VERSION "HNNBNNNYNNNNNNNNNNNNNNNNNNNNNNNNNNNNNNNNNN/4/%%%/4/'%**4NNN///"

NS_ :

BS_:

BU_: ADR_PAG_X2 BAP_Tester GW_App_PAG_PF GW_Routing_PAG_PF Klima_PAG_PF Klimakomp_Dash_PAG_PF Kombi_PAG_PF Miko_PAG_X2 OCU_PAG_PF RDK_High_PAG_PF

BO_ 192 ADR_01_PAG: 8 ADR_PAG_X2
 SG_ Adr_Clima_Mono : 0|1@1+ (1,0) [0|1] ""  Miko_PAG_X2
 SG_ Adr_T_LVT_O : 1|1@1+ (1,0) [0|1] "" Vector__XXX
 SG_ Adr_T_LVT_M : 2|1@1+ (1,0) [0|1] "" Vector__XXX
 SG_ Adr_T_LVT_U : 3|1@1+ (1,0) [0|1] "" Vector__XXX
 SG_ Adr_AC_Menue_LED_an : 4|1@1+ (1,0) [0|1] ""  Miko_PAG_X2
 SG_ Adr_Phone_LED_an : 5|1@1+ (1,0) [0|1] ""  Miko_PAG_X2
 SG_ Adr_Media_LED_an : 6|1@1+ (1,0) [0|1] ""  Miko_PAG_X2
 SG_ Adr_Tuner_LED_an : 7|1@1+ (1,0) [0|1] ""  Miko_PAG_X2
 SG_ Adr_Car_LED_an : 8|1@1+ (1,0) [0|1] ""  Miko_PAG_X2
 SG_ Adr_Info_LED_an : 9|1@1+ (1,0) [0|1] ""  Miko_PAG_X2
 SG_ Adr_Navi_LED_an : 10|1@1+ (1,0) [0|1] ""  Miko_PAG_X2
 SG_ Adr_Alive_Cnt : 11|4@1+ (1,0) [0|15] ""  Miko_PAG_X2
 SG_ Adr_Pos_En : 15|1@1+ (1,0) [0|1] ""  Miko_PAG_X2
 SG_ Adr_Display_Status : 16|1@1+ (1,0) [0|1] ""  Miko_PAG_X2
 SG_ Adr_Active_Character_Page : 17|4@1+ (1,0) [0|15] ""  Miko_PAG_X2
 SG_ Adr_Chr_Mode : 40|8@1+ (1,0) [0|255] ""  Miko_PAG_X2
 SG_ Adr_Gst_Mode : 48|16@1+ (1,0) [0|65535] ""  Miko_PAG_X2

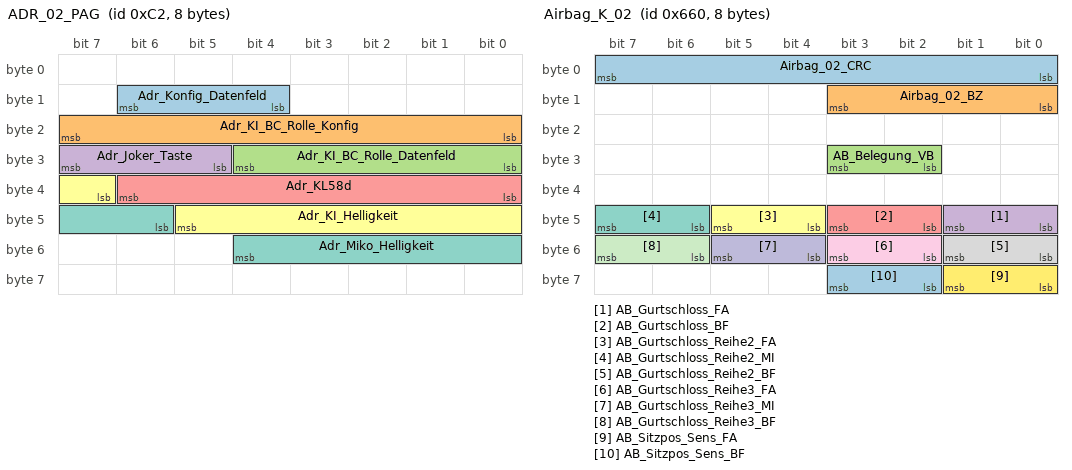
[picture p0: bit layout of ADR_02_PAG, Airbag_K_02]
BO_ 194 ADR_02_PAG: 8 ADR_PAG_X2
 SG_ Adr_Konfig_Datenfeld : 12|3@1+ (1,0) [0|7] ""  Kombi_PAG_PF
 SG_ Adr_KI_BC_Rolle_Konfig : 16|8@1+ (1,0) [0|255] ""  Kombi_PAG_PF
 SG_ Adr_KI_BC_Rolle_Datenfeld : 24|5@1+ (1,0) [0|31] ""  Kombi_PAG_PF
 SG_ Adr_Joker_Taste : 29|3@1+ (1,0) [0|7] ""  Kombi_PAG_PF
 SG_ Adr_KL58d : 32|7@1+ (1,0) [0|100] "Unit_PerCent"  Kombi_PAG_PF
 SG_ Adr_KI_Helligkeit : 39|7@1+ (1,0) [0|100] "Unit_PerCent"  Kombi_PAG_PF
 SG_ Adr_Miko_Helligkeit : 46|7@1+ (1,0) [0|100] "Unit_PerCent"  Miko_PAG_X2

BO_ 64 Airbag_01: 8 GW_Routing_PAG_PF
 SG_ Airbag_01_CHK : 0|8@1+ (1,0) [0|255] "" Vector__XXX
 SG_ Airbag_01_BZ : 8|4@1+ (1,0) [0|15] "" Vector__XXX
 SG_ AB_RGS_Anst : 12|4@1+ (1,0) [0|15] "" Vector__XXX
 SG_ AB_Front_Crash : 16|1@1+ (1,0) [0|1] "" Vector__XXX
 SG_ AB_Heck_Crash : 17|1@1+ (1,0) [0|1] "" Vector__XXX
 SG_ AB_SF_Crash : 18|1@1+ (1,0) [0|1] "" Vector__XXX
 SG_ AB_SB_Crash : 19|1@1+ (1,0) [0|1] "" Vector__XXX
 SG_ AB_Rollover_Crash : 20|1@1+ (1,0) [0|1] "" Vector__XXX
 SG_ AB_Crash_Int : 21|3@1+ (1,0) [0|7] "" Vector__XXX
 SG_ AB_Lampe : 24|1@1+ (1,0) [0|1] ""  Kombi_PAG_PF
 SG_ AB_Deaktiviert : 25|1@1+ (1,0) [0|1] "" Vector__XXX
 SG_ AB_VB_deaktiviert : 26|1@1+ (1,0) [0|1] ""  Kombi_PAG_PF
 SG_ AB_Systemfehler : 27|1@1+ (1,0) [0|1] ""  Kombi_PAG_PF
 SG_ AB_Diagnose : 28|1@1+ (1,0) [0|1] "" Vector__XXX
 SG_ AB_Stellgliedtest : 29|1@1+ (1,0) [0|1] "" Vector__XXX
 SG_ AB_Erh_Auf_VB : 30|2@1+ (1,0) [0|3] "" Vector__XXX
 SG_ AB_Gurtwarn_VF : 32|1@1+ (1,0) [0|1] ""  Kombi_PAG_PF
 SG_ AB_Gurtwarn_VB : 33|1@1+ (1,0) [0|1] ""  Kombi_PAG_PF
 SG_ AB_Anzeige_Fussg : 34|2@1+ (1,0) [0|3] ""  Kombi_PAG_PF
 SG_ AB_Texte_AKS : 36|2@1+ (1,0) [0|3] "" Vector__XXX
 SG_ AB_PAO_Leuchte_Anf : 38|1@1+ (1,0) [0|1] "" Vector__XXX
 SG_ AB_MKB_gueltig : 39|1@1+ (1,0) [0|1] "" Vector__XXX
 SG_ AB_Versorgungsspannung : 41|1@1+ (1,0) [0|1] "" Vector__XXX
 SG_ AB_Deaktivierung_HV : 42|3@1+ (1,0) [0|7] "" Vector__XXX
 SG_ AB_EDR_Trigger : 45|2@1+ (1,0) [0|3] "" Vector__XXX
 SG_ AB_KD_Fehler : 63|1@1+ (1,0) [0|1] "" Vector__XXX

BO_ 1632 Airbag_K_02: 8 GW_Routing_PAG_PF
 SG_ Airbag_02_CRC : 0|8@1+ (1,0) [0|255] "" Vector__XXX
 SG_ Airbag_02_BZ : 8|4@1+ (1,0) [0|15] "" Vector__XXX
 SG_ AB_Belegung_VB : 26|2@1+ (1,0) [0|3] "" Vector__XXX
 SG_ AB_Gurtschloss_FA : 40|2@1+ (1,0) [0|3] ""  Kombi_PAG_PF
 SG_ AB_Gurtschloss_BF : 42|2@1+ (1,0) [0|3] "" Vector__XXX
 SG_ AB_Gurtschloss_Reihe2_FA : 44|2@1+ (1,0) [0|3] "" Vector__XXX
 SG_ AB_Gurtschloss_Reihe2_MI : 46|2@1+ (1,0) [0|3] "" Vector__XXX
 SG_ AB_Gurtschloss_Reihe2_BF : 48|2@1+ (1,0) [0|3] "" Vector__XXX
 SG_ AB_Gurtschloss_Reihe3_FA : 50|2@1+ (1,0) [0|3] "" Vector__XXX
 SG_ AB_Gurtschloss_Reihe3_MI : 52|2@1+ (1,0) [0|3] "" Vector__XXX
 SG_ AB_Gurtschloss_Reihe3_BF : 54|2@1+ (1,0) [0|3] "" Vector__XXX
 SG_ AB_Sitzpos_Sens_FA : 56|2@1+ (1,0) [0|3] "" Vector__XXX
 SG_ AB_Sitzpos_Sens_BF : 58|2@1+ (1,0) [0|3] "" Vector__XXX

BO_ 1490 BAP_ASG_12: 8 OCU_PAG_PF
 SG_ BAP_D2_Header : 0|8@1+ (1,0) [0|255] ""  GW_Routing_PAG_PF

BO_ 1491 BAP_ASG_13: 8 Kombi_PAG_PF
 SG_ BAP_D3_Header : 0|8@1+ (1,0) [0|255] ""  GW_Routing_PAG_PF

BO_ 1492 BAP_ASG_14: 8 GW_Routing_PAG_PF
 SG_ BAP_D4_Header : 0|8@1+ (1,0) [0|255] ""  Kombi_PAG_PF

BO_ 1493 BAP_ASG_15: 8 OCU_PAG_PF
 SG_ BAP_D5_Header : 0|8@1+ (1,0) [0|255] ""  Kombi_PAG_PF

BO_ 1565 BAP_BatteryControl: 8 GW_Routing_PAG_PF
 SG_ BAP_1D_Header : 0|8@1+ (1,0) [0|255] ""  Kombi_PAG_PF,OCU_PAG_PF

BO_ 1599 BAP_Debug_Cmd: 8 BAP_Tester
 SG_ BAP_Debug_Cmd : 0|16@1+ (1,0) [0|65535] ""  Kombi_PAG_PF,OCU_PAG_PF

BO_ 1598 BAP_Debug_Data: 8 Kombi_PAG_PF
 SG_ BAP_Debug_Data : 0|64@1+ (1,0) [0|1.84467440737096E+019] ""  BAP_Tester

BO_ 1583 BAP_Uhrzeit: 8 Kombi_PAG_PF
 SG_ BAP_2F_Header : 0|8@1+ (1,0) [0|255] ""  GW_Routing_PAG_PF,OCU_PAG_PF

BO_ 1634 BCM1_02: 8 GW_Routing_PAG_PF
 SG_ BCM1_Bremsbelag_Warn : 0|1@1+ (1,0) [0|1] "" Vector__XXX
 SG_ BCM1_Bremsfluessigkeit_Warn : 1|1@1+ (1,0) [0|1] ""  Kombi_PAG_PF
 SG_ BCM1_Licht_Warn : 2|1@1+ (1,0) [0|1] ""  Kombi_PAG_PF
 SG_ BCM1_Waschwasser_Warn : 3|1@1+ (1,0) [0|1] ""  Kombi_PAG_PF
 SG_ BCM1_Kuehlmittel_Warn : 4|1@1+ (1,0) [0|1] "" Vector__XXX
 SG_ BCM1_Gleitende_Leuchtw_Anf : 5|1@1+ (1,0) [0|1] "" Vector__XXX
 SG_ LV_Aussenlicht_def : 6|1@1+ (1,0) [0|1] ""  Kombi_PAG_PF
 SG_ LV_AFL_defekt : 7|1@1+ (1,0) [0|1] ""  Kombi_PAG_PF
 SG_ BCM1_Handbremse_Schalter : 8|1@1+ (1,0) [0|1] "" Vector__XXX
 SG_ BCM1_MH_Schalter : 9|1@1+ (1,0) [0|1] ""  Kombi_PAG_PF,OCU_PAG_PF
 SG_ BCM1_MH_WIV_Schalter : 10|1@1+ (1,0) [0|1] "" Vector__XXX
 SG_ BCM1_Oeldruck_Schalter : 11|1@1+ (1,0) [0|1] "" Vector__XXX
 SG_ BCM1_Kl_15_HW_erkannt : 12|1@1+ (1,0) [0|1] "" Vector__XXX
 SG_ BCM1_Lenksaeule_aktiv : 13|1@1+ (1,0) [0|1] "" Vector__XXX
 SG_ BCM1_Oeldruck_Schalter_2 : 14|1@1+ (1,0) [0|1] "" Vector__XXX
 SG_ BCM1_SRA_aktiv : 15|1@1+ (1,0) [0|1] "" Vector__XXX
 SG_ LV_Standlicht_Anzeige : 16|1@1+ (1,0) [0|1] ""  ADR_PAG_X2,Kombi_PAG_PF
 SG_ LV_Abblendlicht_Anzeige : 17|1@1+ (1,0) [0|1] ""  Kombi_PAG_PF
 SG_ LV_Fernlicht_Anzeige : 18|1@1+ (1,0) [0|1] ""  Kombi_PAG_PF
 SG_ LV_Nebellicht_Anzeige : 19|1@1+ (1,0) [0|1] "" Vector__XXX
 SG_ LV_Nebelschlusslicht_Anzeige : 20|1@1+ (1,0) [0|1] ""  Kombi_PAG_PF
 SG_ LV_Tagfahrlicht_Anzeige : 21|1@1+ (1,0) [0|1] ""  Kombi_PAG_PF
 SG_ LV_AFL_aktiv_Anzeige : 22|1@1+ (1,0) [0|1] "" Vector__XXX
 SG_ BCM1_Licht_Dunkelheit_aktiv : 23|1@1+ (1,0) [0|1] "" Vector__XXX
 SG_ LV_Blinker_li_def : 24|1@1+ (1,0) [0|1] ""  Kombi_PAG_PF
 SG_ LV_Standlicht_li_def : 25|1@1+ (1,0) [0|1] ""  Kombi_PAG_PF
 SG_ LV_Abblendlicht_li_def : 26|1@1+ (1,0) [0|1] ""  Kombi_PAG_PF
 SG_ LV_Fernlicht_li_def : 27|1@1+ (1,0) [0|1] ""  Kombi_PAG_PF
 SG_ LV_Nebellicht_li_def : 28|1@1+ (1,0) [0|1] ""  Kombi_PAG_PF
 SG_ LV_Blk_li_Seite_def : 29|1@1+ (1,0) [0|1] ""  Kombi_PAG_PF
 SG_ LV_Tagfahrlicht_li_def : 30|1@1+ (1,0) [0|1] "" Vector__XXX
 SG_ BCM1_GLW_Fernlicht_Anf : 31|1@1+ (1,0) [0|1] "" Vector__XXX
 SG_ LV_Abblendlicht_TFL_li_def : 32|1@1+ (1,0) [0|1] "" Vector__XXX
 SG_ LV_Nebellicht_TFL_li_def : 33|1@1+ (1,0) [0|1] "" Vector__XXX
 SG_ LV_Standlicht_TFL_li_def : 34|1@1+ (1,0) [0|1] "" Vector__XXX
 SG_ LV_Abblend_Fernlicht_li_def : 35|1@1+ (1,0) [0|1] "" Vector__XXX
 SG_ LV_FLA_aktiv_Anzeige : 36|1@1+ (1,0) [0|1] ""  Kombi_PAG_PF
 SG_ LV_FLA_defekt : 37|1@1+ (1,0) [0|1] ""  Kombi_PAG_PF
 SG_ LV_FLA_Sensor_blockiert : 38|1@1+ (1,0) [0|1] ""  Kombi_PAG_PF
 SG_ BCM1_EasyEntry_Status : 39|1@1+ (1,0) [0|1] "" Vector__XXX
 SG_ LV_Blinker_re_def : 40|1@1+ (1,0) [0|1] ""  Kombi_PAG_PF
 SG_ LV_Standlicht_re_def : 41|1@1+ (1,0) [0|1] ""  Kombi_PAG_PF
 SG_ LV_Abblendlicht_re_def : 42|1@1+ (1,0) [0|1] ""  Kombi_PAG_PF
 SG_ LV_Fernlicht_re_def : 43|1@1+ (1,0) [0|1] ""  Kombi_PAG_PF
 SG_ LV_Nebellicht_re_def : 44|1@1+ (1,0) [0|1] ""  Kombi_PAG_PF
 SG_ LV_Blk_re_Seite_def : 45|1@1+ (1,0) [0|1] ""  Kombi_PAG_PF
 SG_ LV_Tagfahrlicht_re_def : 46|1@1+ (1,0) [0|1] "" Vector__XXX
 SG_ BCM1_Adaptive_Lichtvert_Anf : 47|1@1+ (1,0) [0|1] "" Vector__XXX
 SG_ LV_Abblendlicht_TFL_re_def : 48|1@1+ (1,0) [0|1] "" Vector__XXX
 SG_ LV_Nebellicht_TFL_re_def : 49|1@1+ (1,0) [0|1] "" Vector__XXX
 SG_ LV_Standlicht_TFL_re_def : 50|1@1+ (1,0) [0|1] "" Vector__XXX
 SG_ LV_Abblend_Fernlicht_re_def : 51|1@1+ (1,0) [0|1] "" Vector__XXX
 SG_ BCM1_EasyEntry_texte : 52|2@1+ (1,0) [0|3] "" Vector__XXX
 SG_ HYB_Anf_E_Mode : 54|1@1+ (1,0) [0|1] "" Vector__XXX
 SG_ UGDO_Function : 56|3@1+ (1,0) [0|7] "" Vector__XXX
 SG_ UGDO_LED_Code : 59|5@1+ (1,0) [0|31] "" Vector__XXX

BO_ 1697 BCM1_03_PAG: 8 GW_Routing_PAG_PF
 SG_ BCM1_W_ELV : 0|1@1+ (1,0) [0|1] ""  Kombi_PAG_PF
 SG_ BCM1_W_Blinker_HR_def : 1|1@1+ (1,0) [0|1] ""  Kombi_PAG_PF
 SG_ BCM1_W_Blinker_HL_def : 2|1@1+ (1,0) [0|1] ""  Kombi_PAG_PF
 SG_ BCM1_W_LWR_def : 3|1@1+ (1,0) [0|1] ""  Kombi_PAG_PF
 SG_ BCM1_W_Parklicht : 4|1@1+ (1,0) [0|1] ""  Kombi_PAG_PF
 SG_ BCM1_ZV_Horn : 5|2@1+ (1,0) [0|3] "" Vector__XXX
 SG_ BCM1_St_ZV : 8|3@1+ (1,0) [0|7] ""  Klima_PAG_PF,OCU_PAG_PF
 SG_ BCM1_FSH_aktiv : 11|1@1+ (1,0) [0|1] ""  Klima_PAG_PF
 SG_ BCM1_Kurvenlicht_li_Anf : 12|1@1+ (1,0) [0|1] "" Vector__XXX
 SG_ BCM1_Kurvenlicht_re_Anf : 13|1@1+ (1,0) [0|1] "" Vector__XXX
 SG_ BCM1_DWA_Anf : 14|2@1+ (1,0) [0|3] "" Vector__XXX
 SG_ LDS_TF_Licht : 16|1@1+ (1,0) [0|1] "" Vector__XXX
 SG_ LDS_AF_Licht : 17|1@1+ (1,0) [0|1] "" Vector__XXX
 SG_ LDS_STA_Licht : 18|1@1+ (1,0) [0|1] "" Vector__XXX
 SG_ LDS_Fahr_Licht : 19|1@1+ (1,0) [0|1] "" Vector__XXX
 SG_ LDS_Error : 20|1@1+ (1,0) [0|1] "" Vector__XXX
 SG_ LDS_N_Licht : 21|1@1+ (1,0) [0|1] "" Vector__XXX
 SG_ LDS_NS_Licht : 22|1@1+ (1,0) [0|1] "" Vector__XXX
 SG_ LDS_Nightvision : 23|1@1+ (1,0) [0|1] "" Vector__XXX
 SG_ BCM1_Geschw_PSM_erkannt : 24|1@1+ (1,0) [0|1] "" Vector__XXX
 SG_ BCM1_Heckklappe_entriegeln : 25|1@1+ (1,0) [0|1] "" Vector__XXX
 SG_ BCM1_CH_aktiv : 26|1@1+ (1,0) [0|1] "" Vector__XXX
 SG_ BCM1_LH_aktiv : 27|1@1+ (1,0) [0|1] "" Vector__XXX
 SG_ BCM1_Trunkentrapment_auf : 28|1@1+ (1,0) [0|1] "" Vector__XXX
 SG_ BCM1_Trunkentrapment_zu : 29|1@1+ (1,0) [0|1] "" Vector__XXX
 SG_ BCM1_St_Handschuhfach : 30|1@1+ (1,0) [0|1] "" Vector__XXX
 SG_ BCM1_St_Scheinwerferdiebstahl : 31|1@1+ (1,0) [0|1] "" Vector__XXX
 SG_ BCM1_Seitenmarker_li_def : 32|1@1+ (1,0) [0|1] ""  Kombi_PAG_PF
 SG_ BCM1_Seitenmarker_re_def : 33|1@1+ (1,0) [0|1] ""  Kombi_PAG_PF
 SG_ LS_Licht_ein : 34|1@1+ (1,0) [0|1] "" Vector__XXX
 SG_ LS_Licht_ein_invers : 35|1@1+ (1,0) [0|1] "" Vector__XXX
 SG_ LS_Dunkel : 36|1@1+ (1,0) [0|1] "" Vector__XXX
 SG_ BCM1_T_Verrieg_TAG : 37|3@1+ (1,0) [0|7] "" Vector__XXX
 SG_ LS_Error : 40|1@1+ (1,0) [0|1] "" Vector__XXX
 SG_ LS_Autobahnfahrlicht : 41|1@1+ (1,0) [0|1] "" Vector__XXX
 SG_ RS_Error : 42|1@1+ (1,0) [0|1] "" Vector__XXX
 SG_ RS_Regenfahrlicht : 43|1@1+ (1,0) [0|1] "" Vector__XXX
 SG_ BCM1_Tankklappe_entriegeln : 44|2@1+ (1,0) [0|3] "" Vector__XXX
 SG_ BCM1_Anf_AbschaltfreigabeKL15 : 46|1@1+ (1,0) [0|1] "" Vector__XXX
 SG_ BCM1_St_Timer_KL15_Abschalt : 47|1@1+ (1,0) [0|1] "" Vector__XXX

BO_ 1409 BCM2_02: 8 GW_Routing_PAG_PF
 SG_ BCM_FH_Freigabe : 0|1@1+ (1,0) [0|1] "" Vector__XXX
 SG_ BCM_Komfortfkt_Freigabe : 1|1@1+ (1,0) [0|1] "" Vector__XXX
 SG_ BCM_HSK_Freigabe : 2|1@1+ (1,0) [0|1] "" Vector__XXX
 SG_ BCM_Verdeck_Freigabe : 3|1@1+ (1,0) [0|1] "" Vector__XXX
 SG_ BCM2_Status_Timer_KL15_Abschalt : 4|1@1+ (1,0) [0|1] "" Vector__XXX
 SG_ BCM2_Anford_AbschaltfreigabeKL15 : 5|1@1+ (1,0) [0|1] "" Vector__XXX
 SG_ BCM2_Unterdr_Zuendungsmeldung : 6|1@1+ (1,0) [0|1] "" Vector__XXX
 SG_ BCM2_KL15_Absch_FT : 7|1@1+ (1,0) [0|1] "" Vector__XXX
 SG_ ZV_ist_Zustand_verfuegbar : 8|1@1+ (1,0) [0|1] "" Vector__XXX
 SG_ BCM2_P_verriegelt : 9|1@1+ (1,0) [0|1] "" Vector__XXX
 SG_ ZV_verriegelt_intern_ist : 10|1@1+ (1,0) [0|1] "" Vector__XXX
 SG_ ZV_verriegelt_extern_ist : 11|1@1+ (1,0) [0|1] "" Vector__XXX
 SG_ ZV_verriegelt_intern_soll : 12|1@1+ (1,0) [0|1] "" Vector__XXX
 SG_ ZV_verriegelt_extern_soll : 13|1@1+ (1,0) [0|1] "" Vector__XXX
 SG_ ZV_gesafet_extern_ist : 14|1@1+ (1,0) [0|1] "" Vector__XXX
 SG_ ZV_gesafet_extern_soll : 15|1@1+ (1,0) [0|1] "" Vector__XXX
 SG_ ZV_FT_offen : 16|1@1+ (1,0) [0|1] ""  OCU_PAG_PF
 SG_ ZV_BT_offen : 17|1@1+ (1,0) [0|1] ""  OCU_PAG_PF
 SG_ ZV_HL_offen : 18|1@1+ (1,0) [0|1] ""  OCU_PAG_PF
 SG_ ZV_HR_offen : 19|1@1+ (1,0) [0|1] ""  OCU_PAG_PF
 SG_ ZV_HD_offen : 20|1@1+ (1,0) [0|1] ""  OCU_PAG_PF
 SG_ ZV_Turen_HD_zu : 21|1@1+ (1,0) [0|1] ""  OCU_PAG_PF
 SG_ ZV_Einzeltuerentriegelung : 22|1@1+ (1,0) [0|1] "" Vector__XXX
 SG_ ZV_Heckeinzelentriegelung : 23|1@1+ (1,0) [0|1] "" Vector__XXX
 SG_ BCM_ValetTaster_Fkts_LED : 24|1@1+ (1,0) [0|1] "" Vector__XXX
 SG_ BCM_HHS_aktiv : 25|1@1+ (1,0) [0|1] "" Vector__XXX
 SG_ BCM_Spg_Hzg_Ein : 26|1@1+ (1,0) [0|1] "" Vector__XXX
 SG_ ZV_HS_offen : 27|1@1+ (1,0) [0|1] ""  OCU_PAG_PF
 SG_ ZZH_Endlage_oben : 28|1@1+ (1,0) [0|1] "" Vector__XXX
 SG_ ZZH_Endlage_unten : 29|1@1+ (1,0) [0|1] "" Vector__XXX
 SG_ ZZH_Endlage_unplausibel : 30|1@1+ (1,0) [0|1] "" Vector__XXX
 SG_ BCM2_KD_Fehler : 31|1@1+ (1,0) [0|1] "" Vector__XXX
 SG_ NGS_aktiv : 32|1@1+ (1,0) [0|1] "" Vector__XXX
 SG_ IRUE_aktiv : 33|1@1+ (1,0) [0|1] "" Vector__XXX
 SG_ DWA_aktiv : 34|1@1+ (1,0) [0|1] "" Vector__XXX
 SG_ Komp_Schutz_aktiv : 35|1@1+ (1,0) [0|1] "" Vector__XXX
 SG_ NGS_Taster_Fkts_LED : 36|1@1+ (1,0) [0|1] "" Vector__XXX
 SG_ IRUE_Taster_Fkts_LED : 37|1@1+ (1,0) [0|1] "" Vector__XXX
 SG_ HD_Drehfalle_S1 : 38|1@1+ (1,0) [0|1] "" Vector__XXX
 SG_ HD_Sperrklinke_S2 : 39|1@1+ (1,0) [0|1] "" Vector__XXX
 SG_ BCM_Verbau_Heckrollo : 40|1@1+ (1,0) [0|1] "" Vector__XXX
 SG_ BCM2_EZS_gedrueckt : 41|1@1+ (1,0) [0|1] "" Vector__XXX
 SG_ BCM2_SST_gedrueckt : 42|1@1+ (1,0) [0|1] "" Vector__XXX
 SG_ LIM_alt : 43|1@1+ (1,0) [0|1] "" Vector__XXX
 SG_ LIM_Innenbeleuchtung_V_aktiv : 44|1@1+ (1,0) [0|1] "" Vector__XXX
 SG_ LIM_Innenbeleuchtung_aktiv : 45|1@1+ (1,0) [0|1] "" Vector__XXX
 SG_ LIM_Taster_Rollolicht_hl : 46|1@1+ (1,0) [0|1] "" Vector__XXX
 SG_ LIM_Taster_Rollolicht_hr : 47|1@1+ (1,0) [0|1] "" Vector__XXX
 SG_ BCM_Sperrklinke_FT : 48|1@1+ (1,0) [0|1] "" Vector__XXX
 SG_ LIM_Taster_Rollolicht_V : 49|1@1+ (1,0) [0|1] "" Vector__XXX
 SG_ BCM_Tankwunsch : 50|2@1+ (1,0) [0|3] "" Vector__XXX
 SG_ ZV_Tankklappe_offen : 52|1@1+ (1,0) [0|1] "" Vector__XXX
 SG_ KST_Fahrer_Hinweise : 56|3@1+ (1,0) [0|7] "" Vector__XXX
 SG_ KST_Warn_P1_ZST_def : 59|1@1+ (1,0) [0|1] "" Vector__XXX
 SG_ KST_Warn_P2_ZST_def : 60|1@1+ (1,0) [0|1] "" Vector__XXX
 SG_ KST_Prio_Warn_03 : 61|1@1+ (1,0) [0|1] "" Vector__XXX
 SG_ KST_Prio_Warn_04 : 62|1@1+ (1,0) [0|1] "" Vector__XXX
 SG_ KST_Prio_Warn_05 : 63|1@1+ (1,0) [0|1] "" Vector__XXX

BO_ 900 BCM2_03_PAG: 8 GW_Routing_PAG_PF
 SG_ BCM2_S_RF_Licht : 0|1@1+ (1,0) [0|1] "" Vector__XXX
 SG_ BCM2_ZZH_Endlage_oben : 1|1@1+ (1,0) [0|1] "" Vector__XXX
 SG_ BCM2_ZZH_Endlage_unten : 2|1@1+ (1,0) [0|1] "" Vector__XXX
 SG_ BCM2_W_VTS_Meldung : 3|1@1+ (1,0) [0|1] "" Vector__XXX
 SG_ BCM2_W_TagfahrL_re_def : 4|1@1+ (1,0) [0|1] ""  Kombi_PAG_PF
 SG_ BCM2_W_TagfahrL_li_def : 5|1@1+ (1,0) [0|1] ""  Kombi_PAG_PF
 SG_ BCM2_W_KurvL_re_def : 6|1@1+ (1,0) [0|1] "" Vector__XXX
 SG_ BCM2_W_KurvL_li_def : 7|1@1+ (1,0) [0|1] "" Vector__XXX
 SG_ BCM2_W_Kuehlwasserstand : 8|1@1+ (1,0) [0|1] ""  Kombi_PAG_PF
 SG_ BCM2_W_HSpoiler_3 : 10|1@1+ (1,0) [0|1] "" Vector__XXX
 SG_ BCM2_W_HSpoiler_4 : 11|1@1+ (1,0) [0|1] "" Vector__XXX
 SG_ BCM2_W_HSpoiler_1 : 12|1@1+ (1,0) [0|1] ""  Kombi_PAG_PF
 SG_ BCM2_W_HSpoiler_2 : 13|1@1+ (1,0) [0|1] ""  Kombi_PAG_PF
 SG_ BCM2_W_Dach_n_geschl : 14|1@1+ (1,0) [0|1] ""  Klima_PAG_PF,Kombi_PAG_PF
 SG_ BCM2_Bremsbelag_Warn : 15|1@1+ (1,0) [0|1] ""  Kombi_PAG_PF
 SG_ BCM2_EBD_Warnblinken_Anf : 16|1@1+ (1,0) [0|1] "" Vector__XXX
 SG_ BCM2_PassiveArming_aktiv : 17|1@1+ (1,0) [0|1] "" Vector__XXX
 SG_ DK_St_PAO_Leuchte : 18|2@1+ (1,0) [0|3] "" Vector__XXX
 SG_ DK_PAO_Signalzaehler : 20|4@1+ (1,0) [0|15] "" Vector__XXX
 SG_ BCM2_Hauptraste_HK_aktiv : 24|1@1+ (1,0) [0|1] ""  Klima_PAG_PF
 SG_ BCM2_Vorraste_HK_aktiv : 25|1@1+ (1,0) [0|1] "" Vector__XXX
 SG_ BCM2_Softtouch_betaetigt : 26|1@1+ (1,0) [0|1] "" Vector__XXX
 SG_ BCM2_TrunkEntrapment_Anf : 27|1@1+ (1,0) [0|1] "" Vector__XXX
 SG_ BCM2_HsHzg_aktiv : 28|1@1+ (1,0) [0|1] ""  Klima_PAG_PF
 SG_ BCM2_St_LED_HSpoiler : 29|2@1+ (1,0) [0|3] ""  Klima_PAG_PF
 SG_ BCM2_DWA_aktiv : 31|1@1+ (1,0) [0|1] ""  ADR_PAG_X2
 SG_ BCM2_Alarmausgabe : 32|1@1+ (1,0) [0|1] "" Vector__XXX
 SG_ BCM2_Alarmblinken : 33|1@1+ (1,0) [0|1] "" Vector__XXX
 SG_ BCM2_Heckwaschen_Anf : 34|1@1+ (1,0) [0|1] "" Vector__XXX
 SG_ BCM2_Geschw_PSM_erkannt : 35|1@1+ (1,0) [0|1] "" Vector__XXX
 SG_ DK_T_Resrv : 36|1@1+ (1,0) [0|1] "" Vector__XXX
 SG_ DK_F_T_Resrv : 37|1@1+ (1,0) [0|1] "" Vector__XXX
 SG_ DK_T_PDC : 38|1@1+ (1,0) [0|1] "" Vector__XXX
 SG_ DK_F_T_PDC : 39|1@1+ (1,0) [0|1] "" Vector__XXX
 SG_ BCM2_W_SpoilerInfo : 40|3@1+ (1,0) [0|7] ""  Kombi_PAG_PF
 SG_ BCM2_Rollo_Bew : 43|1@1+ (1,0) [0|1] ""  Klima_PAG_PF
 SG_ BCM2_Rollo_Pos : 44|2@1+ (1,0) [0|3] "" Vector__XXX
 SG_ BCM_Handshake_STH : 46|1@1+ (1,0) [0|1] "" Vector__XXX
 SG_ BCM2_PAG_KD_Fehler : 47|1@1+ (1,0) [0|1] "" Vector__XXX
 SG_ BCM2_St_DCDCWandler : 48|4@1+ (1,0) [0|15] "" Vector__XXX
 SG_ BCM2_T_Deckel_Vorne : 52|1@1+ (1,0) [0|1] "" Vector__XXX
 SG_ BCM1_ELV_enable_soll_2 : 53|1@1+ (1,0) [0|1] "" Vector__XXX
 SG_ BCM1_ELV_enable_Fehler_2 : 54|1@1+ (1,0) [0|1] "" Vector__XXX
 SG_ BCM2_IL_Dimmung : 56|8@1+ (1,0) [0|100] "Unit_PerCent" Vector__XXX

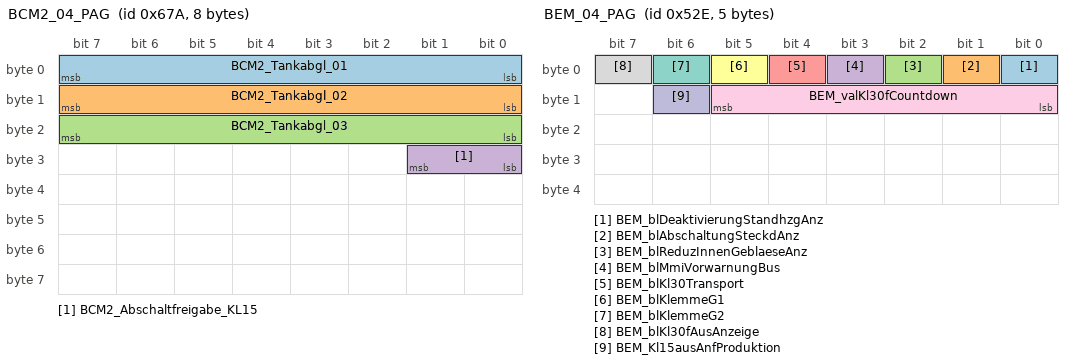
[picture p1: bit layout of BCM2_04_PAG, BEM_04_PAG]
BO_ 1658 BCM2_04_PAG: 8 GW_Routing_PAG_PF
 SG_ BCM2_Tankabgl_01 : 0|8@1+ (1,0) [0|255] ""  Kombi_PAG_PF
 SG_ BCM2_Tankabgl_02 : 8|8@1+ (1,0) [0|255] ""  Kombi_PAG_PF
 SG_ BCM2_Tankabgl_03 : 16|8@1+ (1,0) [0|255] ""  Kombi_PAG_PF
 SG_ BCM2_Abschaltfreigabe_KL15 : 24|2@1+ (1,0) [0|3] "" Vector__XXX

BO_ 1635 BEM_02: 8 GW_App_PAG_PF
 SG_ BEM_02_Abschaltstufen : 0|3@1+ (1,0) [0|7] ""  ADR_PAG_X2,Klima_PAG_PF
 SG_ BEM_STH_Zielzeit : 3|4@1+ (5,0) [0|60] "Unit_Minut" Vector__XXX
 SG_ BEM_MMI_Vorwarnung : 7|1@1+ (1,0) [0|1] "" Vector__XXX
 SG_ BEM_HL_Kontingentierung : 8|6@1+ (50,-1000) [-1000|1000] "Unit_Watt"  Klima_PAG_PF
 SG_ NVEM_Anf_SD_schalten : 15|1@1+ (1,0) [0|1] "" Vector__XXX
 SG_ BEM_Generatordiagnose : 16|2@1+ (1,0) [0|3] ""  Kombi_PAG_PF
 SG_ BEM_Red_Innengeblaese : 18|2@1+ (1,0) [0|3] ""  Klima_PAG_PF
 SG_ BEM_STH_Einschaltverbot : 20|1@1+ (1,0) [0|1] "" Vector__XXX
 SG_ BEM_HL_Regelung_Status : 21|3@1+ (1,0) [0|7] ""  Klima_PAG_PF
 SG_ BEM_Ladezustand : 24|4@1+ (10,0) [0|100] "Unit_PerCent"  Kombi_PAG_PF
 SG_ BEM_Batteriediagnose : 28|3@1+ (1,0) [0|7] ""  Kombi_PAG_PF
 SG_ MIB_Stromsparmodus : 31|1@1+ (1,0) [0|1] "" Vector__XXX
 SG_ BEM_DFM : 32|5@1+ (3.225,0.025) [0.025|100] "" Vector__XXX
 SG_ BEM_REK_aktiv : 37|1@1+ (1,0) [0|1] "" Vector__XXX
 SG_ BEM_EMLIN_ungueltig : 38|1@1+ (1,0) [0|1] "" Vector__XXX
 SG_ BEM_Batt_Ab : 39|1@1+ (1,0) [0|1] "" Vector__XXX
 SG_ BEM_UBDM : 40|8@1+ (0.05,5) [5.05|17.7] "Unit_Volt"  Kombi_PAG_PF
 SG_ BEM_UGenSoll : 48|6@1+ (0.1,10.6) [10.6|16] "Unit_Volt" Vector__XXX
 SG_ BEM_Anf_KL15_schalten : 54|2@1+ (1,0) [0|3] "" Vector__XXX

BO_ 1326 BEM_04_PAG: 5 GW_App_PAG_PF
 SG_ BEM_blDeaktivierungStandhzgAnz : 0|1@1+ (1,0) [0|1] "" Vector__XXX
 SG_ BEM_blAbschaltungSteckdAnz : 1|1@1+ (1,0) [0|1] ""  Kombi_PAG_PF
 SG_ BEM_blReduzInnenGeblaeseAnz : 2|1@1+ (1,0) [0|1] ""  Kombi_PAG_PF
 SG_ BEM_blMmiVorwarnungBus : 3|1@1+ (1,0) [0|1] "" Vector__XXX
 SG_ BEM_blKl30Transport : 4|1@1+ (1,0) [0|1] ""  Kombi_PAG_PF
 SG_ BEM_blKlemmeG1 : 5|1@1+ (1,0) [0|1] "" Vector__XXX
 SG_ BEM_blKlemmeG2 : 6|1@1+ (1,0) [0|1] "" Vector__XXX
 SG_ BEM_blKl30fAusAnzeige : 7|1@1+ (1,0) [0|1] ""  Kombi_PAG_PF
 SG_ BEM_valKl30fCountdown : 8|6@1+ (1,0) [0|63] "" Vector__XXX
 SG_ BEM_Kl15ausAnfProduktion : 14|1@1+ (1,0) [0|1] "" Vector__XXX

BO_ 867 Blinkmodi_01: 4 GW_Routing_PAG_PF
 SG_ BM_ZV_auf : 0|1@1+ (1,0) [0|1] "" Vector__XXX
 SG_ BM_ZV_zu : 1|1@1+ (1,0) [0|1] "" Vector__XXX
 SG_ BM_DWA_ein : 2|1@1+ (1,0) [0|1] "" Vector__XXX
 SG_ BM_DWA_Alarm : 3|1@1+ (1,0) [0|1] "" Vector__XXX
 SG_ BM_Crash : 4|1@1+ (1,0) [0|1] "" Vector__XXX
 SG_ BM_Panik : 5|1@1+ (1,0) [0|1] "" Vector__XXX
 SG_ BM_Not_Bremsung : 6|1@1+ (1,0) [0|1] "" Vector__XXX
 SG_ BM_GDO : 7|1@1+ (1,0) [0|1] "" Vector__XXX
 SG_ BM_links : 8|1@1+ (1,0) [0|1] "" Vector__XXX
 SG_ BM_rechts : 9|1@1+ (1,0) [0|1] "" Vector__XXX
 SG_ BM_Warnblinken : 10|1@1+ (1,0) [0|1] "" Vector__XXX
 SG_ BM_Autobahn : 11|1@1+ (1,0) [0|1] "" Vector__XXX
 SG_ BM_Taxi_Notalarm : 12|1@1+ (1,0) [0|1] "" Vector__XXX
 SG_ BM_Telematik : 13|1@1+ (1,0) [0|1] "" Vector__XXX
 SG_ BM_HD_Oeffnung_angelernt : 14|1@1+ (1,0) [0|1] "" Vector__XXX
 SG_ BM_WBT_Beleuchtung : 15|1@1+ (1,0) [0|1] "" Vector__XXX
 SG_ Blinken_li_Fzg_Takt : 16|1@1+ (1,0) [0|1] "" Vector__XXX
 SG_ Blinken_re_Fzg_Takt : 17|1@1+ (1,0) [0|1] "" Vector__XXX
 SG_ Blinken_li_Kombi_Takt : 18|1@1+ (1,0) [0|1] ""  Kombi_PAG_PF
 SG_ Blinken_re_Kombi_Takt : 19|1@1+ (1,0) [0|1] ""  Kombi_PAG_PF
 SG_ BM_NBA_n_codiert_n_aktiv : 20|1@1+ (1,0) [0|1] "" Vector__XXX
 SG_ BM_NBA_Status : 21|2@1+ (1,0) [0|3] "" Vector__XXX
 SG_ Blinken_FWB_aktiv : 23|1@1+ (1,0) [0|1] "" Vector__XXX

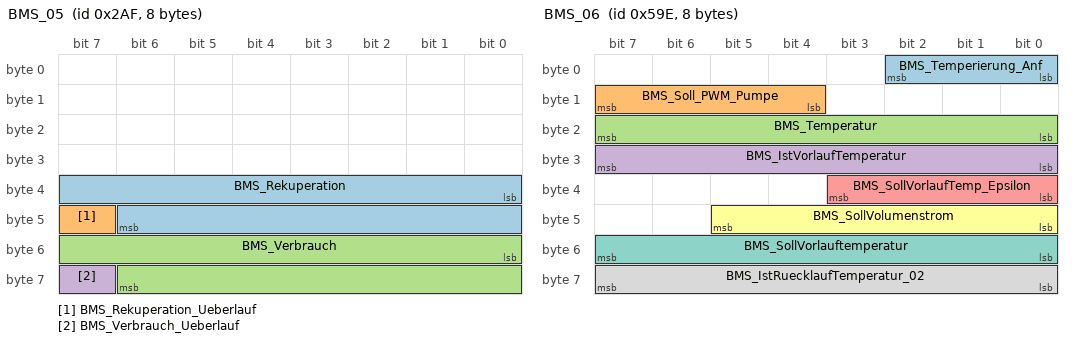
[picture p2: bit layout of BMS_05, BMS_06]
BO_ 687 BMS_05: 8 GW_Routing_PAG_PF
 SG_ BMS_Rekuperation : 32|15@1+ (10,0) [0|327670] "Unit_WattSecond"  Kombi_PAG_PF
 SG_ BMS_Rekuperation_Ueberlauf : 47|1@1+ (1,0) [0|1] ""  Kombi_PAG_PF
 SG_ BMS_Verbrauch : 48|15@1+ (10,0) [0|327670] "Unit_WattSecond"  Kombi_PAG_PF
 SG_ BMS_Verbrauch_Ueberlauf : 63|1@1+ (1,0) [0|1] ""  Kombi_PAG_PF

BO_ 1438 BMS_06: 8 GW_Routing_PAG_PF
 SG_ BMS_Temperierung_Anf : 0|3@1+ (1,0) [0|7] "" Vector__XXX
 SG_ BMS_Soll_PWM_Pumpe : 12|4@1+ (10,0) [0|100] "Unit_PerCent" Vector__XXX
 SG_ BMS_Temperatur : 16|8@1+ (0.5,-40) [-40|86.5] "Unit_DegreCelsi" Vector__XXX
 SG_ BMS_IstVorlaufTemperatur : 24|8@1+ (0.5,-40) [-40|86.5] "Unit_DegreCelsi"  Klima_PAG_PF
 SG_ BMS_SollVorlaufTemp_Epsilon : 32|4@1+ (2,0) [0|30] "Unit_DegreCelsi" Vector__XXX
 SG_ BMS_SollVolumenstrom : 40|6@1+ (1,0) [0|61] "" Vector__XXX
 SG_ BMS_SollVorlauftemperatur : 48|8@1+ (0.5,-40) [-40|86.5] "Unit_DegreCelsi"  Klima_PAG_PF
 SG_ BMS_IstRuecklaufTemperatur_02 : 56|8@1+ (0.5,-40) [-40|86.5] "Unit_DegreCelsi"  Klima_PAG_PF

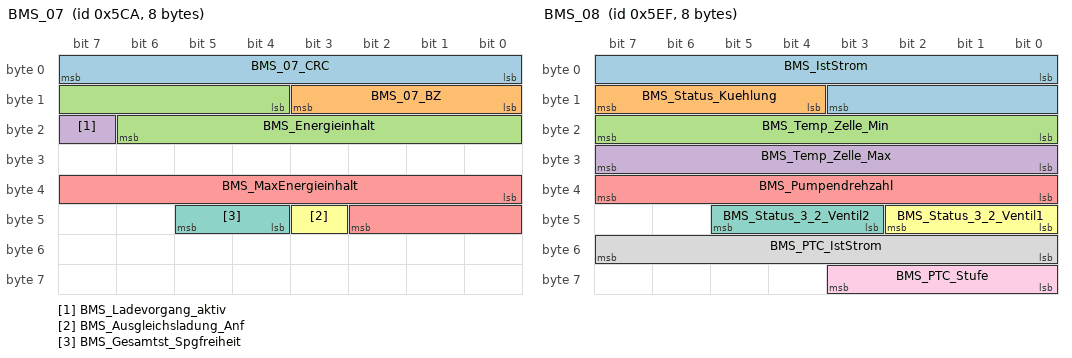
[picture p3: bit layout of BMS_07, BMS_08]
BO_ 1482 BMS_07: 8 GW_Routing_PAG_PF
 SG_ BMS_07_CRC : 0|8@1+ (1,0) [0|255] ""  Kombi_PAG_PF
 SG_ BMS_07_BZ : 8|4@1+ (1,0) [0|15] ""  Kombi_PAG_PF
 SG_ BMS_Energieinhalt : 12|11@1+ (50,0) [0|102250] "Unit_WattHour" Vector__XXX
 SG_ BMS_Ladevorgang_aktiv : 23|1@1+ (1,0) [0|1] "" Vector__XXX
 SG_ BMS_MaxEnergieinhalt : 32|11@1+ (50,0) [0|102250] "" Vector__XXX
 SG_ BMS_Ausgleichsladung_Anf : 43|1@1+ (1,0) [0|1] "" Vector__XXX
 SG_ BMS_Gesamtst_Spgfreiheit : 44|2@1+ (1,0) [0|3] ""  Kombi_PAG_PF

BO_ 1519 BMS_08: 8 GW_Routing_PAG_PF
 SG_ BMS_IstStrom : 0|12@1+ (0.25,-511) [-511|512.25] "Unit_Amper" Vector__XXX
 SG_ BMS_Status_Kuehlung : 12|4@1+ (1,0) [0|15] ""  Klima_PAG_PF,OCU_PAG_PF
 SG_ BMS_Temp_Zelle_Min : 16|8@1+ (0.5,-40) [-40|86.5] "Unit_DegreCelsi"  Klima_PAG_PF
 SG_ BMS_Temp_Zelle_Max : 24|8@1+ (0.5,-40) [-40|86.5] "Unit_DegreCelsi"  Klima_PAG_PF,Kombi_PAG_PF
 SG_ BMS_Pumpendrehzahl : 32|8@1+ (0.5,0) [0|100] "Unit_PerCent"  Klima_PAG_PF
 SG_ BMS_Status_3_2_Ventil1 : 40|3@1+ (1,0) [0|7] ""  Klima_PAG_PF
 SG_ BMS_Status_3_2_Ventil2 : 43|3@1+ (1,0) [0|7] ""  Klima_PAG_PF
 SG_ BMS_PTC_IstStrom : 48|8@1+ (0.1,0) [0|25.2] "Unit_Amper" Vector__XXX
 SG_ BMS_PTC_Stufe : 56|4@1+ (10,0) [0|100] "Unit_PerCent" Vector__XXX

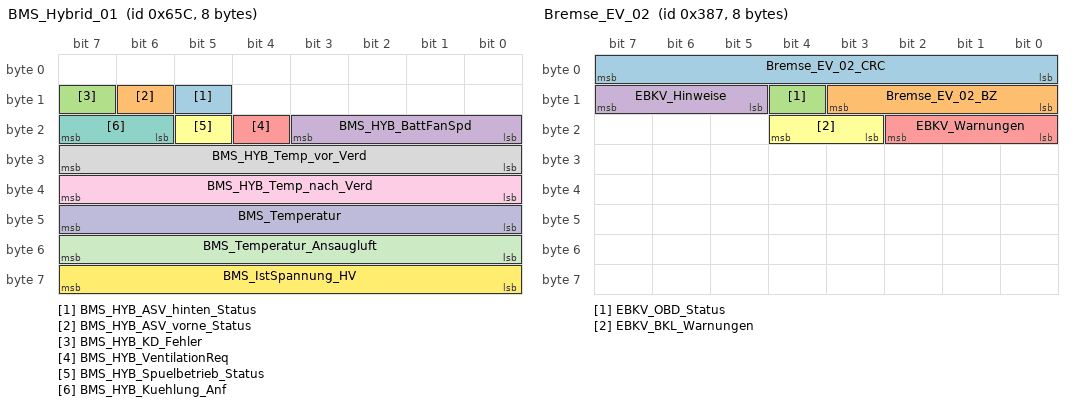
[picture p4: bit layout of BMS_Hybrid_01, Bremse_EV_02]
BO_ 1628 BMS_Hybrid_01: 8 GW_Routing_PAG_PF
 SG_ BMS_HYB_ASV_hinten_Status : 13|1@1+ (1,0) [0|1] "" Vector__XXX
 SG_ BMS_HYB_ASV_vorne_Status : 14|1@1+ (1,0) [0|1] "" Vector__XXX
 SG_ BMS_HYB_KD_Fehler : 15|1@1+ (1,0) [0|1] "" Vector__XXX
 SG_ BMS_HYB_BattFanSpd : 16|4@1+ (10,0) [0|100] "Unit_PerCent" Vector__XXX
 SG_ BMS_HYB_VentilationReq : 20|1@1+ (1,0) [0|1] "" Vector__XXX
 SG_ BMS_HYB_Spuelbetrieb_Status : 21|1@1+ (1,0) [0|1] "" Vector__XXX
 SG_ BMS_HYB_Kuehlung_Anf : 22|2@1+ (1,0) [0|3] ""  Klima_PAG_PF
 SG_ BMS_HYB_Temp_vor_Verd : 24|8@1+ (0.5,-40) [-40|86.5] "Unit_DegreCelsi" Vector__XXX
 SG_ BMS_HYB_Temp_nach_Verd : 32|8@1+ (0.5,-40) [-40|86.5] "Unit_DegreCelsi" Vector__XXX
 SG_ BMS_Temperatur : 40|8@1+ (0.5,-40) [-40|86.5] "Unit_DegreCelsi" Vector__XXX
 SG_ BMS_Temperatur_Ansaugluft : 48|8@1+ (0.5,-40) [-40|86.5] "Unit_DegreCelsi" Vector__XXX
 SG_ BMS_IstSpannung_HV : 56|8@1+ (1,100) [100|350] "Unit_Volt" Vector__XXX

BO_ 903 Bremse_EV_02: 8 GW_Routing_PAG_PF
 SG_ Bremse_EV_02_CRC : 0|8@1+ (1,0) [0|255] "" Vector__XXX
 SG_ Bremse_EV_02_BZ : 8|4@1+ (1,0) [0|15] "" Vector__XXX
 SG_ EBKV_OBD_Status : 12|1@1+ (1,0) [0|1] "" Vector__XXX
 SG_ EBKV_Hinweise : 13|3@1+ (1,0) [0|7] ""  Kombi_PAG_PF
 SG_ EBKV_Warnungen : 16|3@1+ (1,0) [0|7] ""  Kombi_PAG_PF
 SG_ EBKV_BKL_Warnungen : 19|2@1+ (1,0) [0|3] ""  Kombi_PAG_PF

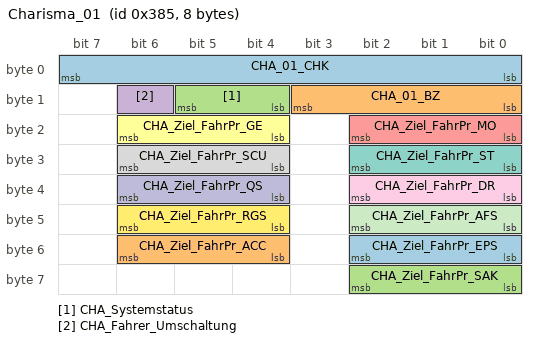
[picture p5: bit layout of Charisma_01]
BO_ 901 Charisma_01: 8 Klima_PAG_PF
 SG_ CHA_01_CHK : 0|8@1+ (1,0) [0|255] ""  GW_Routing_PAG_PF
 SG_ CHA_01_BZ : 8|4@1+ (1,0) [0|15] ""  GW_Routing_PAG_PF
 SG_ CHA_Systemstatus : 12|2@1+ (1,0) [0|3] ""  GW_Routing_PAG_PF
 SG_ CHA_Fahrer_Umschaltung : 14|1@1+ (1,0) [0|1] ""  GW_Routing_PAG_PF
 SG_ CHA_Ziel_FahrPr_MO : 16|3@1+ (1,0) [0|7] ""  GW_Routing_PAG_PF
 SG_ CHA_Ziel_FahrPr_GE : 20|3@1+ (1,0) [0|7] ""  GW_Routing_PAG_PF
 SG_ CHA_Ziel_FahrPr_ST : 24|3@1+ (1,0) [0|7] ""  GW_Routing_PAG_PF
 SG_ CHA_Ziel_FahrPr_SCU : 28|3@1+ (1,0) [0|7] ""  GW_Routing_PAG_PF
 SG_ CHA_Ziel_FahrPr_DR : 32|3@1+ (1,0) [0|7] ""  GW_Routing_PAG_PF
 SG_ CHA_Ziel_FahrPr_QS : 36|3@1+ (1,0) [0|7] ""  GW_Routing_PAG_PF
 SG_ CHA_Ziel_FahrPr_AFS : 40|3@1+ (1,0) [0|7] ""  GW_Routing_PAG_PF
 SG_ CHA_Ziel_FahrPr_RGS : 44|3@1+ (1,0) [0|7] ""  GW_Routing_PAG_PF
 SG_ CHA_Ziel_FahrPr_EPS : 48|3@1+ (1,0) [0|7] ""  GW_Routing_PAG_PF
 SG_ CHA_Ziel_FahrPr_ACC : 52|3@1+ (1,0) [0|7] ""  GW_Routing_PAG_PF
 SG_ CHA_Ziel_FahrPr_SAK : 56|3@1+ (1,0) [0|7] ""  GW_Routing_PAG_PF

BO_ 1336 Charisma_02: 8 GW_Routing_PAG_PF
 SG_ MO_Charisma_FahrPr : 0|3@1+ (1,0) [0|7] ""  Klima_PAG_PF
 SG_ MO_Charisma_Status : 3|2@1+ (1,0) [0|3] ""  Klima_PAG_PF
 SG_ MO_Charisma_Umschaltung : 5|2@1+ (1,0) [0|3] ""  Klima_PAG_PF
 SG_ Motor_05_alt : 7|1@1+ (1,0) [0|1] ""  Klima_PAG_PF
 SG_ GE_Charisma_FahrPr : 8|3@1+ (1,0) [0|7] ""  Klima_PAG_PF
 SG_ GE_Charisma_Status : 11|2@1+ (1,0) [0|3] ""  Klima_PAG_PF
 SG_ GE_Charisma_Umschaltung : 13|2@1+ (1,0) [0|3] ""  Klima_PAG_PF
 SG_ Getriebe_04_alt : 15|1@1+ (1,0) [0|1] ""  Klima_PAG_PF
 SG_ SCU_Charisma_FahrPr : 16|3@1+ (1,0) [0|7] "" Vector__XXX
 SG_ SCU_Charisma_Status : 19|2@1+ (1,0) [0|3] "" Vector__XXX
 SG_ SCU_Charisma_Umschaltung : 21|2@1+ (1,0) [0|3] "" Vector__XXX
 SG_ SCU_02_alt : 23|1@1+ (1,0) [0|1] "" Vector__XXX
 SG_ ST_Charisma_FahrPr : 24|3@1+ (1,0) [0|7] "" Vector__XXX
 SG_ ST_Charisma_Status : 27|2@1+ (1,0) [0|3] "" Vector__XXX
 SG_ ST_Charisma_Umschaltung : 29|2@1+ (1,0) [0|3] "" Vector__XXX
 SG_ BCM1_01_alt : 31|1@1+ (1,0) [0|1] "" Vector__XXX
 SG_ DR_Charisma_FahrPr : 32|3@1+ (1,0) [0|7] ""  Klima_PAG_PF
 SG_ DR_Charisma_Status : 35|2@1+ (1,0) [0|3] ""  Klima_PAG_PF
 SG_ DR_Charisma_Umschaltung : 37|2@1+ (1,0) [0|3] ""  Klima_PAG_PF
 SG_ Daempfer_01_alt : 39|1@1+ (1,0) [0|1] ""  Klima_PAG_PF
 SG_ QSP_Charisma_FahrPr : 40|3@1+ (1,0) [0|7] "" Vector__XXX
 SG_ QSP_Charisma_Status : 43|2@1+ (1,0) [0|3] "" Vector__XXX
 SG_ QSP_Charisma_Umschaltung : 45|2@1+ (1,0) [0|3] "" Vector__XXX
 SG_ QSP_01_alt : 47|1@1+ (1,0) [0|1] "" Vector__XXX
 SG_ RGS_VL_Charisma_FahrPr : 48|3@1+ (1,0) [0|7] "" Vector__XXX
 SG_ RGS_VL_Charisma_Status : 51|2@1+ (1,0) [0|3] "" Vector__XXX
 SG_ RGS_VL_Charisma_Umschaltung : 53|2@1+ (1,0) [0|3] "" Vector__XXX
 SG_ RGS_VL_01_alt : 55|1@1+ (1,0) [0|1] "" Vector__XXX
 SG_ AFS_Charisma_FahrPr : 56|3@1+ (1,0) [0|7] "" Vector__XXX
 SG_ AFS_Charisma_Status : 59|2@1+ (1,0) [0|3] "" Vector__XXX
 SG_ AFS_Charisma_Umschaltung : 61|2@1+ (1,0) [0|3] "" Vector__XXX
 SG_ AFS_01_alt : 63|1@1+ (1,0) [0|1] "" Vector__XXX

BO_ 1338 Charisma_04: 8 GW_Routing_PAG_PF
 SG_ EPS_Charisma_FahrPr : 0|3@1+ (1,0) [0|7] ""  Klima_PAG_PF
 SG_ EPS_Charisma_Status : 3|2@1+ (1,0) [0|3] ""  Klima_PAG_PF
 SG_ EPS_Charisma_Umschaltung : 5|2@1+ (1,0) [0|3] ""  Klima_PAG_PF
 SG_ EPS_FR_alt : 7|1@1+ (1,0) [0|1] ""  Klima_PAG_PF
 SG_ ACC_Charisma_FahrPr : 8|3@1+ (1,0) [0|7] "" Vector__XXX
 SG_ ACC_Charisma_Status : 11|2@1+ (1,0) [0|3] "" Vector__XXX
 SG_ ACC_Charisma_Umschaltung : 13|2@1+ (1,0) [0|3] "" Vector__XXX
 SG_ ACC_04_alt : 15|1@1+ (1,0) [0|1] "" Vector__XXX
 SG_ SAK_Charisma_FahrPr : 16|3@1+ (1,0) [0|7] "" Vector__XXX
 SG_ SAK_Charisma_Status : 19|2@1+ (1,0) [0|3] "" Vector__XXX
 SG_ SAK_Charisma_Umschaltung : 21|2@1+ (1,0) [0|3] "" Vector__XXX
 SG_ SAK_01_alt : 23|1@1+ (1,0) [0|1] "" Vector__XXX
 SG_ NR_Niveaufunktion_aktiv : 24|2@1+ (1,0) [0|3] "" Vector__XXX
 SG_ Daempfer_01_alt : 31|1@1+ (1,0) [0|1] "" Vector__XXX
 SG_ CHA_04_va_57 : 39|1@1+ (1,0) [0|1] "" Vector__XXX
 SG_ CHA_04_va_67 : 47|1@1+ (1,0) [0|1] "" Vector__XXX
 SG_ CHA_04_va_77 : 55|1@1+ (1,0) [0|1] "" Vector__XXX
 SG_ CHA_04_va_87 : 63|1@1+ (1,0) [0|1] "" Vector__XXX

BO_TX_BU_ 1598 : Kombi_PAG_PF,OCU_PAG_PF;

CM_ "PAG_Plattform_CAN_Dashboard_0.0.1 Generated by BUSNETNG 8.2.2";
CM_ BU_ Klimakomp_Dash_PAG_PF "Einsatz nur im Hybrid";
CM_ SG_ 192 Adr_Clima_Mono "Mono-Mode Klimaanlage";
CM_ SG_ 192 Adr_T_LVT_O "Taster Luftverteilung oben";
CM_ SG_ 192 Adr_T_LVT_M "Taster Luftverteilung Mannanströmer";
CM_ SG_ 192 Adr_T_LVT_U "Taster Luftverteilung Fußraum";
CM_ SG_ 192 Adr_AC_Menue_LED_an "Status AC-Menü";
CM_ SG_ 192 Adr_Phone_LED_an "Status Phone-Menü";
CM_ SG_ 192 Adr_Media_LED_an "Status Media-Menü";
CM_ SG_ 192 Adr_Tuner_LED_an "Status Tuner-Menü";
CM_ SG_ 192 Adr_Car_LED_an "Status Car-Menü";
CM_ SG_ 192 Adr_Info_LED_an "Status Info Menü";
CM_ SG_ 192 Adr_Navi_LED_an "Status Navi-Menü";
CM_ SG_ 192 Adr_Alive_Cnt "Ringcounter, wird mit jeder Nachricht um 1 inkrementiert";
CM_ SG_ 192 Adr_Pos_En "Aktiviert das Durchreichen der Daten vom Touch-Controller (Nachricht Miko_abs_coord1/ Miko_abs_coord2 aktiviert/deaktiviert).";
CM_ SG_ 192 Adr_Display_Status "Display in Miko an oder aus";
CM_ SG_ 192 Adr_Active_Character_Page "Zeichentabelle nach internationalem Standard";
CM_ SG_ 192 Adr_Chr_Mode "0000 0000 = CHARACTER_ANY
0000 0001 = CHARACTER_NUMBER
0000 0010 = CHARACTER_SPECIAL
0000 0100 = CHARACTER_UPPER_LETTER
0000 1000 = CHARACTER_LOWER_LETTER
0001 0000 = OPTION_1
0010 0000 = OPTION_2
0100 0000 = OPTION_3
1000 0000 = OPTION_4
1111 11";
CM_ SG_ 192 Adr_Gst_Mode "Any = 0000 0000 0000 0000 = All gestures allowed
Klick                 0000 0000 0000 0001  = GESTURE_TAP
Gedrückt halten       0000 0000 0000 0010  = GESTURE_LONGPRESS
Verschieben           0000 0000 0000 0100  = GESTURE_PAN
Schnelles Verschieben 000";
CM_ SG_ 194 Adr_Konfig_Datenfeld "Konfiguration Datenfeld Zeile 1..4 in Kombi";
CM_ SG_ 194 Adr_KI_BC_Rolle_Konfig "0000 0000 = Init
0000 0001 =  BC Seite Fahrzeug
0000 0010 = Trip
0000 0100 = GForce
0000 1000 = Schaltanzeige
0001 0000 = E-Power Assist
0010 0000 = RDK
0100 0000 = Chrono Lite";
CM_ SG_ 194 Adr_KI_BC_Rolle_Datenfeld "Konfiguration Datenfeld Zeile x in Kombi
(x siehe Signal Adr_Konfig_Datenfeld)";
CM_ SG_ 194 Adr_Joker_Taste "Jokertastenbelegung - Aufruf Funktion im Kombi";
CM_ SG_ 194 Adr_KL58d "ADR-Display-Dimmung
";
CM_ SG_ 194 Adr_KI_Helligkeit "TFT Helligkeit Kombi
";
CM_ SG_ 194 Adr_Miko_Helligkeit "TFT Helligkeit Miko
";
CM_ BO_ 64 "MLB mit CHK";
CM_ SG_ 64 Airbag_01_CHK "Berechnung siehe Lastenheft 'Kommunikationsabsicherung für FlexRay und CAN'
Endwerte siehe 'Kommunikationsabsicherung für FlexRay und CAN / Anhang C: Tabelle S-PDU Kennungen'";
CM_ SG_ 64 AB_RGS_Anst "PreCrash-Ansteuerung reversibler Gurtstraffer (Aktivierung und Kraftniveau)

10xx = deaktiviert";
CM_ SG_ 64 AB_Front_Crash "Bit wird bei Überschreitung der Gurtstraffer-, US- und RdW-Schwelle gesetzt";
CM_ SG_ 64 AB_Heck_Crash "Wird für alle neu anlaufenden Projekte umgesetzt: AB8.4, Audi8/VW8";
CM_ SG_ 64 AB_SF_Crash "Z.Zt. nur in Verbindung mit Crash-Intensität >= 100b (Kraftstoffpumpenabschaltung) verwendet.";
CM_ SG_ 64 AB_SB_Crash "Z.Zt. nur in Verbindung mit Crash-Intensität >= 100b (Kraftstoffpumpenabschaltung) verwendet.
";
CM_ SG_ 64 AB_Rollover_Crash "Wird im B6/B7 Cabrio und New Beetle Cabrio bedient. ";
CM_ SG_ 64 AB_Crash_Int "Crash_Intensität_1 = fahrzeugabhängige Reaktionen im Crash
Crash_Intensität_2 = fahrzeugabhängige Reaktionen im Crash
Crash_Intensität_3 = fahrzeugabhängige Reaktionen im Crash

Die jeweiligen fahrzeugabhängigen Reaktionen im Crash sind in einem separ";
CM_ SG_ 64 AB_Lampe "Sicherheitswarnlampe im Kombi wird vom Airbag-SG angesteuert; Zustand der Lampe wird auf dem CAN-Bus ausgegeben (auch Blinkinformation).";
CM_ SG_ 64 AB_Deaktiviert "Airbag oder Gurtstraffer wurden per Anpassung deaktiviert: Aktualisierung erst nach Selbsttest";
CM_ SG_ 64 AB_VB_deaktiviert "Als Option vorgehalten, Beifahrerairbag wurden per Schlüsselschalter oder Insassenerkennung deaktiviert";
CM_ SG_ 64 AB_Systemfehler "Systemfehler Ggf. wird Warnlampe dauernd eingeschaltet.";
CM_ SG_ 64 AB_Diagnose "Airbag in Diagnose";
CM_ SG_ 64 AB_Stellgliedtest "Information, ob Airbag im Stellgliedtest ist, um eine Notrufauflösung beim Stellgliedtest zu verhindern";
CM_ SG_ 64 AB_Erh_Auf_VB "Der Fahrer soll bei einem Statuswechsel des Beifahrerairbags (ausgelöst durch die Beifahrerinsassenerkennung oder den Schlüsselschloßschalter) aufmerksam gemacht werden durch eine Anzeige im Kombi. Nur Audi: gültig für: AB2 (4-Türer AU352), B7, C6, D3";
CM_ SG_ 64 AB_Gurtwarn_VF "Fahrer hat Gurt nicht gesteckt, Anzeige im Kombi";
CM_ SG_ 64 AB_Gurtwarn_VB "Beifahrer hat Gurt nicht gesteckt, Anzeige im Kombi";
CM_ SG_ 64 AB_Anzeige_Fussg "Anzeige für ausgelöste Fussgängerschutz-Aktuatorik";
CM_ SG_ 64 AB_Texte_AKS "Textanzeige für pyrotechnische Auslösung der aktiven Kopfstütze (AKS)";
CM_ SG_ 64 AB_PAO_Leuchte_Anf "Anforderung an die Passenger-Airbag-Off Leuchte in der Dachkonsole (ein / aus), Einsatz nur bei PAG";
CM_ SG_ 64 AB_MKB_gueltig "Multi-Kollisions-Bremsung im Airbag freigeschaltet";
CM_ SG_ 64 AB_Versorgungsspannung "Übertragung der Plausibilitätsinformation Kl.15-Last vs. Kl.15-CAN.
Bedienung im Fall Kl.15-Last 'EIN' und Kl.15-CAN 'AUS' mit Ausgabe Warnung/Akustik im Kombi.";
CM_ SG_ 64 AB_Deaktivierung_HV "Deaktivierung des HV-Systems und der HV-Teilnehmer im Crash (u.a. Hybrid- und Elektrofahrzeuge)";
CM_ SG_ 64 AB_EDR_Trigger "Triggerbedingung zur dezentralen Aufzeichnung unfallrelevanter Daten im Event Data Recorder";
CM_ SG_ 64 AB_KD_Fehler "Bei gesetztem Bit ist mindestens ein Kundendienstfehler eingetragen
";
CM_ BO_ 1632 "ab MQB mit Gurtschlosserkennung 'bei Änderung sofort'";
CM_ SG_ 1632 Airbag_02_CRC "Für MLB:
'Berechnung siehe Lastenheft 'Kommunikationsabsicherung für FlexRay und CAN''

Ab MQB und MLBevo:
'Berechnung siehe Lastenheft 'End-to-End Kommunikationsabsicherung''

Endwerte siehe Begleitdokument 'S-PDU Kennungsfolgen'";
CM_ SG_ 1632 AB_Belegung_VB "Belegungserkennung vorne Beifahrer. Wird in US-Steuergeräten über Bladder-Matte bedient, optional bei RdW, falls SBE_EuroNCAP entschieden wird.";
CM_ SG_ 1632 AB_Gurtschloss_FA "Gurtschlosstatatus Fahrerseite";
CM_ SG_ 1632 AB_Gurtschloss_BF "Gurtschlossstatus Beifahrerseite";
CM_ SG_ 1632 AB_Gurtschloss_Reihe2_FA "Gurtschlossstatus 2. Reihe Fahrerseite, Mehrausstattung";
CM_ SG_ 1632 AB_Gurtschloss_Reihe2_MI "Gurtschlossstatus 2. Reihe Mitte,  Mehrausstattung";
CM_ SG_ 1632 AB_Gurtschloss_Reihe2_BF "Gurtschlossstatus 2. Reihe Beifahrerseite,  Mehrausstattung";
CM_ SG_ 1632 AB_Gurtschloss_Reihe3_FA "Gurtschlossstatus 3. Reihe Fahrerseite,  Mehrausstattung";
CM_ SG_ 1632 AB_Gurtschloss_Reihe3_MI "Gurtschlossstatus 3. Reihe Mitte,  Mehrausstattung";
CM_ SG_ 1632 AB_Gurtschloss_Reihe3_BF "Gurtschlossstatus 3. Reihe Beifahrerseite,  Mehrausstattung";
CM_ SG_ 1632 AB_Sitzpos_Sens_FA "Ausgabe Sitzposition Fahrer";
CM_ SG_ 1632 AB_Sitzpos_Sens_BF "Ausgabe Sitzposition Beifahrer";
CM_ BO_ 1490 "BAP-Msg vom Anzeigesteuergerät";
CM_ BO_ 1491 "BAP-Msg vom Anzeigesteuergerät";
CM_ BO_ 1492 "BAP-Msg vom Anzeigesteuergerät";
CM_ BO_ 1493 "BAP-Msg vom Anzeigesteuergerät";
CM_ BO_ 1565 "BAP-Msg vom Funktionssteuergerät";
CM_ BO_ 1583 "BAP-Msg vom Funktionssteuergerät";
CM_ SG_ 1634 BCM1_Bremsbelag_Warn "Bremsbelagwarnung";
CM_ SG_ 1634 BCM1_Bremsfluessigkeit_Warn "Bremsfluessigkeit Warnung";
CM_ SG_ 1634 BCM1_Licht_Warn "Lichtwarnung";
CM_ SG_ 1634 BCM1_Waschwasser_Warn "Waschwasserwarnung";
CM_ SG_ 1634 BCM1_Kuehlmittel_Warn "Kuehlmittel Warnung
";
CM_ SG_ 1634 BCM1_Gleitende_Leuchtw_Anf "Funktion 'Gleitende Leuchtweite' im AFS-SG  freischalten";
CM_ SG_ 1634 LV_Aussenlicht_def "Aussenlicht kann nicht mehr korrekt angesteuert werden (EEPROM Codierung kann nicht mehr ausgelesen werden)
";
CM_ SG_ 1634 LV_AFL_defekt "Fehlerstatus AFL
";
CM_ SG_ 1634 BCM1_Handbremse_Schalter "Handbremsschalter


";
CM_ SG_ 1634 BCM1_MH_Schalter "Motorhaubenkontakt";
CM_ SG_ 1634 BCM1_MH_WIV_Schalter "Bewerteter Motorhaubenkontakt fuer WIV";
CM_ SG_ 1634 BCM1_Oeldruck_Schalter "Schalter Oeldruck vorhanden --> nur im B8, nicht im D4 verwendet


";
CM_ SG_ 1634 BCM1_Kl_15_HW_erkannt "Erkennung Klemme 15 (Hardware) vom BCM1
";
CM_ SG_ 1634 BCM1_Lenksaeule_aktiv "Lenksaeulenverstellung aktiv";
CM_ SG_ 1634 BCM1_Oeldruck_Schalter_2 "Vorhalt Schalter Oeldruck 

nicht im B8 und D4 verwendet

";
CM_ SG_ 1634 BCM1_SRA_aktiv "Status Scheinwerferreinigungsanlage";
CM_ SG_ 1634 LV_Standlicht_Anzeige "Anzeige Standlicht
";
CM_ SG_ 1634 LV_Abblendlicht_Anzeige "Abblendlicht aktiv";
CM_ SG_ 1634 LV_Fernlicht_Anzeige "Fernlicht_aktiv";
CM_ SG_ 1634 LV_Nebellicht_Anzeige "Nebellicht_aktiv
";
CM_ SG_ 1634 LV_Nebelschlusslicht_Anzeige "Nebelschlusslicht_aktiv
";
CM_ SG_ 1634 LV_Tagfahrlicht_Anzeige "Anzeige Tagfahrlicht
";
CM_ SG_ 1634 LV_AFL_aktiv_Anzeige "Anzeige AFL-Funktion";
CM_ SG_ 1634 BCM1_Licht_Dunkelheit_aktiv "Licht aktiv aufgrund von Dunkelheit (nicht bei Autobahn-, Tagfahr- oder Regenlicht)
";
CM_ SG_ 1634 LV_Blinker_li_def "Fehlerstatus Blinker vorne links
";
CM_ SG_ 1634 LV_Standlicht_li_def "Fehlerstatus Standlicht vorne links
";
CM_ SG_ 1634 LV_Abblendlicht_li_def "Fehlerstatus Abblendlicht vorne links 
";
CM_ SG_ 1634 LV_Fernlicht_li_def "Fehlerstatus Fernlicht vorne links
";
CM_ SG_ 1634 LV_Nebellicht_li_def "Fehlerstatus Nebelscheinwerfer vorne links
";
CM_ SG_ 1634 LV_Blk_li_Seite_def "Fehlerstatus Seitenblinker links
";
CM_ SG_ 1634 LV_Tagfahrlicht_li_def "Fehlerstatus Tagfahrlicht links
";
CM_ SG_ 1634 BCM1_GLW_Fernlicht_Anf "Harte Fernlichtanforderung von BCM1 an die Funktion 'gleitende Leuchtweite' im AFS-SG";
CM_ SG_ 1634 LV_Abblendlicht_TFL_li_def "Fehlerstatus Abblendlicht und Tagfahrlicht links
";
CM_ SG_ 1634 LV_Nebellicht_TFL_li_def "Fehlerstatus Nebellicht und Tagfahrlicht links ";
CM_ SG_ 1634 LV_Standlicht_TFL_li_def "Fehlerstatus Standlicht und Tagfahrlicht links ";
CM_ SG_ 1634 LV_Abblend_Fernlicht_li_def "Fehlerstatus Abblendlicht und Fernlicht links ";
CM_ SG_ 1634 LV_FLA_aktiv_Anzeige "Ansteuerung FLA-Lampe im Kombi (BCM1 Bedienmaster)";
CM_ SG_ 1634 LV_FLA_defekt "Fehlerstatus FLA (Anzeige des entsprechenden Fehlertext im Kombi)";
CM_ SG_ 1634 LV_FLA_Sensor_blockiert "Status FLA-Sensor (Anzeige des entsprechenden Fehlertext im Kombi)";
CM_ SG_ 1634 BCM1_EasyEntry_Status "Status EasyEntry für Lenksäule (wird auch von IVB verwendet)";
CM_ SG_ 1634 LV_Blinker_re_def "Fehlerstatus Blinker vorne rechts
";
CM_ SG_ 1634 LV_Standlicht_re_def "Fehlerstatus Standlicht vorne rechts
";
CM_ SG_ 1634 LV_Abblendlicht_re_def "Fehlerstatus Abblendlicht vorne rechts
";
CM_ SG_ 1634 LV_Fernlicht_re_def "Fehlerstatus Fernlicht vorne rechts
";
CM_ SG_ 1634 LV_Nebellicht_re_def "Fehlerstatus Nebelscheinwerfer vorne rechts
";
CM_ SG_ 1634 LV_Blk_re_Seite_def "Fehlerstatus Blinker Seite rechts
";
CM_ SG_ 1634 LV_Tagfahrlicht_re_def "Fehlerstatus Tagfahrlicht rechts";
CM_ SG_ 1634 BCM1_Adaptive_Lichtvert_Anf "Funktion 'Adaptive Lichtverteilung' im AFS-SG  Ein- und Ausschalten";
CM_ SG_ 1634 LV_Abblendlicht_TFL_re_def "Fehlerstatus Abblendlicht und Tagfahrlicht rechts ";
CM_ SG_ 1634 LV_Nebellicht_TFL_re_def "Fehlerstatus Nebellicht und Tagfahrlicht rechts";
CM_ SG_ 1634 LV_Standlicht_TFL_re_def "Fehlerstatus Standlicht und Tagfahrlicht rechts ";
CM_ SG_ 1634 LV_Abblend_Fernlicht_re_def "Fehlerstatus Abblendlicht und Fernlicht rechts";
CM_ SG_ 1634 BCM1_EasyEntry_texte "Meldungstext im Kombi über EasyEntry Zustand";
CM_ SG_ 1634 HYB_Anf_E_Mode "Zustand des E-Mode Tasters bei Hybrid-Fhz. Es wird der entprellte Betätigungszustand übertragen (betätigt/ nicht betätigt). Die Umwandlung des Tastersignals in ein statisches Schaltersignal erfolgt im MSG.";
CM_ SG_ 1634 UGDO_Function "UGDO_Sender = LIN-Slave BCM1
bei Kl.15 AUS wird für 4s noch der letzte Wert gesendet, danach wird der Wert 7 (= Fehler gesendet)
";
CM_ SG_ 1634 UGDO_LED_Code "UGDO_Sender = LIN-Slave BCM1
Signal wird bei Kl.15 AUS mit dem letzten empfangenen Wert gesendet

(Achtung: Signal besteht aus 32 logischen Werten. Nicht alle sind im Excel-Ausdruck sichtbar).";
CM_ SG_ 1697 BCM1_W_ELV "Kombiwarnung:
'Lenkungsverriegelung prüfen, Werkstatt aufsuchen' 
";
CM_ SG_ 1697 BCM1_W_Blinker_HR_def "Kombi Warnmeldung Blinker hinten rechts defekt 
1 = Blinker hinten rechts defekt";
CM_ SG_ 1697 BCM1_W_Blinker_HL_def "Kombi Warnmeldung Blinker hinten links defekt 
1 = Blinker hinten links defekt";
CM_ SG_ 1697 BCM1_W_LWR_def "LWR defekt (Vorhalt!)";
CM_ SG_ 1697 BCM1_W_Parklicht "Lichtwarnung 'Parklicht Ein' im Kombiinstrument";
CM_ SG_ 1697 BCM1_ZV_Horn "Horn zur akustischen Rückmeldung Zentralverriegelung";
CM_ SG_ 1697 BCM1_St_ZV "Status Zentralverriegelung";
CM_ SG_ 1697 BCM1_FSH_aktiv "Frontscheibenheizung aktiv";
CM_ SG_ 1697 BCM1_Kurvenlicht_li_Anf "Anforderung Kurvenlicht links";
CM_ SG_ 1697 BCM1_Kurvenlicht_re_Anf "Anforderung Kurvenlicht rechts";
CM_ SG_ 1697 BCM1_DWA_Anf "DWA Anforderung";
CM_ SG_ 1697 LDS_TF_Licht "Stellung Lichtdrehschalter auf 'Tagfahrlicht' 
(Signal 1:1 von LIN über BCM geroutet)";
CM_ SG_ 1697 LDS_AF_Licht "Stellung Lichtdrehschalter auf 'Automatikfahrlicht' ";
CM_ SG_ 1697 LDS_STA_Licht "Stellung Lichtdrehschalter auf 'Standlicht' 
(Signal 1:1 von LIN über BCM geroutet)";
CM_ SG_ 1697 LDS_Fahr_Licht "Stellung Lichtdrehschalter auf 'Fahrlicht' 
(Signal 1:1 von LIN über BCM geroutet)";
CM_ SG_ 1697 LDS_Error "Lichtdrehschalter Fehler";
CM_ SG_ 1697 LDS_N_Licht "Stellung Lichtdrehschalter auf 'Nebellicht' 
(Signal 1:1 von LIN über BCM geroutet)";
CM_ SG_ 1697 LDS_NS_Licht "Stellung Lichtdrehschalter auf 'Nebelschlusslicht' 
(Signal 1:1 von LIN über BCM geroutet)";
CM_ SG_ 1697 BCM1_Geschw_PSM_erkannt "Geschwindigkeit vom PSM erkannt";
CM_ SG_ 1697 BCM1_Heckklappe_entriegeln "Heckklappe entriegeln";
CM_ SG_ 1697 BCM1_CH_aktiv "Coming Home (zusätzlich zum Signal 'BCM1_CH_LH_aktiv' in der Botschaft BCM1_01)";
CM_ SG_ 1697 BCM1_LH_aktiv "Leaving Home (zusätzlich zum Signal 'BCM1_CH_LH_aktiv' in der Botschaft BCM1_01)";
CM_ SG_ 1697 BCM1_Trunkentrapment_auf "Trunkentrapment auf";
CM_ SG_ 1697 BCM1_Trunkentrapment_zu "Trunkentrapment zu";
CM_ SG_ 1697 BCM1_St_Handschuhfach "Status Handschuhfach";
CM_ SG_ 1697 BCM1_St_Scheinwerferdiebstahl "Status Scheinwerferdiebstahl";
CM_ SG_ 1697 BCM1_Seitenmarker_li_def "Seitenmarker links defekt 
Defektmeldung analog zu anderen Ausfallerkennungen";
CM_ SG_ 1697 BCM1_Seitenmarker_re_def "Seitenmarker rechts defekt 
Defektmeldung analog zu anderen Ausfallerkennungen";
CM_ SG_ 1697 LS_Dunkel "Regen- / Lichtsensor 
LS Dunkel";
CM_ SG_ 1697 BCM1_T_Verrieg_TAG "Information fuer die doppelte Betaetigung der Verriegelungstaster in den Tueraussengriffen";
CM_ SG_ 1697 LS_Autobahnfahrlicht "Autobahnfahrlicht Anforderung";
CM_ SG_ 1697 RS_Regenfahrlicht "Regenlicht Anforderung";
CM_ SG_ 1697 BCM1_Tankklappe_entriegeln "Anforderung Tankklappe entriegeln/verriegeln
";
CM_ SG_ 1409 BCM_FH_Freigabe "Funktionsfreigabe Fensterheber";
CM_ SG_ 1409 BCM_Komfortfkt_Freigabe "globale Freigabe der Komfortfunktion";
CM_ SG_ 1409 BCM_HSK_Freigabe "Handschuhkastenfreigabe";
CM_ SG_ 1409 BCM_Verdeck_Freigabe "Freigabe Verdeckbetrieb
";
CM_ SG_ 1409 BCM2_Status_Timer_KL15_Abschalt "Anforderung an BCM1, den Deaktivierungstimer für Klemme 15 bei erfüllten Abschaltbedingungen herunterzuzählen";
CM_ SG_ 1409 BCM2_Unterdr_Zuendungsmeldung "Bei aktivem Signal soll die Zündungsmeldung durch das Kombi unterdrückt werden.";
CM_ SG_ 1409 BCM2_KL15_Absch_FT "Signalisierung, dass die KL15 über das Verlassen des Fahrzeuges deaktiviert wurde (über Fahrertürtrigger).";
CM_ SG_ 1409 ZV_ist_Zustand_verfuegbar "Verfügbarkeit IST-Zustand ZV

";
CM_ SG_ 1409 BCM2_P_verriegelt "Nicht plausibilisiertes Rohsignal des P-Verriegeltschalters vom Wählhebel zur exklusiven Nutzung für Getriebesteuergeräte:
";
CM_ SG_ 1409 ZV_verriegelt_intern_ist "Istzustand: Verriegelung Fahrzeug innen
";
CM_ SG_ 1409 ZV_verriegelt_extern_ist "Istzustand: Verriegelung Fahrzeug aussen
";
CM_ SG_ 1409 ZV_verriegelt_intern_soll "Sollzustand: Verriegelung Fahrzeug innen
";
CM_ SG_ 1409 ZV_verriegelt_extern_soll "Sollzustand: Verriegelung Fahrzeug aussen
";
CM_ SG_ 1409 ZV_gesafet_extern_ist "Istzustand: Fahrzeug aussen gesafet
";
CM_ SG_ 1409 ZV_gesafet_extern_soll "Sollzustand: Fahrzeug gesafet extern
";
CM_ SG_ 1409 ZV_FT_offen "gespiegeltes Bit FT_Tuer_geoeffnet TSG_FT_1 Botschaft";
CM_ SG_ 1409 ZV_BT_offen "gespiegeltes Bit BT_Tuer_geoeffnet TSG_BT_1 Botschaft";
CM_ SG_ 1409 ZV_HL_offen "gespiegeltes Bit HL_Tuer_geoeffnet TSG_HL_1 Botschaft";
CM_ SG_ 1409 ZV_HR_offen "gespiegeltes Bit HR_Tuer_geoeffnet TSG_HR_1 Botschaft";
CM_ SG_ 1409 ZV_HD_offen "Status Heckdeckel
";
CM_ SG_ 1409 ZV_Turen_HD_zu "ZV: Tueren und HD geschlossen
";
CM_ SG_ 1409 ZV_Einzeltuerentriegelung "Einzeltürentriegelung ZV
";
CM_ SG_ 1409 ZV_Heckeinzelentriegelung "Heckdeckeleinzelentriegelung";
CM_ SG_ 1409 BCM_ValetTaster_Fkts_LED "Status Funktions-LED Valet Taster ('Valet Parking')
 

";
CM_ SG_ 1409 BCM_HHS_aktiv "Heizbare Heckscheibe aktiv";
CM_ SG_ 1409 BCM_Spg_Hzg_Ein "Anforderung Spiegelheizung
";
CM_ SG_ 1409 ZV_HS_offen "Status Heckscheibe
";
CM_ SG_ 1409 ZZH_Endlage_oben "obere Endlagenerkennung ZZH
";
CM_ SG_ 1409 ZZH_Endlage_unten "untere Endlagenerkennung ZZH
";
CM_ SG_ 1409 ZZH_Endlage_unplausibel "Erkennungung unplausible Endlage ZZH
";
CM_ SG_ 1409 BCM2_KD_Fehler "Status Kundendienstfehlerspeichereinträge
";
CM_ SG_ 1409 NGS_aktiv "Status Neigungssensor
";
CM_ SG_ 1409 IRUE_aktiv "Status Innenraumüberwachung
";
CM_ SG_ 1409 DWA_aktiv "Status DWA
";
CM_ SG_ 1409 Komp_Schutz_aktiv "Status Komponentenschutz (für 'passiven' KS im HDSG)


";
CM_ SG_ 1409 NGS_Taster_Fkts_LED "Anforderung Funktions-LED Neigungs-Taster
";
CM_ SG_ 1409 IRUE_Taster_Fkts_LED "Anforderung Funktions-LED IRUE-Taster (LED wird vom TSG angesteuert)
MQB: Bei Verbau eines einzelnen Taster zur Deaktivierung von IRUE und NGS wird dieses Signal zur Ansteuerung der Funktions-LED gesendet.";
CM_ SG_ 1409 HD_Drehfalle_S1 "S1 = Hauptraste
";
CM_ SG_ 1409 HD_Sperrklinke_S2 "Sperrklinke Heckdeckel (S2 = Vorraste), wird vom BCM2 eingelesen
 
";
CM_ SG_ 1409 BCM_Verbau_Heckrollo "Verbauinfo Heckrollo";
CM_ SG_ 1409 BCM2_EZS_gedrueckt "Betätigung EZS";
CM_ SG_ 1409 BCM2_SST_gedrueckt "Betätigung Start-Stop-Taster (Kessy-Fahrzeug)";
CM_ SG_ 1409 LIM_alt "Veraltet Bit fuer saemtliche Signale des LIN Innenlichtmoduls (LIM).

BCM2_02:
LIM_Innenbeleuchtung_V_aktiv
LIM_Taster_Rollolicht_hl
LIM_Taster_Rollolicht_hr
LIM_Taster_Notdienst
LIM_Taster_Rollolicht_V
";
CM_ SG_ 1409 LIM_Innenbeleuchtung_aktiv "Signal ist nur gülitig bei KL15 EIN, da kein aktiver Wakeup bei Statusänderung.
Das signal wird ev. für Rekuperation oder start/stop verwendet.";
CM_ SG_ 1409 BCM_Sperrklinke_FT "Entprelltes Signal der HW-Leitung des Sperrklinkenschalters, welche vom BCM2 eingelesen wird.
0: Schalter geschlossen --> Tuer offen 
1: Schalter offen --> Tuer geschlossen

Gefilterter und plausibilisierter Status der HW-Leitung vom Fahrertür-Sperrkl";
CM_ SG_ 1409 BCM_Tankwunsch "Tankwunsch (Fahrer betätigt Tankdeckeltaster)";
CM_ SG_ 1409 ZV_Tankklappe_offen "Öffnungsstatus der Tankklappe";
CM_ SG_ 1409 KST_Fahrer_Hinweise "Kombi Fahrerhinweise Klemmensteuerung
Audi/VW

0x01 P einlegen
0x02 Bremse betätigen
0x03 P oder N einlegen
0x04 Kupplung betätigen
0x05 Zündung eingeschaltet
0x06 Schlüssel im Zündschloß";
CM_ SG_ 1409 KST_Warn_P1_ZST_def "Kombi Prio Warnung Klemmensteuerung 
Zündschloß defekt, Service aufsuchen!";
CM_ SG_ 1409 KST_Warn_P2_ZST_def "Kombi Prio Warnung Klemmensteuerung
Zündschloß defekt!
";
CM_ SG_ 1409 KST_Prio_Warn_03 "Kombi Prio Warnung";
CM_ SG_ 1409 KST_Prio_Warn_04 "Kombi Prio Warnung ";
CM_ SG_ 1409 KST_Prio_Warn_05 "Kombi Prio Warnung Klemmensteuerung 5";
CM_ SG_ 900 BCM2_S_RF_Licht "Internet BCM Hut-zu-Hut Kommunikation, damit das BCM1 das Signal 'BCM1_Rueckfahrlicht_Schalter' verteilen kann. 
Schalter Rueckfahrlicht (Signal wird nur bei Schaltgetriebe unterstuetzt!) ";
CM_ SG_ 900 BCM2_ZZH_Endlage_oben "obere Endlagenerkennung ZZH
";
CM_ SG_ 900 BCM2_ZZH_Endlage_unten "untere Endlagenerkennung ZZH
";
CM_ SG_ 900 BCM2_W_VTS_Meldung "Warnung VTS Meldung";
CM_ SG_ 900 BCM2_W_TagfahrL_re_def "Warnung Tagfahrlicht rechts defekt";
CM_ SG_ 900 BCM2_W_TagfahrL_li_def "Warnung Tagfahrlicht links defekt";
CM_ SG_ 900 BCM2_W_KurvL_re_def "Warnung Kurvenlicht rechts defekt";
CM_ SG_ 900 BCM2_W_KurvL_li_def "Warnung Kurvenlicht links defekt";
CM_ SG_ 900 BCM2_W_Kuehlwasserstand "Warnung Kühlwasserstand";
CM_ SG_ 900 BCM2_W_HSpoiler_3 "Warnung: Motorraum-Servicedeckel kann nicht geöffnet werden, Spoiler ist ausgefahren";
CM_ SG_ 900 BCM2_W_HSpoiler_4 "Warnung: Spoiler kann nicht ausgefahren werden, Motorraum-Servicedeckel ist offen";
CM_ SG_ 900 BCM2_W_HSpoiler_1 "Warnung / 'Spoiler defekt' - Meldung im Kombi PRIO 1";
CM_ SG_ 900 BCM2_W_HSpoiler_2 "Warnung / 'Spoiler defekt' - Meldung im Kombi PRIO 2";
CM_ SG_ 900 BCM2_W_Dach_n_geschl "Warnmeldung ans Kombiinstrument 'Dach nicht vollständig geschlossen'";
CM_ SG_ 900 BCM2_Bremsbelag_Warn "Bremsbelagwarnung, 0x0 = iO; 0x1 = Bremsbelag unter min";
CM_ SG_ 900 BCM2_EBD_Warnblinken_Anf "Anforderung Warnblinken (ergänzend zur Funktion 'Emergency Brake Display')";
CM_ SG_ 900 BCM2_PassiveArming_aktiv "Status über Passive Arming";
CM_ SG_ 900 DK_St_PAO_Leuchte "PassengerAirbagOff (PAO) - Leuchte aus/ein/defekt/ungültig";
CM_ SG_ 900 DK_PAO_Signalzaehler "Passenger Airbag Off Leuchte - Signalzähler";
CM_ SG_ 900 BCM2_Hauptraste_HK_aktiv "Hauptraste aktiv";
CM_ SG_ 900 BCM2_Vorraste_HK_aktiv "Vorraste aktiv";
CM_ SG_ 900 BCM2_Softtouch_betaetigt "Betätigung Softtouch (=Aussentaster Heckklappe)
";
CM_ SG_ 900 BCM2_TrunkEntrapment_Anf "Anforderung Trunk Entrapment";
CM_ SG_ 900 BCM2_HsHzg_aktiv "Heizbare Heckscheibe aktiv";
CM_ SG_ 900 BCM2_St_LED_HSpoiler "Status des Heckspoilers zur Ansteuerung der Funktions-LED in der BKE";
CM_ SG_ 900 BCM2_DWA_aktiv "1 = DWA scharf; 0 = unscharf";
CM_ SG_ 900 BCM2_Alarmausgabe "Alarmausgabe";
CM_ SG_ 900 BCM2_Alarmblinken "Alarmblinken";
CM_ SG_ 900 BCM2_Heckwaschen_Anf "Anforderung Heckwaschen";
CM_ SG_ 900 BCM2_Geschw_PSM_erkannt "Geschwindigkeit vom PSM erkannt";
CM_ SG_ 900 DK_T_Resrv "Reservetaster Dachkonsole";
CM_ SG_ 900 DK_F_T_Resrv "Fehlerbit Reservetaster DK";
CM_ SG_ 900 DK_T_PDC "Betätigung Taster PDC in Dachkonsole 
Defaultmäßig ist die Tonwarnung eingeschaltet und die Checkbox 'Topview' gesetzt. Wird der Taster betätigt, wird die Tonwarnung und die Topview-Anzeige abgeschaltet.";
CM_ SG_ 900 DK_F_T_PDC "Fehlerbit PDC Taster";
CM_ SG_ 900 BCM2_W_SpoilerInfo "Verfahrinfo Spoilersystem zur Anzeige im Kombi ";
CM_ SG_ 900 BCM2_Rollo_Bew "Rolloverstellung aktiv";
CM_ SG_ 900 BCM2_Rollo_Pos "Rolloposition";
CM_ SG_ 900 BCM_Handshake_STH "Es gilt: Signalspec MO_Handshake v1.0

Handshake zwischen MSG und STH. Wenn das MSG die EKP aufgrund einer STH-Anforderung ansteuert und kein Fehlereintrag bzgl. EKP/KPE/NDR vorliegt, wird das Bit gesetzt.";
CM_ SG_ 900 BCM2_PAG_KD_Fehler "Status Kundendienstfehlerspeichereinträge
";
CM_ SG_ 900 BCM2_St_DCDCWandler "Status der DC/DC Wandler für Start/Stopp-Funktion
Werte siehe Wertetabelle, wobei dort jeder Wert auch in Kombination vorkommen kann (z.B. Wert=3, d.h. DCDC1 Übertemperatur UND DCDC1 defekt).";
CM_ SG_ 900 BCM2_T_Deckel_Vorne "Taster Deckel vorne betätigt";
CM_ SG_ 900 BCM1_ELV_enable_soll_2 "Freigabe ELV-Verriegelung
PAG: Kopie von BCM1_ELV_enable_soll für inter-BCM-Kommunikation
";
CM_ SG_ 900 BCM1_ELV_enable_Fehler_2 "Fehler bei ELV-Verriegelungsfreigabe
PAG: Kopie von BCM1_ELV_enable_Fehler für inter-BCM-Kommunikation
";
CM_ SG_ 900 BCM2_IL_Dimmung "bei Änderung im 30 ms Raster";
CM_ SG_ 1658 BCM2_Tankabgl_01 "Tankabg
leichswert BCM2 (Geber 1)";
CM_ SG_ 1658 BCM2_Tankabgl_02 "Tankabgleichswert BCM2 (Geber 2)
";
CM_ SG_ 1658 BCM2_Tankabgl_03 "Tankabgleichswert BCM2 (Geber 3)
";
CM_ BO_ 1635 "DLC=8 ab D4 gültig";
CM_ SG_ 1635 BEM_02_Abschaltstufen "Abschaltstufen des Ruhestrommanagements (Initialisierungswert aus EEprom)

Stufe 0 (keine Einschraenkungen)
Stufe 1 (Abschaltung Hochstromverbraucher)
Stufe 2 (Infotainmentabschaltung)
Stufe 3 (Wake-Up-Sperre)

Für den Transport- und Ruhestrommessm";
CM_ SG_ 1635 BEM_STH_Zielzeit "Maximal mögliche Zeit für den Standheizungsbetrieb, um die Startfähigkeit nicht zu gefährden";
CM_ SG_ 1635 BEM_MMI_Vorwarnung "Anzeige Vorwarnung MMI-Abschaltung (Initialisierungswert aus EEprom)
";
CM_ SG_ 1635 BEM_HL_Kontingentierung "Leistungskontingente für Heizsysteme";
CM_ SG_ 1635 NVEM_Anf_SD_schalten "Anforderung Nachlauf für den Steckdosenbetrieb
Initialisierungswert aus EEprom";
CM_ SG_ 1635 BEM_Generatordiagnose "Ansteuerung Generatorwarnleuchte im Kombi
";
CM_ SG_ 1635 BEM_Red_Innengeblaese "Reduzierung Innengebläse
";
CM_ SG_ 1635 BEM_STH_Einschaltverbot "Einschränkung Standheizung/-lüftung durch BEM: Setzt der BEM das Bit, dann darf die Standheizung nicht mehr einschalten
(Die Standheizung muss aber nicht abschalten, sondern darf weiterbrennen)
(Initialisierungswert aus EEprom)
";
CM_ SG_ 1635 BEM_HL_Regelung_Status "Status Regelung Heizleistung
";
CM_ SG_ 1635 BEM_Ladezustand "Ladezustand der Niedervoltbatterie
";
CM_ SG_ 1635 BEM_Batteriediagnose "Anzeige von Textwarnungen
";
CM_ SG_ 1635 MIB_Stromsparmodus "Signal beschreibt die Aktivierung für den Stromsparmodus beim MIB.
Bei AUS (= 0) gibt es keine weitere Anforderung an die MIB-Komponenten.
Bei EIN (= 1) werden alle MIB Komponenten in einen Stromsparmodus versetzt.";
CM_ SG_ 1635 BEM_DFM "Generatorauslastungsgrad, vom Generator über LIN an das Gateway gesandt. Das Motorsteuergerät regelt auf dieses Signal die PTC, das Energiemanagement im BSG/BCM kalkuliert die Bordnetzauslastung";
CM_ SG_ 1635 BEM_REK_aktiv "Rekuperationsfreigabe vom Energiemanagement
0x0 = keine Rekuperationsfreigabe
0x1 = Rekuperationsfreigabe";
CM_ SG_ 1635 BEM_EMLIN_ungueltig "Energie-Lin - Signale sind ungültig vom Slave Batteriedatenmodul oder Generator
0 = Signale gültig
1 = Signale ungültig";
CM_ SG_ 1635 BEM_Batt_Ab "Batterieverbindungskontrolle:
0x0: Batterie am Bordnetz
0x1: Batterie ab erkannt";
CM_ SG_ 1635 BEM_UBDM "Batteriespannung, gemessen vom Batteriedatenmodul";
CM_ SG_ 1635 BEM_UGenSoll "Sollspannungsvorgabe an den Generator, beinhaltet temperaturoptimierte Batterieladung und Rekuperation";
CM_ SG_ 1635 BEM_Anf_KL15_schalten "Abschaltempfehlung bzw. Verhinderung der automatischen Abschaltung Kl15 durch das BCM";
CM_ SG_ 1326 BEM_blDeaktivierungStandhzgAnz "Anzeige Kombi, dass die Standheizung deaktiviert war

";
CM_ SG_ 1326 BEM_blAbschaltungSteckdAnz "Anzeige Kombi, dass die Steckdosen angeschaltet werden
";
CM_ SG_ 1326 BEM_blReduzInnenGeblaeseAnz "Anzeige im Kombi/PCM, dass die Leistung des Innengebläses reduziert wird
";
CM_ SG_ 1326 BEM_blMmiVorwarnungBus "Signalisierung der MMI-Vorwarnung auf die Busse
";
CM_ SG_ 1326 BEM_blKl30Transport "Zusaetzliche Steuergeräte auf Kl. 30f (Transportmodus)
";
CM_ SG_ 1326 BEM_blKlemmeG1 "Klemme 'Komfortbeleuchtung Innenraum'
";
CM_ SG_ 1326 BEM_blKlemmeG2 "Klemme 'Sicherheitsbeleuchtung Innenraum'
";
CM_ SG_ 1326 BEM_blKl30fAusAnzeige "Fahrerinformation nach Wiedereinschaltung der Klemme 309";
CM_ SG_ 1326 BEM_valKl30fCountdown "Countdown zur Abschaltung der Klemme 30f
";
CM_ SG_ 1326 BEM_Kl15ausAnfProduktion "Anforderung die Klemme 15 auszuschalten (Ansteuerung der Klemme 30f und der Sd Relais in der HSB)";
CM_ BO_ 867 "Nur die Kombination des statischen und toggelnden Signals ergibt den Blinktakt für die Hell & Dunkelphase";
CM_ SG_ 867 BM_ZV_auf "Blinken bei ZV auf

";
CM_ SG_ 867 BM_ZV_zu "Blinken bei ZV zu

";
CM_ SG_ 867 BM_DWA_ein "Status Quittierungsblinken DWA";
CM_ SG_ 867 BM_DWA_Alarm "Status DWA-Alarmblinken
";
CM_ SG_ 867 BM_Crash "Status Crashblinken
";
CM_ SG_ 867 BM_Panik "Panikblinken
";
CM_ SG_ 867 BM_Not_Bremsung "Notbremsblinken

";
CM_ SG_ 867 BM_GDO "Blinken bei UGDO anlernen

";
CM_ SG_ 867 BM_links "Richtungsblinken links

";
CM_ SG_ 867 BM_rechts "Richtungsblinken rechts

";
CM_ SG_ 867 BM_Warnblinken "Warnblinken

";
CM_ SG_ 867 BM_Autobahn "Status Autobahnblinken
";
CM_ SG_ 867 BM_Taxi_Notalarm "Blinken bei Taxi-Not-Alarm

";
CM_ SG_ 867 BM_Telematik "Telematikblinken
";
CM_ SG_ 867 BM_HD_Oeffnung_angelernt "Das HDSG fordert über das CAN Signal HDSG_01.HD_Rueckmeld_prog eine Blinkerquittierung beim BCM2 an.
Wenn die Geschwindigkeit kleiner einer vorgegebenen Schwelle (default 2km/h) ist wird das Signal BM_HD_Öffnung_angelernt versendet und die Blinkerquittie";
CM_ SG_ 867 BM_WBT_Beleuchtung "Aktivierung Warnblinktasterfunktionsbeleuchtung
";
CM_ SG_ 867 Blinken_li_Fzg_Takt "Fzg-Takt Blinker links

";
CM_ SG_ 867 Blinken_re_Fzg_Takt "Fzg-Takt Blinker rechts

";
CM_ SG_ 867 Blinken_li_Kombi_Takt "Kombi-Takt Blinker links

";
CM_ SG_ 867 Blinken_re_Kombi_Takt "Kombi-Takt Blinker rechts

";
CM_ SG_ 867 BM_NBA_n_codiert_n_aktiv "Notbremsanzeige nicht codiert/nicht aktiv (Fehler)";
CM_ SG_ 867 BM_NBA_Status "Notbremsanzeige Status nicht aktiv / BRL Dunkelphase / BRL Hellphase";
CM_ SG_ 867 Blinken_FWB_aktiv "Status freilaufendes Warnblinken
";
CM_ SG_ 687 BMS_Rekuperation "Zähler: Anzeigesignal: Energiezufuhr in die HV-Batterie (Reku). Darf nicht durch Laden der Batterie bedatet werden";
CM_ SG_ 687 BMS_Rekuperation_Ueberlauf "Rekuperationleistungssignal BMS_Rekuperation mindest 1x übergelaufen";
CM_ SG_ 687 BMS_Verbrauch "Zähler: Energieentnahme aus der HV-Batterie";
CM_ SG_ 687 BMS_Verbrauch_Ueberlauf "Verbrauchssignal mindest 1x übergelaufen";
CM_ SG_ 1438 BMS_Temperierung_Anf "Temperierungsbedarf der HV-Batterie";
CM_ SG_ 1438 BMS_Temperatur "battery temperature / Momentanwert: Temperatur der Traktionsbatterie";
CM_ SG_ 1438 BMS_IstVorlaufTemperatur "Aktuelle Vorlauftemperatur der Batterie";
CM_ SG_ 1438 BMS_SollVorlaufTemp_Epsilon "¿Dieses Signal beschreibt die zulässige Abweichung oberhalb und unterhalb von der Sollvorlauftemperatur in Kelvin, die von der HV-Batterie akzeptiert wird. Bei einer SollVorlaufTemperatur von 30°C und einem Wert von SollVorlaufTemperaturEpsilon von 5K wer";
CM_ SG_ 1438 BMS_SollVolumenstrom "Soll Volumenstrom für Kühlkreislauf Batterie";
CM_ SG_ 1438 BMS_SollVorlauftemperatur "Soll_Vorlauftemperatur_Kühlmedium in °C";
CM_ SG_ 1438 BMS_IstRuecklaufTemperatur_02 "Aktuelle Ruecklauftemperatur der Batterie";
CM_ SG_ 1482 BMS_07_CRC "Für MLB:
'Berechnung siehe Lastenheft 'Kommunikationsabsicherung für FlexRay und CAN''

Ab MQB und MLBevo:
'Berechnung siehe Lastenheft 'End-to-End Kommunikationsabsicherung''

Endwerte siehe Begleitdokument 'S-PDU Kennungsfolgen'";
CM_ SG_ 1482 BMS_Energieinhalt "aktuell nutzbarer Energieinhalt der HV-Batterie
(bezogen auf ein definiertes mittleres Belastungsprofil)";
CM_ SG_ 1482 BMS_Ladevorgang_aktiv "Signalisiert aktiven Ladevorgang, Ladegerät und DC/DC aktiv.
Signal bleibt nach Kl.15 ein aktiv, bis ESP_Stillstandsflag gelöscht.

Abhängigkeit zu BMS_Energieinhalt";
CM_ SG_ 1482 BMS_MaxEnergieinhalt "maximaler nutzbarer Energieinhalt der HV-Batterie (bezogen auf Last KBI_RWDS_Lastprofil bei SOC=100%)
Abhängig von KBI_RWDS_Lastprofil";
CM_ SG_ 1482 BMS_Ausgleichsladung_Anf "BMS wünscht eine Ausgleichsladung
Flag derzeit ungenutzt, da BalancingModus im Detail noch nicht geklärt.";
CM_ SG_ 1482 BMS_Gesamtst_Spgfreiheit "0 = Funktion nicht aktiviert
1 = HV-System spannungsfrei (U_Zwkr von BMS, LE und Ladegerät < 20V, DCLadestecker nicht gesteckt und Service Disconnect entriegelt)
2 = HV-System nicht spannungsfrei (U_Zwkr von BMS, LE und Ladegerät >= 20V, Ladestecker ges";
CM_ SG_ 1519 BMS_IstStrom "actual current of the battery / Momentanwert: Batteriestrom
Stromrichtung: ein Ladestrom wird mit positiven, ein Entladestrom mit negativen Werten angegeben";
CM_ SG_ 1519 BMS_Status_Kuehlung "Rueckmeldung BMS Kuehlstufe";
CM_ SG_ 1519 BMS_Temp_Zelle_Min "Minimale Temperatur einer Zelle in der HVB";
CM_ SG_ 1519 BMS_Temp_Zelle_Max "Maximale Temperatur einer Zelle in der HVB";
CM_ SG_ 1519 BMS_Pumpendrehzahl "Rueckmeldung der CWA50 ueber aktuelle Pumpendrehzahl in % im Kuehlkreislauf HV-Batterie";
CM_ SG_ 1519 BMS_Status_3_2_Ventil1 "Status 3/2 Wegeventil Kuehlkreislauf HV-Batterie";
CM_ SG_ 1519 BMS_Status_3_2_Ventil2 "Status 3/2 Wegeventil Kuehlkreislauf HV-Batterie";
CM_ SG_ 1519 BMS_PTC_IstStrom "Ist Strom des PTC Zuheizers für den Batteriekühlkreislauf";
CM_ SG_ 1519 BMS_PTC_Stufe "aktulle Stufe des PTC Zuheizers für den Batteriekühlkreislauf";
CM_ SG_ 1628 BMS_HYB_ASV_hinten_Status "Status Absperrventil des Kältemittelkreislaufs zur Batteriekühlung";
CM_ SG_ 1628 BMS_HYB_ASV_vorne_Status "Status Absperrventil des Kältemittelkreislaufs zur Innenraumklimatisierung";
CM_ SG_ 1628 BMS_HYB_KD_Fehler "Bei gesetztem Bit ist mindestens ein Kundendienstfehler eingetragen";
CM_ SG_ 1628 BMS_HYB_BattFanSpd "Relativwert der Batterielüfter-Ansteuerung bezogen auf Maximalwert";
CM_ SG_ 1628 BMS_HYB_VentilationReq "BMS fordert bei Climatronic die Öffnung der Umluftklappe an";
CM_ SG_ 1628 BMS_HYB_Spuelbetrieb_Status "Status Betriebsart der Batterielüftung (Umluft-/Spülbetrieb)";
CM_ SG_ 1628 BMS_HYB_Kuehlung_Anf "Anforderung für aktive Batteriekühlung in vier Stufen:
Stufe 0: keine Kühlanforderung
Stufe 1: 10 °C Verdampfertemperatur Klima
Stufe 2: 3 °C Verdampfertemperatur Klima
Stufe 3: maximale Kühlleistung Klima";
CM_ SG_ 1628 BMS_HYB_Temp_vor_Verd "Lufttemperatur im Klimagerät BMS vor Verdampfer";
CM_ SG_ 1628 BMS_HYB_Temp_nach_Verd "Lufttemperatur im Klimagerät BMS nach Verdampfer";
CM_ SG_ 1628 BMS_Temperatur "battery temperature / Momentanwert: Temperatur der Traktionsbatterie";
CM_ SG_ 1628 BMS_Temperatur_Ansaugluft "Temperature of inlet air / Momentanwert: Ansauglufttemperatur der Batteriekühlung";
CM_ SG_ 1628 BMS_IstSpannung_HV "HV Spannungswert";
CM_ BO_ 903 "Schnittstelle EBKV - Kombi";
CM_ SG_ 903 Bremse_EV_02_CRC "Für MLB:
'Berechnung siehe Lastenheft 'Kommunikationsabsicherung für FlexRay und CAN''

Ab MQB und MLBevo:
'Berechnung siehe Lastenheft 'End-to-End Kommunikationsabsicherung''

Endwerte siehe Begleitdokument 'S-PDU Kennungsfolgen'";
CM_ SG_ 903 EBKV_OBD_Status "Ansteuerung der MIL-Lampe über den MIL-Master (Motorsteuergerät)";
CM_ SG_ 903 EBKV_Hinweise "Ansteuerung der Textanzeige";
CM_ SG_ 903 EBKV_Warnungen "Ansteuerung Kombi zur Fahrerwarnung";
CM_ SG_ 903 EBKV_BKL_Warnungen "Ansteuerung der BKL-Lampe";
CM_ BO_ 901 "Die Botschaft wird bei aktiver Funktion (Betaetigung Charisma-Schalter) sowie bei Kl.15 EIN 5mal gesendet (kein Abmelden)";
CM_ SG_ 901 CHA_01_CHK "Berechnung siehe Lastenheft 'Kommunikationsabsicherung für FlexRay und CAN'
Endwerte siehe 'Kommunikationsabsicherung für FlexRay und CAN / Anhang C: Tabelle S-PDU Kennungen'";
CM_ SG_ 901 CHA_01_BZ "Botschaftszaehler, wird aktuell noch nicht vom BCM1 bedient
(Vorhalt, falls Botschaft zyklisch wird)
";
CM_ SG_ 901 CHA_Systemstatus "Systemstatus Charisma Koordinator
";
CM_ SG_ 901 CHA_Fahrer_Umschaltung "Die manuelle Umschaltung durch den Fahrer soll signalisiert werden, um zu automatischen Umschaltungen (z.B. Retries) differenzieren zu können.";
CM_ SG_ 901 CHA_Ziel_FahrPr_MO "Anforderung Ziel-Fahrprogramm Motor";
CM_ SG_ 901 CHA_Ziel_FahrPr_GE "Anforderung Ziel-Fahrprogramm Getriebe";
CM_ SG_ 901 CHA_Ziel_FahrPr_ST "Anforderung Ziel-Fahrprogramm";
CM_ SG_ 901 CHA_Ziel_FahrPr_SCU "Anforderung Ziel-Fahrprogramm SCU";
CM_ SG_ 901 CHA_Ziel_FahrPr_DR "Anforderung Ziel-Fahrprogramm Dämpfer";
CM_ SG_ 901 CHA_Ziel_FahrPr_QS "Anforderung Ziel-Fahrprogramm Quattro Sport";
CM_ SG_ 901 CHA_Ziel_FahrPr_AFS "Anforderung Ziel-Fahrprogramm AFS";
CM_ SG_ 901 CHA_Ziel_FahrPr_RGS "Anforderung Ziel-Fahrprogramm Reversibler Gurtstraffer";
CM_ SG_ 901 CHA_Ziel_FahrPr_EPS "Anforderung Ziel-Fahrprogramm Elekronische Lenkung";
CM_ SG_ 901 CHA_Ziel_FahrPr_ACC "MLB
Anforderung Ziel-Fahrprogramm ACC";
CM_ SG_ 901 CHA_Ziel_FahrPr_SAK "Anforderung Ziel-Fahrprogramm-Soundaktuator

für D4";
CM_ SG_ 1336 MO_Charisma_FahrPr "Aktuelles Fahrprogramm des Charisma-Teilnehmers

Achtung neue Modusnamen (wie im MMI):

0x1 = Komfort = Comfort
0x2 = Dynamik = Auto
0x3 = Sport = Dynamic";
CM_ SG_ 1336 MO_Charisma_Status "Charisma Systemstatus des Charisma-Teilnehmers

Wert 0x3 ist nur für Fahrzeuge ab MQB relevant";
CM_ SG_ 1336 MO_Charisma_Umschaltung "Erkennung  Umschaltaufforderung des Charisma-Teilnehmers";
CM_ SG_ 1336 Motor_05_alt "Veraltet-Bit für die Signale:

Botschaft Gateway_01:
MO_Anf_KL75
MO_Verbot_EKP
MO_Anf_Pruefimpuls
MO_Klima_Eingr
MO_Aussp_Anlass
MO_Freig_Anlass

Botschaft Gateway_03:
MO_EKlKomLeiRed

Botschaft Gateway_05:
MO_Handshake_STH
MO_Freig_Reku
";
CM_ SG_ 1336 GE_Charisma_FahrPr "Aktuelles Fahrprogramm des Charisma-Teilnehmers

Achtung neue Modusnamen (wie im MMI):

0x1 = Komfort = Comfort
0x2 = Dynamik = Auto
0x3 = Sport = Dynamic";
CM_ SG_ 1336 GE_Charisma_Status "Charisma Systemstatus des Charisma-Teilnehmers

Wert 0x3 ist nur für Fahrzeuge ab MQB relevant";
CM_ SG_ 1336 GE_Charisma_Umschaltung "Erkennung  Umschaltaufforderung des Charisma-Teilnehmers";
CM_ SG_ 1336 Getriebe_04_alt "Veraltet-Bit für die Signale:

Botschaft Charisma_02:
GE_Charisma_FahrPr
GE_Charisma_Status
GE_Charisma_Umschaltung";
CM_ SG_ 1336 SCU_Charisma_FahrPr "Aktuelles Fahrprogramm des Charismateilnehmers SCU

Achtung neue Modusnamen (wie im MMI):

0x1 = Komfort = Comfort
0x2 = Dynamik = Auto
0x3 = Sport = Dynamic";
CM_ SG_ 1336 SCU_Charisma_Status "Systemstatus des Charismateilnehmers SCU

Wert 0x3 ist nur für Fahrzeuge ab MQB relevant
";
CM_ SG_ 1336 SCU_Charisma_Umschaltung "Erkennung Umschaltaufforderung des Charismateilnehmers SCU";
CM_ SG_ 1336 SCU_02_alt "Veraltet-Bit für die Signale:

Botschaft Charisma_02:
SCU_Charisma_FahrPr
SCU_Charisma_Status
SCU_Charisma_Umschaltung
";
CM_ SG_ 1336 ST_Charisma_FahrPr "Aktuelles Fahrprogramm des Charisma-Teilnehmers

Achtung neue Modusnamen (wie im MMI):

0x1 = Komfort = Comfort
0x2 = Dynamik = Auto
0x3 = Sport = Dynamic";
CM_ SG_ 1336 ST_Charisma_Status "Charisma Systemstatus des Charisma-Teilnehmers

Wert 0x3 ist nur für Fahrzeuge ab MQB relevant";
CM_ SG_ 1336 ST_Charisma_Umschaltung "Erkennung Umschaltaufforderung des Charisma-Teilnehmers";
CM_ SG_ 1336 BCM1_01_alt "Veraltet Bit für die Signale:

Botschaft Gateway_04:
BCM1_Charisma_Text_1
BCM1_Charisma_Text_2

Botschaft Gateway_05:
BCM1_Rueckfahrlicht_Schalter
BCM1_Vorwaertsgang_eingelegt
BCM1_RFahrlicht_Fzg_Anf
BCM1_Schalter_StartStopp

Botschaft Gateway";
CM_ SG_ 1336 DR_Charisma_FahrPr "Aktuelles Fahrprogramm des Charisma-Teilnehmers

Achtung neue Modusnamen (wie im MMI):

0x1 = Komfort = Comfort
0x2 = Dynamik = Auto
0x3 = Sport = Dynamic";
CM_ SG_ 1336 DR_Charisma_Status "Charisma Systemstatus des Charisma-Teilnehmers

Wert 0x3 ist nur für Fahrzeuge ab MQB relevant";
CM_ SG_ 1336 DR_Charisma_Umschaltung "Erkennung  Umschaltaufforderung des Charisma-Teilnehmers";
CM_ SG_ 1336 Daempfer_01_alt "Veraltet-Bit für die Signale:

Botschaft Charisma_02:
DR_Charisma_FahrPr
DR_Charisma_Status
DR_Charisma_Umschaltung

Botschaft Charisma_04:
NR_Niveaufunktion_aktiv
";
CM_ SG_ 1336 QSP_Charisma_FahrPr "Aktuelles Fahrprogramm des Charisma-Teilnehmers

Achtung neue Modusnamen (wie im MMI):

0x1 = Komfort = Comfort
0x2 = Dynamik = Auto
0x3 = Sport = Dynamic";
CM_ SG_ 1336 QSP_Charisma_Status "Charisma Systemstatus des Charisma-Teilnehmers

Wert 0x3 ist nur für Fahrzeuge ab MQB relevant";
CM_ SG_ 1336 QSP_Charisma_Umschaltung "Erkennung  Umschaltaufforderung des Charisma-Teilnehmers";
CM_ SG_ 1336 QSP_01_alt "Veraltet-Bit für die Signale:

Botschaft Charisma_02:
QS_Charisma_FahrPr
QS_Charisma_Status
QS_Charisma_Umschaltung

Botschaft Gateway_05:
QSP_StartStopp_Info

Botschaft Gateway_13:
QSP_Warnlampe";
CM_ SG_ 1336 RGS_VL_Charisma_FahrPr "Aktuelles Fahrprogramm des Charisma-Teilnehmers

Achtung neue Modusnamen (wie im MMI):

0x1 = Komfort = Comfort
0x2 = Dynamik = Auto
0x3 = Sport = Dynamic";
CM_ SG_ 1336 RGS_VL_Charisma_Status "Charisma Systemstatus des Charisma-Teilnehmers

Wert 0x3 ist nur für Fahrzeuge ab MQB relevant";
CM_ SG_ 1336 RGS_VL_Charisma_Umschaltung "Erkennung  Umschaltaufforderung des Charisma-Teilnehmers";
CM_ SG_ 1336 RGS_VL_01_alt "Veraltet-Bit für die Signale:

Botschaft Charisma_02:
RGS_L_Charisma_FahrPr
RGS_L_Charisma_Status
RGS_L_Charisma_Umschaltung";
CM_ SG_ 1336 AFS_Charisma_FahrPr "Aktuelles Fahrprogramm des Charisma-Teilnehmers

Achtung neue Modusnamen (wie im MMI):

0x1 = Komfort = Comfort
0x2 = Dynamik = Auto
0x3 = Sport = Dynamic";
CM_ SG_ 1336 AFS_Charisma_Status "Charisma Systemstatus des Charisma-Teilnehmers

Wert 0x3 ist nur für Fahrzeuge ab MQB relevant";
CM_ SG_ 1336 AFS_Charisma_Umschaltung "Erkennung  Umschaltaufforderung des Charisma-Teilnehmers";
CM_ SG_ 1336 AFS_01_alt "Veraltet-Bit für die Signale:

Botschaft Charisma_02:
AFS_Charisma_FahrPr
AFS_Charisma_Status
AFS_Charisma_Umschaltung";
CM_ BO_ 1338 "D4";
CM_ SG_ 1338 EPS_Charisma_FahrPr "Rückmeldung des aktuellen Charisma-Status der EPS";
CM_ SG_ 1338 EPS_Charisma_Status "Rückmeldung an den Charisma-Master

Wert 0x3 ist nur für Fahrzeuge ab MQB relevant";
CM_ SG_ 1338 EPS_Charisma_Umschaltung "Rückmeldung an den Charisma-Master";
CM_ SG_ 1338 EPS_FR_alt "Veraltet-Bit für die Signale:

Botschaft Charisma_04:
EPS_Charisma_FahrPr
EPS_Charisma_Status
EPS_Charisma_Umschaltung

 ";
CM_ SG_ 1338 ACC_Charisma_FahrPr "MLB, Rückmeldung des aktuellen Charisma-Status des ACC";
CM_ SG_ 1338 ACC_Charisma_Status "Rückmeldung an den Charisma-Master

Wert 0x3 ist nur für Fahrzeuge ab MQB relevant";
CM_ SG_ 1338 ACC_Charisma_Umschaltung "Rückmeldung an den Charisma-Master";
CM_ SG_ 1338 ACC_04_alt "Veraltet-Bit für die Signale:

Botschaft Charisma_04:
ACC_Charisma_FahrPr
ACC_Charisma_Status
ACC_Charisma_Umschaltung";
CM_ SG_ 1338 SAK_Charisma_FahrPr "Rückmeldung des aktuellen Charisma-Status des Soundaktors";
CM_ SG_ 1338 SAK_Charisma_Status "Rückmeldung an den Charisma-Master

Wert 0x3 ist nur für Fahrzeuge ab MQB relevant";
CM_ SG_ 1338 SAK_Charisma_Umschaltung "Erkennung  Umschaltaufforderung des Charisma-Teilnehmers";
CM_ SG_ 1338 SAK_01_alt "Veraltet-Bit für die Signale:

Botschaft Charisma_04:
SAK_Charisma_FahrPr
SAK_Charisma_Status
SAK_Charisma_Umschaltung";
CM_ SG_ 1338 NR_Niveaufunktion_aktiv "AU57x:
Signal meldet DriveSelect, wann die lift-Funktion aktiv ist damit das Fahrprogramm auf allroad gewechselt werden kann.

MLBevo:
Das Signal wird benötigt um eine gezielte Sonderreaktion bei Verlassen des Liftmodus einzuleiten.";
CM_ SG_ 1338 Daempfer_01_alt "Veraltet-Bit für die Signale:

Botschaft Charisma_02:
DR_Charisma_FahrPr
DR_Charisma_Status
DR_Charisma_Umschaltung

Botschaft Charisma_04:
NR_Niveaufunktion_aktiv
";
CM_ SG_ 1338 CHA_04_va_57 "
Platzhalter für veraltet Bit in Gatewaybotschaften

GWxx_va_yz

xx: Index der Gatewaybotschaft
y: Byteposition des veraltet Bits
z: Bitposition des veraltet Bits";
CM_ SG_ 1338 CHA_04_va_67 "
Platzhalter für veraltet Bit in Gatewaybotschaften

GWxx_va_yz

xx: Index der Gatewaybotschaft
y: Byteposition des veraltet Bits
z: Bitposition des veraltet Bits";
CM_ SG_ 1338 CHA_04_va_77 "
Platzhalter für veraltet Bit in Gatewaybotschaften

GWxx_va_yz

xx: Index der Gatewaybotschaft
y: Byteposition des veraltet Bits
z: Bitposition des veraltet Bits";
CM_ SG_ 1338 CHA_04_va_87 "
Platzhalter für veraltet Bit in Gatewaybotschaften

GWxx_va_yz

xx: Index der Gatewaybotschaft
y: Byteposition des veraltet Bits
z: Bitposition des veraltet Bits";
BA_DEF_  "GenNWMApBusSleep" STRING ;
BA_DEF_  "GenNWMApCanNormal" STRING ;
BA_DEF_  "GenNWMApCanOff" STRING ;
BA_DEF_  "GenNWMApCanOn" STRING ;
BA_DEF_  "GenNWMApCanSleep" STRING ;
BA_DEF_  "GenNWMApCanWakeUp" STRING ;
BA_DEF_  "GenNWMGotoMode_Awake" STRING ;
BA_DEF_  "GenNWMGotoMode_BusSleep" STRING ;
BA_DEF_  "GenNWMSleepTime" INT 0 1000000;
BA_DEF_  "GenNWMTalkNM" STRING ;
BA_DEF_  "Manufacturer" STRING ;
BA_DEF_  "NmhBaseAddress" HEX 0 536870911;
BA_DEF_  "NmhMessageCount" INT 0 256;
BA_DEF_  "NmType" STRING ;
BA_DEF_  "VAGTP20_SetupMessageCount" INT 0 255;
BA_DEF_  "VAGTP20_SetupStartAddress" HEX 0 2047;
BA_DEF_  "VersionDay" INT 1 31;
BA_DEF_  "VersionMonth" INT 1 12;
BA_DEF_  "VersionWeek" INT 1 52;
BA_DEF_  "VersionYear" INT 0 99;
BA_DEF_  "VersionNumber" INT 0 65535;
BA_DEF_  "Baudrate" INT 0 1000000;
BA_DEF_  "SamplePointMin" INT 1 100;
BA_DEF_  "SamplePointMax" INT 1 100;
BA_DEF_  "SyncJumpWidthMin" INT 1 4;
BA_DEF_  "SyncJumpWidthMax" INT 1 4;
BA_DEF_  "NmhTimeoutTimer" INT 0 65535;
BA_DEF_  "NmhWaitBusSleepTimer" INT 0 65535;
BA_DEF_  "NmhPrepareBusSleepTimer" INT 0 65535;
BA_DEF_  "NmhLongTimer" INT 0 65535;
BA_DEF_  "NmhNStart" INT 0 255;
BA_DEF_ BU_  "GenNodAutoGenDsp" ENUM  "No","Yes";
BA_DEF_ BU_  "GenNodAutoGenSnd" ENUM  "No","Yes";
BA_DEF_ BU_  "GenNodSleepTime" INT 0 1000000;
BA_DEF_ BU_  "ILUsed" ENUM  "No","Yes";
BA_DEF_ BU_  "ECUVariantDefault" ENUM  "No","Yes";
BA_DEF_ BU_  "NodeLayerModules" STRING ;
BA_DEF_ BU_  "NmhNode" ENUM  "No","Yes";
BA_DEF_ BU_  "NmNode" ENUM  "No","Yes";
BA_DEF_ BO_  "DiagRequest" ENUM  "No","Yes";
BA_DEF_ BO_  "DiagResponse" ENUM  "No","Yes";
BA_DEF_ BO_  "DiagState" ENUM  "No","Yes";
BA_DEF_ BO_  "GenMsgChkConstant" HEX 0 4095;
BA_DEF_ BO_  "GenMsgCycleTime" INT 0 65535;
BA_DEF_ BO_  "GenMsgCycleTimeFast" INT 0 65535;
BA_DEF_ BO_  "GenMsgDelayTime" INT 0 100000;
BA_DEF_ BO_  "GenMsgILSupport" ENUM  "No","Yes";
BA_DEF_ BO_  "GenMsgNrOfRepetition" INT 0 100;
BA_DEF_ BO_  "GenMsgPDUConstants" STRING ;
BA_DEF_ BO_  "GenMsgSendType" ENUM  "Cyclic","not_used","not_used","not_used","not_used","not_used","not_used","IfActive","NoMsgSendType";
BA_DEF_ BO_  "GenMsgStartDelayTime" INT 0 100000;
BA_DEF_ BO_  "NmMessage" ENUM  "No","Yes";
BA_DEF_ BO_  "NmhMessage" ENUM  "No","Yes";
BA_DEF_ BO_  "MsgType" ENUM  "Application","NM ","NMH","TP2.0","ISO-TP ","BAP","EID";
BA_DEF_ BO_  "VAGTP20_API" HEX 0 255;
BA_DEF_ BO_  "VAGTP20_DynConnection" ENUM  "No","Yes";
BA_DEF_ BO_  "VAGTP20_DynSetup" ENUM  "No","Yes";
BA_DEF_ BO_  "VAGTP20_StatConnection" ENUM  "No","Yes";
BA_DEF_ SG_  "GenSigActiveRepetitions" INT -2147483648 2147483647;
BA_DEF_ SG_  "GenSigInactiveValue" INT -2147483648 2147483647;
BA_DEF_ SG_  "GenSigSendType" ENUM  "Cyclic","OnWrite","OnWriteWithRepetition","OnChange","OnChangeWithRepetition","IfActive","IfActiveWithRepetition","NoSigSendType","OnChangeAndIfActive","OnChangeAndIfActiveWithRepetition";
BA_DEF_ SG_  "GenSigStartValue" INT -2147483648 2147483647;
BA_DEF_ SG_  "NWM-WakeupAllowed" ENUM  "No","Yes";
BA_DEF_ SG_  "GenSigFuncType" ENUM  "NoFunction","MsgCounter","CRC-8","XOR","XOR-2","DatedBit","SW-Kl15","CHK","Constant","Protocol","CRC-8-SAE_J1850";
BA_DEF_ SG_  "GenSigSwitchedByIgnition" ENUM  "No","Yes";
BA_DEF_ SG_  "Fehlerwert" HEX 0 2147483647;
BA_DEF_ SG_  "GenSigMissingSourceValue" HEX 0 2147483647;
BA_DEF_REL_ BU_SG_REL_  "GenSigTimeoutTime" INT 0 65535;
BA_DEF_DEF_  "GenNWMApBusSleep" "";
BA_DEF_DEF_  "GenNWMApCanNormal" "";
BA_DEF_DEF_  "GenNWMApCanOff" "";
BA_DEF_DEF_  "GenNWMApCanOn" "";
BA_DEF_DEF_  "GenNWMApCanSleep" "";
BA_DEF_DEF_  "GenNWMApCanWakeUp" "";
BA_DEF_DEF_  "GenNWMGotoMode_Awake" "";
BA_DEF_DEF_  "GenNWMGotoMode_BusSleep" "";
BA_DEF_DEF_  "GenNWMSleepTime" 0;
BA_DEF_DEF_  "GenNWMTalkNM" "";
BA_DEF_DEF_  "Manufacturer" "";
BA_DEF_DEF_  "NmhBaseAddress" 0;
BA_DEF_DEF_  "NmhMessageCount" 1;
BA_DEF_DEF_  "NmType" "None";
BA_DEF_DEF_  "VAGTP20_SetupMessageCount" 0;
BA_DEF_DEF_  "VAGTP20_SetupStartAddress" 0;
BA_DEF_DEF_  "VersionDay" 3;
BA_DEF_DEF_  "VersionMonth" 11;
BA_DEF_DEF_  "VersionWeek" 44;
BA_DEF_DEF_  "VersionYear" 11;
BA_DEF_DEF_  "VersionNumber" 0;
BA_DEF_DEF_  "Baudrate" 0;
BA_DEF_DEF_  "SamplePointMin" 1;
BA_DEF_DEF_  "SamplePointMax" 1;
BA_DEF_DEF_  "SyncJumpWidthMin" 1;
BA_DEF_DEF_  "SyncJumpWidthMax" 1;
BA_DEF_DEF_  "NmhTimeoutTimer" 0;
BA_DEF_DEF_  "NmhWaitBusSleepTimer" 0;
BA_DEF_DEF_  "NmhPrepareBusSleepTimer" 0;
BA_DEF_DEF_  "NmhLongTimer" 0;
BA_DEF_DEF_  "NmhNStart" 0;
BA_DEF_DEF_  "GenNodAutoGenDsp" "Yes";
BA_DEF_DEF_  "GenNodAutoGenSnd" "Yes";
BA_DEF_DEF_  "GenNodSleepTime" 0;
BA_DEF_DEF_  "ILUsed" "Yes";
BA_DEF_DEF_  "ECUVariantDefault" "Yes";
BA_DEF_DEF_  "NodeLayerModules" "";
BA_DEF_DEF_  "NmhNode" "Yes";
BA_DEF_DEF_  "NmNode" "No";
BA_DEF_DEF_REL_ "GenSigTimeoutTime" 0;
BA_DEF_DEF_  "DiagRequest" "No";
BA_DEF_DEF_  "DiagResponse" "No";
BA_DEF_DEF_  "DiagState" "No";
BA_DEF_DEF_  "GenMsgChkConstant" 0;
BA_DEF_DEF_  "GenMsgCycleTime" 0;
BA_DEF_DEF_  "GenMsgCycleTimeFast" 0;
BA_DEF_DEF_  "GenMsgDelayTime" 0;
BA_DEF_DEF_  "GenMsgILSupport" "No";
BA_DEF_DEF_  "GenMsgNrOfRepetition" 0;
BA_DEF_DEF_  "GenMsgPDUConstants" "";
BA_DEF_DEF_  "GenMsgSendType" "NoMsgSendType";
BA_DEF_DEF_  "GenMsgStartDelayTime" 0;
BA_DEF_DEF_  "NmMessage" "No";
BA_DEF_DEF_  "NmhMessage" "No";
BA_DEF_DEF_  "MsgType" "Application";
BA_DEF_DEF_  "VAGTP20_API" 0;
BA_DEF_DEF_  "VAGTP20_DynConnection" "No";
BA_DEF_DEF_  "VAGTP20_DynSetup" "No";
BA_DEF_DEF_  "VAGTP20_StatConnection" "No";
BA_DEF_DEF_  "GenSigActiveRepetitions" 0;
BA_DEF_DEF_  "GenSigInactiveValue" 0;
BA_DEF_DEF_  "GenSigSendType" "NoSigSendType";
BA_DEF_DEF_  "GenSigStartValue" 0;
BA_DEF_DEF_  "NWM-WakeupAllowed" "No";
BA_DEF_DEF_  "GenSigFuncType" "NoFunction";
BA_DEF_DEF_  "GenSigSwitchedByIgnition" "Yes";
BA_DEF_DEF_  "Fehlerwert" 0;
BA_DEF_DEF_  "GenSigMissingSourceValue" 0;
BA_ "NmhNStart" 5;
BA_ "NmhLongTimer" 200;
BA_ "NmhPrepareBusSleepTimer" 500;
BA_ "NmhWaitBusSleepTimer" 750;
BA_ "NmhTimeoutTimer" 1000;
BA_ "SyncJumpWidthMax" 4;
BA_ "SyncJumpWidthMin" 2;
BA_ "SamplePointMax" 84;
BA_ "SamplePointMin" 80;
BA_ "Baudrate" 500000;
BA_ "VersionNumber" 1100;
BA_ "VersionDay" 4;
BA_ "VAGTP20_SetupStartAddress" 512;
BA_ "VAGTP20_SetupMessageCount" 128;
BA_ "NmType" "NM-High";
BA_ "NmhMessageCount" 64;
BA_ "NmhBaseAddress" 1728;
BA_ "Manufacturer" "PAG";
BA_ "GenNWMTalkNM" "Nmh_ReqNetOn()";
BA_ "GenNWMSleepTime" 4000;
BA_ "GenNWMGotoMode_BusSleep" "Nmh_ReqNetOff()";
BA_ "GenNWMGotoMode_Awake" "Nmh_ReqNetOn()";
BA_ "GenNWMApCanOn" "NMIndnetOn()";
BA_ "GenNWMApCanOff" "NMIndnetOff()";
BA_ "GenNWMApBusSleep" "NMIndNetSDN()";
BA_ "NodeLayerModules" BU_ ADR_PAG_X2 "NMHigh.DLL";
BA_ "GenNodSleepTime" BU_ ADR_PAG_X2 4000;
BA_ "NmhNode" BU_ BAP_Tester 0;
BA_ "GenNodSleepTime" BU_ BAP_Tester 4000;
BA_ "NodeLayerModules" BU_ GW_App_PAG_PF "NMHigh.DLL";
BA_ "GenNodSleepTime" BU_ GW_App_PAG_PF 4000;
BA_ "NmhNode" BU_ GW_Routing_PAG_PF 0;
BA_ "GenNodSleepTime" BU_ GW_Routing_PAG_PF 4000;
BA_ "NodeLayerModules" BU_ Klima_PAG_PF "NMHigh.DLL";
BA_ "GenNodSleepTime" BU_ Klima_PAG_PF 4000;
BA_ "NmhNode" BU_ Klimakomp_Dash_PAG_PF 0;
BA_ "GenNodSleepTime" BU_ Klimakomp_Dash_PAG_PF 4000;
BA_ "NodeLayerModules" BU_ Kombi_PAG_PF "NMHigh.DLL";
BA_ "GenNodSleepTime" BU_ Kombi_PAG_PF 4000;
BA_ "NodeLayerModules" BU_ Miko_PAG_X2 "NMHigh.DLL";
BA_ "GenNodSleepTime" BU_ Miko_PAG_X2 4000;
BA_ "NodeLayerModules" BU_ OCU_PAG_PF "NMHigh.DLL";
BA_ "GenNodSleepTime" BU_ OCU_PAG_PF 4000;
BA_ "NodeLayerModules" BU_ RDK_High_PAG_PF "NMHigh.DLL";
BA_ "GenNodSleepTime" BU_ RDK_High_PAG_PF 4000;
BA_ "GenMsgSendType" BO_ 192 0;
BA_ "GenMsgNrOfRepetition" BO_ 192 5;
BA_ "GenMsgILSupport" BO_ 192 1;
BA_ "GenMsgDelayTime" BO_ 192 50;
BA_ "GenMsgCycleTimeFast" BO_ 192 100;
BA_ "GenMsgCycleTime" BO_ 192 500;
BA_ "GenMsgSendType" BO_ 194 0;
BA_ "GenMsgNrOfRepetition" BO_ 194 5;
BA_ "GenMsgILSupport" BO_ 194 1;
BA_ "GenMsgDelayTime" BO_ 194 10;
BA_ "GenMsgCycleTimeFast" BO_ 194 50;
BA_ "GenMsgCycleTime" BO_ 194 100;
BA_ "GenMsgSendType" BO_ 64 0;
BA_ "GenMsgILSupport" BO_ 64 1;
BA_ "GenMsgDelayTime" BO_ 64 10;
BA_ "GenMsgCycleTime" BO_ 64 50;
BA_ "GenMsgChkConstant" BO_ 64 64;
BA_ "GenMsgSendType" BO_ 1632 0;
BA_ "GenMsgPDUConstants" BO_ 1632 "0x44,0x44,0x44,0x44,0x44,0x44,0x44,0x44,0x44,0x44,0x44,0x44,0x44,0x44,0x44,0x44";
BA_ "GenMsgILSupport" BO_ 1632 1;
BA_ "GenMsgCycleTime" BO_ 1632 1000;
BA_ "GenMsgChkConstant" BO_ 1632 68;
BA_ "GenMsgSendType" BO_ 1634 0;
BA_ "GenMsgILSupport" BO_ 1634 1;
BA_ "GenMsgDelayTime" BO_ 1634 50;
BA_ "GenMsgCycleTime" BO_ 1634 1000;
BA_ "GenMsgSendType" BO_ 1697 0;
BA_ "GenMsgILSupport" BO_ 1697 1;
BA_ "GenMsgDelayTime" BO_ 1697 50;
BA_ "GenMsgCycleTime" BO_ 1697 500;
BA_ "GenMsgSendType" BO_ 1409 0;
BA_ "GenMsgILSupport" BO_ 1409 1;
BA_ "GenMsgDelayTime" BO_ 1409 50;
BA_ "GenMsgCycleTime" BO_ 1409 200;
BA_ "GenMsgSendType" BO_ 900 0;
BA_ "GenMsgILSupport" BO_ 900 1;
BA_ "GenMsgDelayTime" BO_ 900 30;
BA_ "GenMsgCycleTimeFast" BO_ 900 50;
BA_ "GenMsgCycleTime" BO_ 900 100;
BA_ "GenMsgSendType" BO_ 1658 0;
BA_ "GenMsgILSupport" BO_ 1658 1;
BA_ "GenMsgCycleTime" BO_ 1658 500;
BA_ "GenMsgSendType" BO_ 1635 0;
BA_ "GenMsgILSupport" BO_ 1635 1;
BA_ "GenMsgCycleTime" BO_ 1635 100;
BA_ "GenMsgSendType" BO_ 1326 0;
BA_ "GenMsgILSupport" BO_ 1326 1;
BA_ "GenMsgCycleTime" BO_ 1326 250;
BA_ "GenMsgSendType" BO_ 867 7;
BA_ "GenMsgNrOfRepetition" BO_ 867 5;
BA_ "GenMsgILSupport" BO_ 867 1;
BA_ "GenMsgDelayTime" BO_ 867 5;
BA_ "GenMsgCycleTimeFast" BO_ 867 50;
BA_ "GenMsgSendType" BO_ 687 0;
BA_ "GenMsgILSupport" BO_ 687 1;
BA_ "GenMsgCycleTime" BO_ 687 50;
BA_ "GenMsgSendType" BO_ 1438 0;
BA_ "GenMsgILSupport" BO_ 1438 1;
BA_ "GenMsgCycleTime" BO_ 1438 500;
BA_ "GenMsgSendType" BO_ 1482 0;
BA_ "GenMsgPDUConstants" BO_ 1482 "0x43,0x43,0x43,0x43,0x43,0x43,0x43,0x43,0x43,0x43,0x43,0x43,0x43,0x43,0x43,0x43";
BA_ "GenMsgILSupport" BO_ 1482 1;
BA_ "GenMsgDelayTime" BO_ 1482 50;
BA_ "GenMsgCycleTime" BO_ 1482 500;
BA_ "GenMsgChkConstant" BO_ 1482 67;
BA_ "GenMsgSendType" BO_ 1519 0;
BA_ "GenMsgILSupport" BO_ 1519 1;
BA_ "GenMsgCycleTime" BO_ 1519 500;
BA_ "GenMsgSendType" BO_ 1628 0;
BA_ "GenMsgILSupport" BO_ 1628 1;
BA_ "GenMsgCycleTime" BO_ 1628 500;
BA_ "GenMsgSendType" BO_ 903 0;
BA_ "GenMsgPDUConstants" BO_ 903 "0xde,0xde,0xde,0xde,0xde,0xde,0xde,0xde,0xde,0xde,0xde,0xde,0xde,0xde,0xde,0xde";
BA_ "GenMsgILSupport" BO_ 903 1;
BA_ "GenMsgCycleTime" BO_ 903 100;
BA_ "GenMsgNrOfRepetition" BO_ 901 5;
BA_ "GenMsgILSupport" BO_ 901 1;
BA_ "GenMsgDelayTime" BO_ 901 10;
BA_ "GenMsgCycleTimeFast" BO_ 901 100;
BA_ "GenMsgChkConstant" BO_ 901 134;
BA_ "GenMsgSendType" BO_ 1336 0;
BA_ "GenMsgILSupport" BO_ 1336 1;
BA_ "GenMsgCycleTime" BO_ 1336 200;
BA_ "GenMsgSendType" BO_ 1338 0;
BA_ "GenMsgILSupport" BO_ 1338 1;
BA_ "GenMsgCycleTime" BO_ 1338 200;
BA_ "GenSigSwitchedByIgnition" SG_ 192 Adr_Clima_Mono 0;
BA_ "GenSigSendType" SG_ 192 Adr_Clima_Mono 4;
BA_ "GenSigSwitchedByIgnition" SG_ 192 Adr_T_LVT_O 0;
BA_ "NWM-WakeupAllowed" SG_ 192 Adr_T_LVT_O 1;
BA_ "GenSigSendType" SG_ 192 Adr_T_LVT_O 4;
BA_ "GenSigSwitchedByIgnition" SG_ 192 Adr_T_LVT_M 0;
BA_ "NWM-WakeupAllowed" SG_ 192 Adr_T_LVT_M 1;
BA_ "GenSigSendType" SG_ 192 Adr_T_LVT_M 4;
BA_ "GenSigSwitchedByIgnition" SG_ 192 Adr_T_LVT_U 0;
BA_ "NWM-WakeupAllowed" SG_ 192 Adr_T_LVT_U 1;
BA_ "GenSigSendType" SG_ 192 Adr_T_LVT_U 4;
BA_ "GenSigSwitchedByIgnition" SG_ 192 Adr_AC_Menue_LED_an 0;
BA_ "NWM-WakeupAllowed" SG_ 192 Adr_AC_Menue_LED_an 1;
BA_ "GenSigSendType" SG_ 192 Adr_AC_Menue_LED_an 4;
BA_ "GenSigSwitchedByIgnition" SG_ 192 Adr_Phone_LED_an 0;
BA_ "NWM-WakeupAllowed" SG_ 192 Adr_Phone_LED_an 1;
BA_ "GenSigSendType" SG_ 192 Adr_Phone_LED_an 4;
BA_ "GenSigSwitchedByIgnition" SG_ 192 Adr_Media_LED_an 0;
BA_ "NWM-WakeupAllowed" SG_ 192 Adr_Media_LED_an 1;
BA_ "GenSigSendType" SG_ 192 Adr_Media_LED_an 4;
BA_ "GenSigSwitchedByIgnition" SG_ 192 Adr_Tuner_LED_an 0;
BA_ "NWM-WakeupAllowed" SG_ 192 Adr_Tuner_LED_an 1;
BA_ "GenSigSendType" SG_ 192 Adr_Tuner_LED_an 4;
BA_ "GenSigSwitchedByIgnition" SG_ 192 Adr_Car_LED_an 0;
BA_ "NWM-WakeupAllowed" SG_ 192 Adr_Car_LED_an 1;
BA_ "GenSigSendType" SG_ 192 Adr_Car_LED_an 4;
BA_ "GenSigSwitchedByIgnition" SG_ 192 Adr_Info_LED_an 0;
BA_ "NWM-WakeupAllowed" SG_ 192 Adr_Info_LED_an 1;
BA_ "GenSigSendType" SG_ 192 Adr_Info_LED_an 4;
BA_ "GenSigSwitchedByIgnition" SG_ 192 Adr_Navi_LED_an 0;
BA_ "NWM-WakeupAllowed" SG_ 192 Adr_Navi_LED_an 1;
BA_ "GenSigSendType" SG_ 192 Adr_Navi_LED_an 4;
BA_ "GenSigSwitchedByIgnition" SG_ 192 Adr_Alive_Cnt 0;
BA_ "NWM-WakeupAllowed" SG_ 192 Adr_Alive_Cnt 1;
BA_ "GenSigSendType" SG_ 192 Adr_Alive_Cnt 4;
BA_ "GenSigSwitchedByIgnition" SG_ 192 Adr_Pos_En 0;
BA_ "NWM-WakeupAllowed" SG_ 192 Adr_Pos_En 1;
BA_ "GenSigSendType" SG_ 192 Adr_Pos_En 4;
BA_ "GenSigSwitchedByIgnition" SG_ 192 Adr_Display_Status 0;
BA_ "NWM-WakeupAllowed" SG_ 192 Adr_Display_Status 1;
BA_ "GenSigSendType" SG_ 192 Adr_Display_Status 4;
BA_ "GenSigSwitchedByIgnition" SG_ 192 Adr_Active_Character_Page 0;
BA_ "NWM-WakeupAllowed" SG_ 192 Adr_Active_Character_Page 1;
BA_ "GenSigSendType" SG_ 192 Adr_Active_Character_Page 4;
BA_ "GenSigSwitchedByIgnition" SG_ 192 Adr_Chr_Mode 0;
BA_ "NWM-WakeupAllowed" SG_ 192 Adr_Chr_Mode 1;
BA_ "GenSigSendType" SG_ 192 Adr_Chr_Mode 4;
BA_ "GenSigSwitchedByIgnition" SG_ 192 Adr_Gst_Mode 0;
BA_ "NWM-WakeupAllowed" SG_ 192 Adr_Gst_Mode 1;
BA_ "GenSigSendType" SG_ 192 Adr_Gst_Mode 4;
BA_ "GenSigSwitchedByIgnition" SG_ 194 Adr_Konfig_Datenfeld 0;
BA_ "NWM-WakeupAllowed" SG_ 194 Adr_Konfig_Datenfeld 1;
BA_ "GenSigSendType" SG_ 194 Adr_Konfig_Datenfeld 4;
BA_ "GenSigSwitchedByIgnition" SG_ 194 Adr_KI_BC_Rolle_Konfig 0;
BA_ "NWM-WakeupAllowed" SG_ 194 Adr_KI_BC_Rolle_Konfig 1;
BA_ "GenSigSendType" SG_ 194 Adr_KI_BC_Rolle_Konfig 4;
BA_ "GenSigSwitchedByIgnition" SG_ 194 Adr_KI_BC_Rolle_Datenfeld 0;
BA_ "GenSigSendType" SG_ 194 Adr_KI_BC_Rolle_Datenfeld 4;
BA_ "GenSigSwitchedByIgnition" SG_ 194 Adr_Joker_Taste 0;
BA_ "GenSigSendType" SG_ 194 Adr_Joker_Taste 4;
BA_ "Fehlerwert" SG_ 194 Adr_KL58d 127;
BA_ "GenSigSwitchedByIgnition" SG_ 194 Adr_KL58d 0;
BA_ "GenSigStartValue" SG_ 194 Adr_KL58d 126;
BA_ "GenSigSendType" SG_ 194 Adr_KL58d 4;
BA_ "Fehlerwert" SG_ 194 Adr_KI_Helligkeit 127;
BA_ "GenSigSwitchedByIgnition" SG_ 194 Adr_KI_Helligkeit 0;
BA_ "GenSigStartValue" SG_ 194 Adr_KI_Helligkeit 126;
BA_ "Fehlerwert" SG_ 194 Adr_Miko_Helligkeit 127;
BA_ "GenSigSwitchedByIgnition" SG_ 194 Adr_Miko_Helligkeit 0;
BA_ "GenSigStartValue" SG_ 194 Adr_Miko_Helligkeit 126;
BA_ "GenSigFuncType" SG_ 64 Airbag_01_CHK 3;
BA_ "GenSigSendType" SG_ 64 Airbag_01_CHK 0;
BA_ "GenSigFuncType" SG_ 64 Airbag_01_BZ 1;
BA_ "GenSigSendType" SG_ 64 Airbag_01_BZ 0;
BA_ "GenSigStartValue" SG_ 64 AB_RGS_Anst 8;
BA_ "GenSigSendType" SG_ 64 AB_RGS_Anst 3;
BA_ "GenSigSendType" SG_ 64 AB_Front_Crash 3;
BA_ "GenSigSendType" SG_ 64 AB_Heck_Crash 3;
BA_ "GenSigSendType" SG_ 64 AB_SF_Crash 3;
BA_ "GenSigSendType" SG_ 64 AB_SB_Crash 3;
BA_ "GenSigSendType" SG_ 64 AB_Rollover_Crash 3;
BA_ "GenSigSendType" SG_ 64 AB_Crash_Int 3;
BA_ "GenSigStartValue" SG_ 64 AB_Lampe 1;
BA_ "GenSigSendType" SG_ 64 AB_Lampe 0;
BA_ "GenSigSendType" SG_ 64 AB_Deaktiviert 0;
BA_ "GenSigStartValue" SG_ 64 AB_VB_deaktiviert 1;
BA_ "GenSigSendType" SG_ 64 AB_VB_deaktiviert 0;
BA_ "GenSigSendType" SG_ 64 AB_Systemfehler 0;
BA_ "GenSigSendType" SG_ 64 AB_Diagnose 0;
BA_ "GenSigSendType" SG_ 64 AB_Stellgliedtest 0;
BA_ "GenSigSendType" SG_ 64 AB_Erh_Auf_VB 0;
BA_ "GenSigSendType" SG_ 64 AB_Gurtwarn_VF 0;
BA_ "GenSigSendType" SG_ 64 AB_Gurtwarn_VB 0;
BA_ "GenSigSendType" SG_ 64 AB_Anzeige_Fussg 0;
BA_ "GenSigSendType" SG_ 64 AB_Texte_AKS 0;
BA_ "GenSigStartValue" SG_ 64 AB_PAO_Leuchte_Anf 1;
BA_ "GenSigSendType" SG_ 64 AB_PAO_Leuchte_Anf 0;
BA_ "GenSigFuncType" SG_ 64 AB_MKB_gueltig 8;
BA_ "GenSigSendType" SG_ 64 AB_MKB_gueltig 0;
BA_ "GenSigSendType" SG_ 64 AB_Versorgungsspannung 0;
BA_ "GenSigSendType" SG_ 64 AB_Deaktivierung_HV 3;
BA_ "GenSigSwitchedByIgnition" SG_ 64 AB_EDR_Trigger 0;
BA_ "GenSigSendType" SG_ 64 AB_EDR_Trigger 3;
BA_ "GenSigSendType" SG_ 64 AB_KD_Fehler 0;
BA_ "GenSigFuncType" SG_ 1632 Airbag_02_CRC 2;
BA_ "GenSigSendType" SG_ 1632 Airbag_02_CRC 0;
BA_ "GenSigFuncType" SG_ 1632 Airbag_02_BZ 1;
BA_ "GenSigSendType" SG_ 1632 Airbag_02_BZ 0;
BA_ "Fehlerwert" SG_ 1632 AB_Belegung_VB 1;
BA_ "GenSigSendType" SG_ 1632 AB_Belegung_VB 0;
BA_ "GenSigStartValue" SG_ 1632 AB_Gurtschloss_FA 1;
BA_ "GenSigSendType" SG_ 1632 AB_Gurtschloss_FA 0;
BA_ "GenSigStartValue" SG_ 1632 AB_Gurtschloss_BF 1;
BA_ "GenSigSendType" SG_ 1632 AB_Gurtschloss_BF 0;
BA_ "GenSigStartValue" SG_ 1632 AB_Gurtschloss_Reihe2_FA 1;
BA_ "GenSigSendType" SG_ 1632 AB_Gurtschloss_Reihe2_FA 0;
BA_ "GenSigStartValue" SG_ 1632 AB_Gurtschloss_Reihe2_MI 1;
BA_ "GenSigSendType" SG_ 1632 AB_Gurtschloss_Reihe2_MI 0;
BA_ "GenSigStartValue" SG_ 1632 AB_Gurtschloss_Reihe2_BF 1;
BA_ "GenSigSendType" SG_ 1632 AB_Gurtschloss_Reihe2_BF 0;
BA_ "GenSigStartValue" SG_ 1632 AB_Gurtschloss_Reihe3_FA 1;
BA_ "GenSigSendType" SG_ 1632 AB_Gurtschloss_Reihe3_FA 0;
BA_ "GenSigStartValue" SG_ 1632 AB_Gurtschloss_Reihe3_MI 1;
BA_ "GenSigSendType" SG_ 1632 AB_Gurtschloss_Reihe3_MI 0;
BA_ "GenSigStartValue" SG_ 1632 AB_Gurtschloss_Reihe3_BF 1;
BA_ "GenSigSendType" SG_ 1632 AB_Gurtschloss_Reihe3_BF 0;
BA_ "Fehlerwert" SG_ 1632 AB_Sitzpos_Sens_FA 1;
BA_ "GenSigSendType" SG_ 1632 AB_Sitzpos_Sens_FA 0;
BA_ "Fehlerwert" SG_ 1632 AB_Sitzpos_Sens_BF 1;
BA_ "GenSigSendType" SG_ 1632 AB_Sitzpos_Sens_BF 0;
BA_ "GenSigSwitchedByIgnition" SG_ 1490 BAP_D2_Header 0;
BA_ "GenSigSendType" SG_ 1490 BAP_D2_Header 3;
BA_ "GenSigSwitchedByIgnition" SG_ 1491 BAP_D3_Header 0;
BA_ "GenSigSendType" SG_ 1491 BAP_D3_Header 3;
BA_ "GenSigSwitchedByIgnition" SG_ 1492 BAP_D4_Header 0;
BA_ "GenSigSendType" SG_ 1492 BAP_D4_Header 3;
BA_ "GenSigSwitchedByIgnition" SG_ 1493 BAP_D5_Header 0;
BA_ "GenSigSendType" SG_ 1493 BAP_D5_Header 3;
BA_ "GenSigSwitchedByIgnition" SG_ 1565 BAP_1D_Header 0;
BA_ "GenSigSendType" SG_ 1565 BAP_1D_Header 3;
BA_ "GenSigSwitchedByIgnition" SG_ 1599 BAP_Debug_Cmd 0;
BA_ "GenSigSendType" SG_ 1599 BAP_Debug_Cmd 3;
BA_ "GenSigSwitchedByIgnition" SG_ 1598 BAP_Debug_Data 0;
BA_ "GenSigSendType" SG_ 1598 BAP_Debug_Data 3;
BA_ "GenSigSwitchedByIgnition" SG_ 1583 BAP_2F_Header 0;
BA_ "GenSigSendType" SG_ 1583 BAP_2F_Header 3;
BA_ "GenSigSwitchedByIgnition" SG_ 1634 BCM1_Bremsbelag_Warn 0;
BA_ "GenSigSendType" SG_ 1634 BCM1_Bremsbelag_Warn 3;
BA_ "GenSigSwitchedByIgnition" SG_ 1634 BCM1_Bremsfluessigkeit_Warn 0;
BA_ "GenSigSendType" SG_ 1634 BCM1_Bremsfluessigkeit_Warn 3;
BA_ "GenSigSwitchedByIgnition" SG_ 1634 BCM1_Licht_Warn 0;
BA_ "GenSigSendType" SG_ 1634 BCM1_Licht_Warn 3;
BA_ "GenSigSwitchedByIgnition" SG_ 1634 BCM1_Waschwasser_Warn 0;
BA_ "GenSigSendType" SG_ 1634 BCM1_Waschwasser_Warn 3;
BA_ "GenSigSwitchedByIgnition" SG_ 1634 BCM1_Kuehlmittel_Warn 0;
BA_ "GenSigSendType" SG_ 1634 BCM1_Kuehlmittel_Warn 3;
BA_ "GenSigSwitchedByIgnition" SG_ 1634 BCM1_Gleitende_Leuchtw_Anf 0;
BA_ "GenSigSendType" SG_ 1634 BCM1_Gleitende_Leuchtw_Anf 3;
BA_ "GenSigSwitchedByIgnition" SG_ 1634 LV_Aussenlicht_def 0;
BA_ "GenSigSendType" SG_ 1634 LV_Aussenlicht_def 3;
BA_ "GenSigSwitchedByIgnition" SG_ 1634 LV_AFL_defekt 0;
BA_ "GenSigSendType" SG_ 1634 LV_AFL_defekt 3;
BA_ "GenSigSwitchedByIgnition" SG_ 1634 BCM1_Handbremse_Schalter 0;
BA_ "GenSigSendType" SG_ 1634 BCM1_Handbremse_Schalter 3;
BA_ "GenSigSwitchedByIgnition" SG_ 1634 BCM1_MH_Schalter 0;
BA_ "GenSigSendType" SG_ 1634 BCM1_MH_Schalter 3;
BA_ "GenSigSwitchedByIgnition" SG_ 1634 BCM1_MH_WIV_Schalter 0;
BA_ "GenSigSendType" SG_ 1634 BCM1_MH_WIV_Schalter 3;
BA_ "GenSigSwitchedByIgnition" SG_ 1634 BCM1_Oeldruck_Schalter 0;
BA_ "GenSigSendType" SG_ 1634 BCM1_Oeldruck_Schalter 3;
BA_ "GenSigSwitchedByIgnition" SG_ 1634 BCM1_Kl_15_HW_erkannt 0;
BA_ "GenSigSendType" SG_ 1634 BCM1_Kl_15_HW_erkannt 3;
BA_ "GenSigSwitchedByIgnition" SG_ 1634 BCM1_Lenksaeule_aktiv 0;
BA_ "GenSigSendType" SG_ 1634 BCM1_Lenksaeule_aktiv 3;
BA_ "GenSigSwitchedByIgnition" SG_ 1634 BCM1_Oeldruck_Schalter_2 0;
BA_ "GenSigSendType" SG_ 1634 BCM1_Oeldruck_Schalter_2 3;
BA_ "GenSigSwitchedByIgnition" SG_ 1634 BCM1_SRA_aktiv 0;
BA_ "GenSigSendType" SG_ 1634 BCM1_SRA_aktiv 3;
BA_ "GenSigSwitchedByIgnition" SG_ 1634 LV_Standlicht_Anzeige 0;
BA_ "GenSigSendType" SG_ 1634 LV_Standlicht_Anzeige 3;
BA_ "GenSigSwitchedByIgnition" SG_ 1634 LV_Abblendlicht_Anzeige 0;
BA_ "GenSigSendType" SG_ 1634 LV_Abblendlicht_Anzeige 3;
BA_ "GenSigSwitchedByIgnition" SG_ 1634 LV_Fernlicht_Anzeige 0;
BA_ "GenSigSendType" SG_ 1634 LV_Fernlicht_Anzeige 3;
BA_ "GenSigSwitchedByIgnition" SG_ 1634 LV_Nebellicht_Anzeige 0;
BA_ "GenSigSendType" SG_ 1634 LV_Nebellicht_Anzeige 3;
BA_ "GenSigSwitchedByIgnition" SG_ 1634 LV_Nebelschlusslicht_Anzeige 0;
BA_ "GenSigSendType" SG_ 1634 LV_Nebelschlusslicht_Anzeige 3;
BA_ "GenSigSwitchedByIgnition" SG_ 1634 LV_Tagfahrlicht_Anzeige 0;
BA_ "GenSigSendType" SG_ 1634 LV_Tagfahrlicht_Anzeige 3;
BA_ "GenSigSwitchedByIgnition" SG_ 1634 LV_AFL_aktiv_Anzeige 0;
BA_ "GenSigSendType" SG_ 1634 LV_AFL_aktiv_Anzeige 3;
BA_ "GenSigSwitchedByIgnition" SG_ 1634 BCM1_Licht_Dunkelheit_aktiv 0;
BA_ "GenSigSendType" SG_ 1634 BCM1_Licht_Dunkelheit_aktiv 3;
BA_ "GenSigSwitchedByIgnition" SG_ 1634 LV_Blinker_li_def 0;
BA_ "GenSigSendType" SG_ 1634 LV_Blinker_li_def 0;
BA_ "GenSigSwitchedByIgnition" SG_ 1634 LV_Standlicht_li_def 0;
BA_ "GenSigSendType" SG_ 1634 LV_Standlicht_li_def 0;
BA_ "GenSigSwitchedByIgnition" SG_ 1634 LV_Abblendlicht_li_def 0;
BA_ "GenSigSendType" SG_ 1634 LV_Abblendlicht_li_def 0;
BA_ "GenSigSwitchedByIgnition" SG_ 1634 LV_Fernlicht_li_def 0;
BA_ "GenSigSendType" SG_ 1634 LV_Fernlicht_li_def 0;
BA_ "GenSigSwitchedByIgnition" SG_ 1634 LV_Nebellicht_li_def 0;
BA_ "GenSigSendType" SG_ 1634 LV_Nebellicht_li_def 0;
BA_ "GenSigSwitchedByIgnition" SG_ 1634 LV_Blk_li_Seite_def 0;
BA_ "GenSigSendType" SG_ 1634 LV_Blk_li_Seite_def 0;
BA_ "GenSigSwitchedByIgnition" SG_ 1634 LV_Tagfahrlicht_li_def 0;
BA_ "GenSigSendType" SG_ 1634 LV_Tagfahrlicht_li_def 0;
BA_ "GenSigSwitchedByIgnition" SG_ 1634 BCM1_GLW_Fernlicht_Anf 0;
BA_ "GenSigSendType" SG_ 1634 BCM1_GLW_Fernlicht_Anf 3;
BA_ "GenSigSwitchedByIgnition" SG_ 1634 LV_Abblendlicht_TFL_li_def 0;
BA_ "GenSigSendType" SG_ 1634 LV_Abblendlicht_TFL_li_def 0;
BA_ "GenSigSwitchedByIgnition" SG_ 1634 LV_Nebellicht_TFL_li_def 0;
BA_ "GenSigSendType" SG_ 1634 LV_Nebellicht_TFL_li_def 0;
BA_ "GenSigSwitchedByIgnition" SG_ 1634 LV_Standlicht_TFL_li_def 0;
BA_ "GenSigSendType" SG_ 1634 LV_Standlicht_TFL_li_def 0;
BA_ "GenSigSwitchedByIgnition" SG_ 1634 LV_Abblend_Fernlicht_li_def 0;
BA_ "GenSigSendType" SG_ 1634 LV_Abblend_Fernlicht_li_def 0;
BA_ "GenSigSwitchedByIgnition" SG_ 1634 LV_FLA_aktiv_Anzeige 0;
BA_ "GenSigSendType" SG_ 1634 LV_FLA_aktiv_Anzeige 3;
BA_ "GenSigSwitchedByIgnition" SG_ 1634 LV_FLA_defekt 0;
BA_ "GenSigSendType" SG_ 1634 LV_FLA_defekt 0;
BA_ "GenSigSwitchedByIgnition" SG_ 1634 LV_FLA_Sensor_blockiert 0;
BA_ "GenSigSendType" SG_ 1634 LV_FLA_Sensor_blockiert 0;
BA_ "GenSigSwitchedByIgnition" SG_ 1634 BCM1_EasyEntry_Status 0;
BA_ "GenSigSendType" SG_ 1634 BCM1_EasyEntry_Status 3;
BA_ "GenSigSwitchedByIgnition" SG_ 1634 LV_Blinker_re_def 0;
BA_ "GenSigSendType" SG_ 1634 LV_Blinker_re_def 0;
BA_ "GenSigSwitchedByIgnition" SG_ 1634 LV_Standlicht_re_def 0;
BA_ "GenSigSendType" SG_ 1634 LV_Standlicht_re_def 0;
BA_ "GenSigSwitchedByIgnition" SG_ 1634 LV_Abblendlicht_re_def 0;
BA_ "GenSigSendType" SG_ 1634 LV_Abblendlicht_re_def 0;
BA_ "GenSigSwitchedByIgnition" SG_ 1634 LV_Fernlicht_re_def 0;
BA_ "GenSigSendType" SG_ 1634 LV_Fernlicht_re_def 0;
BA_ "GenSigSwitchedByIgnition" SG_ 1634 LV_Nebellicht_re_def 0;
BA_ "GenSigSendType" SG_ 1634 LV_Nebellicht_re_def 0;
BA_ "GenSigSwitchedByIgnition" SG_ 1634 LV_Blk_re_Seite_def 0;
BA_ "GenSigSendType" SG_ 1634 LV_Blk_re_Seite_def 0;
BA_ "GenSigSwitchedByIgnition" SG_ 1634 LV_Tagfahrlicht_re_def 0;
BA_ "GenSigSendType" SG_ 1634 LV_Tagfahrlicht_re_def 0;
BA_ "GenSigSwitchedByIgnition" SG_ 1634 BCM1_Adaptive_Lichtvert_Anf 0;
BA_ "GenSigSendType" SG_ 1634 BCM1_Adaptive_Lichtvert_Anf 3;
BA_ "GenSigSwitchedByIgnition" SG_ 1634 LV_Abblendlicht_TFL_re_def 0;
BA_ "GenSigSendType" SG_ 1634 LV_Abblendlicht_TFL_re_def 0;
BA_ "GenSigSwitchedByIgnition" SG_ 1634 LV_Nebellicht_TFL_re_def 0;
BA_ "GenSigSendType" SG_ 1634 LV_Nebellicht_TFL_re_def 0;
BA_ "GenSigSwitchedByIgnition" SG_ 1634 LV_Standlicht_TFL_re_def 0;
BA_ "GenSigSendType" SG_ 1634 LV_Standlicht_TFL_re_def 0;
BA_ "GenSigSwitchedByIgnition" SG_ 1634 LV_Abblend_Fernlicht_re_def 0;
BA_ "GenSigSendType" SG_ 1634 LV_Abblend_Fernlicht_re_def 0;
BA_ "GenSigSwitchedByIgnition" SG_ 1634 BCM1_EasyEntry_texte 0;
BA_ "GenSigSendType" SG_ 1634 BCM1_EasyEntry_texte 3;
BA_ "GenSigSwitchedByIgnition" SG_ 1634 HYB_Anf_E_Mode 0;
BA_ "GenSigSendType" SG_ 1634 HYB_Anf_E_Mode 3;
BA_ "GenSigMissingSourceValue" SG_ 1634 UGDO_Function 7;
BA_ "Fehlerwert" SG_ 1634 UGDO_Function 7;
BA_ "GenSigSwitchedByIgnition" SG_ 1634 UGDO_Function 0;
BA_ "GenSigSendType" SG_ 1634 UGDO_Function 3;
BA_ "GenSigSwitchedByIgnition" SG_ 1634 UGDO_LED_Code 0;
BA_ "GenSigSendType" SG_ 1634 UGDO_LED_Code 3;
BA_ "GenSigSwitchedByIgnition" SG_ 1697 BCM1_W_ELV 0;
BA_ "NWM-WakeupAllowed" SG_ 1697 BCM1_W_ELV 1;
BA_ "GenSigSendType" SG_ 1697 BCM1_W_ELV 0;
BA_ "GenSigSwitchedByIgnition" SG_ 1697 BCM1_W_Blinker_HR_def 0;
BA_ "NWM-WakeupAllowed" SG_ 1697 BCM1_W_Blinker_HR_def 1;
BA_ "GenSigSendType" SG_ 1697 BCM1_W_Blinker_HR_def 0;
BA_ "GenSigSwitchedByIgnition" SG_ 1697 BCM1_W_Blinker_HL_def 0;
BA_ "NWM-WakeupAllowed" SG_ 1697 BCM1_W_Blinker_HL_def 1;
BA_ "GenSigSendType" SG_ 1697 BCM1_W_Blinker_HL_def 0;
BA_ "GenSigSwitchedByIgnition" SG_ 1697 BCM1_W_LWR_def 0;
BA_ "NWM-WakeupAllowed" SG_ 1697 BCM1_W_LWR_def 1;
BA_ "GenSigSendType" SG_ 1697 BCM1_W_LWR_def 0;
BA_ "GenSigSwitchedByIgnition" SG_ 1697 BCM1_W_Parklicht 0;
BA_ "NWM-WakeupAllowed" SG_ 1697 BCM1_W_Parklicht 1;
BA_ "GenSigSendType" SG_ 1697 BCM1_W_Parklicht 0;
BA_ "GenSigSwitchedByIgnition" SG_ 1697 BCM1_ZV_Horn 0;
BA_ "NWM-WakeupAllowed" SG_ 1697 BCM1_ZV_Horn 1;
BA_ "GenSigSendType" SG_ 1697 BCM1_ZV_Horn 3;
BA_ "GenSigSwitchedByIgnition" SG_ 1697 BCM1_St_ZV 0;
BA_ "NWM-WakeupAllowed" SG_ 1697 BCM1_St_ZV 1;
BA_ "GenSigSendType" SG_ 1697 BCM1_St_ZV 3;
BA_ "GenSigSwitchedByIgnition" SG_ 1697 BCM1_FSH_aktiv 0;
BA_ "GenSigSendType" SG_ 1697 BCM1_FSH_aktiv 0;
BA_ "GenSigSwitchedByIgnition" SG_ 1697 BCM1_Kurvenlicht_li_Anf 0;
BA_ "NWM-WakeupAllowed" SG_ 1697 BCM1_Kurvenlicht_li_Anf 1;
BA_ "GenSigSendType" SG_ 1697 BCM1_Kurvenlicht_li_Anf 0;
BA_ "GenSigSwitchedByIgnition" SG_ 1697 BCM1_Kurvenlicht_re_Anf 0;
BA_ "NWM-WakeupAllowed" SG_ 1697 BCM1_Kurvenlicht_re_Anf 1;
BA_ "GenSigSendType" SG_ 1697 BCM1_Kurvenlicht_re_Anf 0;
BA_ "GenSigSwitchedByIgnition" SG_ 1697 BCM1_DWA_Anf 0;
BA_ "NWM-WakeupAllowed" SG_ 1697 BCM1_DWA_Anf 1;
BA_ "GenSigSendType" SG_ 1697 BCM1_DWA_Anf 3;
BA_ "GenSigSwitchedByIgnition" SG_ 1697 LDS_TF_Licht 0;
BA_ "NWM-WakeupAllowed" SG_ 1697 LDS_TF_Licht 1;
BA_ "GenSigSendType" SG_ 1697 LDS_TF_Licht 3;
BA_ "GenSigSwitchedByIgnition" SG_ 1697 LDS_AF_Licht 0;
BA_ "NWM-WakeupAllowed" SG_ 1697 LDS_AF_Licht 1;
BA_ "GenSigSendType" SG_ 1697 LDS_AF_Licht 3;
BA_ "GenSigSwitchedByIgnition" SG_ 1697 LDS_STA_Licht 0;
BA_ "NWM-WakeupAllowed" SG_ 1697 LDS_STA_Licht 1;
BA_ "GenSigSendType" SG_ 1697 LDS_STA_Licht 3;
BA_ "GenSigSwitchedByIgnition" SG_ 1697 LDS_Fahr_Licht 0;
BA_ "NWM-WakeupAllowed" SG_ 1697 LDS_Fahr_Licht 1;
BA_ "GenSigSendType" SG_ 1697 LDS_Fahr_Licht 3;
BA_ "GenSigSwitchedByIgnition" SG_ 1697 LDS_Error 0;
BA_ "NWM-WakeupAllowed" SG_ 1697 LDS_Error 1;
BA_ "GenSigSendType" SG_ 1697 LDS_Error 3;
BA_ "GenSigSwitchedByIgnition" SG_ 1697 LDS_N_Licht 0;
BA_ "NWM-WakeupAllowed" SG_ 1697 LDS_N_Licht 1;
BA_ "GenSigSendType" SG_ 1697 LDS_N_Licht 3;
BA_ "GenSigSwitchedByIgnition" SG_ 1697 LDS_NS_Licht 0;
BA_ "NWM-WakeupAllowed" SG_ 1697 LDS_NS_Licht 1;
BA_ "GenSigSendType" SG_ 1697 LDS_NS_Licht 3;
BA_ "GenSigSwitchedByIgnition" SG_ 1697 LDS_Nightvision 0;
BA_ "GenSigSendType" SG_ 1697 LDS_Nightvision 0;
BA_ "GenSigSwitchedByIgnition" SG_ 1697 BCM1_Geschw_PSM_erkannt 0;
BA_ "NWM-WakeupAllowed" SG_ 1697 BCM1_Geschw_PSM_erkannt 1;
BA_ "GenSigSendType" SG_ 1697 BCM1_Geschw_PSM_erkannt 0;
BA_ "GenSigSwitchedByIgnition" SG_ 1697 BCM1_Heckklappe_entriegeln 0;
BA_ "NWM-WakeupAllowed" SG_ 1697 BCM1_Heckklappe_entriegeln 1;
BA_ "GenSigSendType" SG_ 1697 BCM1_Heckklappe_entriegeln 3;
BA_ "GenSigSwitchedByIgnition" SG_ 1697 BCM1_CH_aktiv 0;
BA_ "NWM-WakeupAllowed" SG_ 1697 BCM1_CH_aktiv 1;
BA_ "GenSigSendType" SG_ 1697 BCM1_CH_aktiv 0;
BA_ "GenSigSwitchedByIgnition" SG_ 1697 BCM1_LH_aktiv 0;
BA_ "NWM-WakeupAllowed" SG_ 1697 BCM1_LH_aktiv 1;
BA_ "GenSigSendType" SG_ 1697 BCM1_LH_aktiv 0;
BA_ "GenSigSwitchedByIgnition" SG_ 1697 BCM1_Trunkentrapment_auf 0;
BA_ "NWM-WakeupAllowed" SG_ 1697 BCM1_Trunkentrapment_auf 1;
BA_ "GenSigSendType" SG_ 1697 BCM1_Trunkentrapment_auf 3;
BA_ "GenSigSwitchedByIgnition" SG_ 1697 BCM1_Trunkentrapment_zu 0;
BA_ "NWM-WakeupAllowed" SG_ 1697 BCM1_Trunkentrapment_zu 1;
BA_ "GenSigSendType" SG_ 1697 BCM1_Trunkentrapment_zu 3;
BA_ "GenSigSwitchedByIgnition" SG_ 1697 BCM1_St_Handschuhfach 0;
BA_ "NWM-WakeupAllowed" SG_ 1697 BCM1_St_Handschuhfach 1;
BA_ "GenSigSendType" SG_ 1697 BCM1_St_Handschuhfach 0;
BA_ "GenSigSwitchedByIgnition" SG_ 1697 BCM1_St_Scheinwerferdiebstahl 0;
BA_ "NWM-WakeupAllowed" SG_ 1697 BCM1_St_Scheinwerferdiebstahl 1;
BA_ "GenSigSendType" SG_ 1697 BCM1_St_Scheinwerferdiebstahl 0;
BA_ "GenSigSwitchedByIgnition" SG_ 1697 BCM1_Seitenmarker_li_def 0;
BA_ "NWM-WakeupAllowed" SG_ 1697 BCM1_Seitenmarker_li_def 1;
BA_ "GenSigSendType" SG_ 1697 BCM1_Seitenmarker_li_def 0;
BA_ "GenSigSwitchedByIgnition" SG_ 1697 BCM1_Seitenmarker_re_def 0;
BA_ "NWM-WakeupAllowed" SG_ 1697 BCM1_Seitenmarker_re_def 1;
BA_ "GenSigSendType" SG_ 1697 BCM1_Seitenmarker_re_def 0;
BA_ "GenSigSwitchedByIgnition" SG_ 1697 LS_Licht_ein 0;
BA_ "GenSigSendType" SG_ 1697 LS_Licht_ein 0;
BA_ "GenSigSwitchedByIgnition" SG_ 1697 LS_Licht_ein_invers 0;
BA_ "GenSigStartValue" SG_ 1697 LS_Licht_ein_invers 1;
BA_ "GenSigSendType" SG_ 1697 LS_Licht_ein_invers 0;
BA_ "GenSigSwitchedByIgnition" SG_ 1697 LS_Dunkel 0;
BA_ "NWM-WakeupAllowed" SG_ 1697 LS_Dunkel 1;
BA_ "GenSigSendType" SG_ 1697 LS_Dunkel 0;
BA_ "GenSigSwitchedByIgnition" SG_ 1697 BCM1_T_Verrieg_TAG 0;
BA_ "NWM-WakeupAllowed" SG_ 1697 BCM1_T_Verrieg_TAG 1;
BA_ "GenSigSendType" SG_ 1697 BCM1_T_Verrieg_TAG 3;
BA_ "GenSigSwitchedByIgnition" SG_ 1697 LS_Error 0;
BA_ "GenSigSendType" SG_ 1697 LS_Error 0;
BA_ "GenSigSwitchedByIgnition" SG_ 1697 LS_Autobahnfahrlicht 0;
BA_ "NWM-WakeupAllowed" SG_ 1697 LS_Autobahnfahrlicht 1;
BA_ "GenSigSendType" SG_ 1697 LS_Autobahnfahrlicht 0;
BA_ "GenSigSwitchedByIgnition" SG_ 1697 RS_Error 0;
BA_ "GenSigSendType" SG_ 1697 RS_Error 0;
BA_ "GenSigSwitchedByIgnition" SG_ 1697 RS_Regenfahrlicht 0;
BA_ "NWM-WakeupAllowed" SG_ 1697 RS_Regenfahrlicht 1;
BA_ "GenSigSendType" SG_ 1697 RS_Regenfahrlicht 0;
BA_ "GenSigSwitchedByIgnition" SG_ 1697 BCM1_Tankklappe_entriegeln 0;
BA_ "NWM-WakeupAllowed" SG_ 1697 BCM1_Tankklappe_entriegeln 1;
BA_ "GenSigSendType" SG_ 1697 BCM1_Tankklappe_entriegeln 3;
BA_ "GenSigSwitchedByIgnition" SG_ 1697 BCM1_Anf_AbschaltfreigabeKL15 0;
BA_ "GenSigSendType" SG_ 1697 BCM1_Anf_AbschaltfreigabeKL15 0;
BA_ "GenSigSwitchedByIgnition" SG_ 1697 BCM1_St_Timer_KL15_Abschalt 0;
BA_ "GenSigSendType" SG_ 1697 BCM1_St_Timer_KL15_Abschalt 0;
BA_ "GenSigSwitchedByIgnition" SG_ 1409 BCM_FH_Freigabe 0;
BA_ "GenSigSendType" SG_ 1409 BCM_FH_Freigabe 3;
BA_ "GenSigSwitchedByIgnition" SG_ 1409 BCM_Komfortfkt_Freigabe 0;
BA_ "GenSigSendType" SG_ 1409 BCM_Komfortfkt_Freigabe 3;
BA_ "GenSigSwitchedByIgnition" SG_ 1409 BCM_HSK_Freigabe 0;
BA_ "GenSigSendType" SG_ 1409 BCM_HSK_Freigabe 3;
BA_ "GenSigSwitchedByIgnition" SG_ 1409 BCM_Verdeck_Freigabe 0;
BA_ "GenSigSendType" SG_ 1409 BCM_Verdeck_Freigabe 3;
BA_ "GenSigSwitchedByIgnition" SG_ 1409 BCM2_Status_Timer_KL15_Abschalt 0;
BA_ "GenSigSendType" SG_ 1409 BCM2_Status_Timer_KL15_Abschalt 3;
BA_ "GenSigSendType" SG_ 1409 BCM2_Anford_AbschaltfreigabeKL15 3;
BA_ "GenSigSwitchedByIgnition" SG_ 1409 BCM2_Unterdr_Zuendungsmeldung 0;
BA_ "GenSigSendType" SG_ 1409 BCM2_Unterdr_Zuendungsmeldung 3;
BA_ "GenSigSwitchedByIgnition" SG_ 1409 BCM2_KL15_Absch_FT 0;
BA_ "GenSigSendType" SG_ 1409 BCM2_KL15_Absch_FT 3;
BA_ "GenSigSwitchedByIgnition" SG_ 1409 ZV_ist_Zustand_verfuegbar 0;
BA_ "GenSigSendType" SG_ 1409 ZV_ist_Zustand_verfuegbar 3;
BA_ "GenSigSwitchedByIgnition" SG_ 1409 BCM2_P_verriegelt 0;
BA_ "GenSigSendType" SG_ 1409 BCM2_P_verriegelt 3;
BA_ "GenSigSwitchedByIgnition" SG_ 1409 ZV_verriegelt_intern_ist 0;
BA_ "GenSigSendType" SG_ 1409 ZV_verriegelt_intern_ist 3;
BA_ "GenSigSwitchedByIgnition" SG_ 1409 ZV_verriegelt_extern_ist 0;
BA_ "GenSigSendType" SG_ 1409 ZV_verriegelt_extern_ist 3;
BA_ "GenSigSwitchedByIgnition" SG_ 1409 ZV_verriegelt_intern_soll 0;
BA_ "GenSigSendType" SG_ 1409 ZV_verriegelt_intern_soll 3;
BA_ "GenSigSwitchedByIgnition" SG_ 1409 ZV_verriegelt_extern_soll 0;
BA_ "GenSigSendType" SG_ 1409 ZV_verriegelt_extern_soll 3;
BA_ "GenSigSwitchedByIgnition" SG_ 1409 ZV_gesafet_extern_ist 0;
BA_ "GenSigSendType" SG_ 1409 ZV_gesafet_extern_ist 3;
BA_ "GenSigSwitchedByIgnition" SG_ 1409 ZV_gesafet_extern_soll 0;
BA_ "GenSigSendType" SG_ 1409 ZV_gesafet_extern_soll 3;
BA_ "GenSigSwitchedByIgnition" SG_ 1409 ZV_FT_offen 0;
BA_ "GenSigSendType" SG_ 1409 ZV_FT_offen 3;
BA_ "GenSigSwitchedByIgnition" SG_ 1409 ZV_BT_offen 0;
BA_ "GenSigSendType" SG_ 1409 ZV_BT_offen 3;
BA_ "GenSigSwitchedByIgnition" SG_ 1409 ZV_HL_offen 0;
BA_ "GenSigSendType" SG_ 1409 ZV_HL_offen 3;
BA_ "GenSigSwitchedByIgnition" SG_ 1409 ZV_HR_offen 0;
BA_ "GenSigSendType" SG_ 1409 ZV_HR_offen 3;
BA_ "GenSigSwitchedByIgnition" SG_ 1409 ZV_HD_offen 0;
BA_ "GenSigSendType" SG_ 1409 ZV_HD_offen 3;
BA_ "GenSigSwitchedByIgnition" SG_ 1409 ZV_Turen_HD_zu 0;
BA_ "GenSigSendType" SG_ 1409 ZV_Turen_HD_zu 3;
BA_ "GenSigSwitchedByIgnition" SG_ 1409 ZV_Einzeltuerentriegelung 0;
BA_ "GenSigSendType" SG_ 1409 ZV_Einzeltuerentriegelung 3;
BA_ "GenSigSwitchedByIgnition" SG_ 1409 ZV_Heckeinzelentriegelung 0;
BA_ "GenSigSendType" SG_ 1409 ZV_Heckeinzelentriegelung 3;
BA_ "GenSigSwitchedByIgnition" SG_ 1409 BCM_ValetTaster_Fkts_LED 0;
BA_ "GenSigSendType" SG_ 1409 BCM_ValetTaster_Fkts_LED 3;
BA_ "GenSigSwitchedByIgnition" SG_ 1409 BCM_HHS_aktiv 0;
BA_ "GenSigSendType" SG_ 1409 BCM_HHS_aktiv 3;
BA_ "GenSigSwitchedByIgnition" SG_ 1409 BCM_Spg_Hzg_Ein 0;
BA_ "GenSigSendType" SG_ 1409 BCM_Spg_Hzg_Ein 3;
BA_ "GenSigSwitchedByIgnition" SG_ 1409 ZV_HS_offen 0;
BA_ "GenSigSendType" SG_ 1409 ZV_HS_offen 3;
BA_ "GenSigSwitchedByIgnition" SG_ 1409 ZZH_Endlage_oben 0;
BA_ "GenSigSendType" SG_ 1409 ZZH_Endlage_oben 3;
BA_ "GenSigSwitchedByIgnition" SG_ 1409 ZZH_Endlage_unten 0;
BA_ "GenSigSendType" SG_ 1409 ZZH_Endlage_unten 3;
BA_ "GenSigSwitchedByIgnition" SG_ 1409 ZZH_Endlage_unplausibel 0;
BA_ "GenSigSendType" SG_ 1409 ZZH_Endlage_unplausibel 3;
BA_ "GenSigSwitchedByIgnition" SG_ 1409 BCM2_KD_Fehler 0;
BA_ "GenSigSendType" SG_ 1409 BCM2_KD_Fehler 3;
BA_ "GenSigSwitchedByIgnition" SG_ 1409 NGS_aktiv 0;
BA_ "GenSigSendType" SG_ 1409 NGS_aktiv 3;
BA_ "GenSigSwitchedByIgnition" SG_ 1409 IRUE_aktiv 0;
BA_ "GenSigSendType" SG_ 1409 IRUE_aktiv 3;
BA_ "GenSigSwitchedByIgnition" SG_ 1409 DWA_aktiv 0;
BA_ "GenSigSendType" SG_ 1409 DWA_aktiv 3;
BA_ "GenSigSwitchedByIgnition" SG_ 1409 Komp_Schutz_aktiv 0;
BA_ "GenSigSendType" SG_ 1409 Komp_Schutz_aktiv 3;
BA_ "GenSigSwitchedByIgnition" SG_ 1409 NGS_Taster_Fkts_LED 0;
BA_ "GenSigSendType" SG_ 1409 NGS_Taster_Fkts_LED 3;
BA_ "GenSigSwitchedByIgnition" SG_ 1409 IRUE_Taster_Fkts_LED 0;
BA_ "GenSigSendType" SG_ 1409 IRUE_Taster_Fkts_LED 3;
BA_ "GenSigSwitchedByIgnition" SG_ 1409 HD_Drehfalle_S1 0;
BA_ "GenSigSendType" SG_ 1409 HD_Drehfalle_S1 3;
BA_ "GenSigSwitchedByIgnition" SG_ 1409 HD_Sperrklinke_S2 0;
BA_ "GenSigSendType" SG_ 1409 HD_Sperrklinke_S2 3;
BA_ "GenSigSwitchedByIgnition" SG_ 1409 BCM_Verbau_Heckrollo 0;
BA_ "GenSigSendType" SG_ 1409 BCM_Verbau_Heckrollo 3;
BA_ "GenSigSwitchedByIgnition" SG_ 1409 BCM2_EZS_gedrueckt 0;
BA_ "GenSigSendType" SG_ 1409 BCM2_EZS_gedrueckt 3;
BA_ "GenSigSwitchedByIgnition" SG_ 1409 BCM2_SST_gedrueckt 0;
BA_ "GenSigSendType" SG_ 1409 BCM2_SST_gedrueckt 3;
BA_ "GenSigSwitchedByIgnition" SG_ 1409 LIM_alt 0;
BA_ "GenSigFuncType" SG_ 1409 LIM_alt 5;
BA_ "GenSigSendType" SG_ 1409 LIM_alt 3;
BA_ "GenSigSwitchedByIgnition" SG_ 1409 LIM_Innenbeleuchtung_V_aktiv 0;
BA_ "GenSigSendType" SG_ 1409 LIM_Innenbeleuchtung_V_aktiv 3;
BA_ "GenSigSwitchedByIgnition" SG_ 1409 LIM_Innenbeleuchtung_aktiv 0;
BA_ "GenSigSendType" SG_ 1409 LIM_Innenbeleuchtung_aktiv 3;
BA_ "GenSigSwitchedByIgnition" SG_ 1409 LIM_Taster_Rollolicht_hl 0;
BA_ "GenSigSendType" SG_ 1409 LIM_Taster_Rollolicht_hl 3;
BA_ "GenSigSwitchedByIgnition" SG_ 1409 LIM_Taster_Rollolicht_hr 0;
BA_ "GenSigSendType" SG_ 1409 LIM_Taster_Rollolicht_hr 3;
BA_ "GenSigSwitchedByIgnition" SG_ 1409 BCM_Sperrklinke_FT 0;
BA_ "GenSigSendType" SG_ 1409 BCM_Sperrklinke_FT 3;
BA_ "GenSigSwitchedByIgnition" SG_ 1409 LIM_Taster_Rollolicht_V 0;
BA_ "GenSigSendType" SG_ 1409 LIM_Taster_Rollolicht_V 3;
BA_ "GenSigSwitchedByIgnition" SG_ 1409 BCM_Tankwunsch 0;
BA_ "GenSigSendType" SG_ 1409 BCM_Tankwunsch 3;
BA_ "GenSigSwitchedByIgnition" SG_ 1409 ZV_Tankklappe_offen 0;
BA_ "GenSigSendType" SG_ 1409 ZV_Tankklappe_offen 3;
BA_ "GenSigSwitchedByIgnition" SG_ 1409 KST_Fahrer_Hinweise 0;
BA_ "GenSigSendType" SG_ 1409 KST_Fahrer_Hinweise 3;
BA_ "GenSigSwitchedByIgnition" SG_ 1409 KST_Warn_P1_ZST_def 0;
BA_ "GenSigSendType" SG_ 1409 KST_Warn_P1_ZST_def 3;
BA_ "GenSigSwitchedByIgnition" SG_ 1409 KST_Warn_P2_ZST_def 0;
BA_ "GenSigSendType" SG_ 1409 KST_Warn_P2_ZST_def 3;
BA_ "GenSigSwitchedByIgnition" SG_ 1409 KST_Prio_Warn_03 0;
BA_ "GenSigSendType" SG_ 1409 KST_Prio_Warn_03 3;
BA_ "GenSigSwitchedByIgnition" SG_ 1409 KST_Prio_Warn_04 0;
BA_ "GenSigSendType" SG_ 1409 KST_Prio_Warn_04 3;
BA_ "GenSigSwitchedByIgnition" SG_ 1409 KST_Prio_Warn_05 0;
BA_ "GenSigSendType" SG_ 1409 KST_Prio_Warn_05 3;
BA_ "GenSigSwitchedByIgnition" SG_ 900 BCM2_S_RF_Licht 0;
BA_ "NWM-WakeupAllowed" SG_ 900 BCM2_S_RF_Licht 1;
BA_ "GenSigSendType" SG_ 900 BCM2_S_RF_Licht 0;
BA_ "GenSigSwitchedByIgnition" SG_ 900 BCM2_ZZH_Endlage_oben 0;
BA_ "NWM-WakeupAllowed" SG_ 900 BCM2_ZZH_Endlage_oben 1;
BA_ "GenSigSendType" SG_ 900 BCM2_ZZH_Endlage_oben 0;
BA_ "GenSigSwitchedByIgnition" SG_ 900 BCM2_ZZH_Endlage_unten 0;
BA_ "NWM-WakeupAllowed" SG_ 900 BCM2_ZZH_Endlage_unten 1;
BA_ "GenSigSendType" SG_ 900 BCM2_ZZH_Endlage_unten 0;
BA_ "GenSigSwitchedByIgnition" SG_ 900 BCM2_W_VTS_Meldung 0;
BA_ "NWM-WakeupAllowed" SG_ 900 BCM2_W_VTS_Meldung 1;
BA_ "GenSigSendType" SG_ 900 BCM2_W_VTS_Meldung 3;
BA_ "GenSigSwitchedByIgnition" SG_ 900 BCM2_W_TagfahrL_re_def 0;
BA_ "NWM-WakeupAllowed" SG_ 900 BCM2_W_TagfahrL_re_def 1;
BA_ "GenSigSendType" SG_ 900 BCM2_W_TagfahrL_re_def 3;
BA_ "GenSigSwitchedByIgnition" SG_ 900 BCM2_W_TagfahrL_li_def 0;
BA_ "NWM-WakeupAllowed" SG_ 900 BCM2_W_TagfahrL_li_def 1;
BA_ "GenSigSendType" SG_ 900 BCM2_W_TagfahrL_li_def 3;
BA_ "GenSigSwitchedByIgnition" SG_ 900 BCM2_W_KurvL_re_def 0;
BA_ "NWM-WakeupAllowed" SG_ 900 BCM2_W_KurvL_re_def 1;
BA_ "GenSigSendType" SG_ 900 BCM2_W_KurvL_re_def 3;
BA_ "GenSigSwitchedByIgnition" SG_ 900 BCM2_W_KurvL_li_def 0;
BA_ "NWM-WakeupAllowed" SG_ 900 BCM2_W_KurvL_li_def 1;
BA_ "GenSigSendType" SG_ 900 BCM2_W_KurvL_li_def 3;
BA_ "GenSigSwitchedByIgnition" SG_ 900 BCM2_W_Kuehlwasserstand 0;
BA_ "NWM-WakeupAllowed" SG_ 900 BCM2_W_Kuehlwasserstand 1;
BA_ "GenSigSendType" SG_ 900 BCM2_W_Kuehlwasserstand 3;
BA_ "GenSigSwitchedByIgnition" SG_ 900 BCM2_W_HSpoiler_3 0;
BA_ "NWM-WakeupAllowed" SG_ 900 BCM2_W_HSpoiler_3 1;
BA_ "GenSigSendType" SG_ 900 BCM2_W_HSpoiler_3 3;
BA_ "GenSigSwitchedByIgnition" SG_ 900 BCM2_W_HSpoiler_4 0;
BA_ "NWM-WakeupAllowed" SG_ 900 BCM2_W_HSpoiler_4 1;
BA_ "GenSigSendType" SG_ 900 BCM2_W_HSpoiler_4 3;
BA_ "GenSigSwitchedByIgnition" SG_ 900 BCM2_W_HSpoiler_1 0;
BA_ "NWM-WakeupAllowed" SG_ 900 BCM2_W_HSpoiler_1 1;
BA_ "GenSigSendType" SG_ 900 BCM2_W_HSpoiler_1 3;
BA_ "GenSigSwitchedByIgnition" SG_ 900 BCM2_W_HSpoiler_2 0;
BA_ "NWM-WakeupAllowed" SG_ 900 BCM2_W_HSpoiler_2 1;
BA_ "GenSigSendType" SG_ 900 BCM2_W_HSpoiler_2 3;
BA_ "GenSigSwitchedByIgnition" SG_ 900 BCM2_W_Dach_n_geschl 0;
BA_ "NWM-WakeupAllowed" SG_ 900 BCM2_W_Dach_n_geschl 1;
BA_ "GenSigSendType" SG_ 900 BCM2_W_Dach_n_geschl 3;
BA_ "GenSigSwitchedByIgnition" SG_ 900 BCM2_Bremsbelag_Warn 0;
BA_ "NWM-WakeupAllowed" SG_ 900 BCM2_Bremsbelag_Warn 1;
BA_ "GenSigSendType" SG_ 900 BCM2_Bremsbelag_Warn 0;
BA_ "GenSigSwitchedByIgnition" SG_ 900 BCM2_EBD_Warnblinken_Anf 0;
BA_ "NWM-WakeupAllowed" SG_ 900 BCM2_EBD_Warnblinken_Anf 1;
BA_ "GenSigSendType" SG_ 900 BCM2_EBD_Warnblinken_Anf 0;
BA_ "GenSigSwitchedByIgnition" SG_ 900 BCM2_PassiveArming_aktiv 0;
BA_ "NWM-WakeupAllowed" SG_ 900 BCM2_PassiveArming_aktiv 1;
BA_ "GenSigSendType" SG_ 900 BCM2_PassiveArming_aktiv 3;
BA_ "GenSigMissingSourceValue" SG_ 900 DK_St_PAO_Leuchte 3;
BA_ "GenSigSwitchedByIgnition" SG_ 900 DK_St_PAO_Leuchte 0;
BA_ "NWM-WakeupAllowed" SG_ 900 DK_St_PAO_Leuchte 1;
BA_ "GenSigSendType" SG_ 900 DK_St_PAO_Leuchte 0;
BA_ "GenSigSwitchedByIgnition" SG_ 900 DK_PAO_Signalzaehler 0;
BA_ "NWM-WakeupAllowed" SG_ 900 DK_PAO_Signalzaehler 1;
BA_ "GenSigSendType" SG_ 900 DK_PAO_Signalzaehler 0;
BA_ "GenSigSwitchedByIgnition" SG_ 900 BCM2_Hauptraste_HK_aktiv 0;
BA_ "NWM-WakeupAllowed" SG_ 900 BCM2_Hauptraste_HK_aktiv 1;
BA_ "GenSigSendType" SG_ 900 BCM2_Hauptraste_HK_aktiv 0;
BA_ "GenSigSwitchedByIgnition" SG_ 900 BCM2_Vorraste_HK_aktiv 0;
BA_ "NWM-WakeupAllowed" SG_ 900 BCM2_Vorraste_HK_aktiv 1;
BA_ "GenSigSendType" SG_ 900 BCM2_Vorraste_HK_aktiv 3;
BA_ "GenSigSwitchedByIgnition" SG_ 900 BCM2_Softtouch_betaetigt 0;
BA_ "NWM-WakeupAllowed" SG_ 900 BCM2_Softtouch_betaetigt 1;
BA_ "GenSigSendType" SG_ 900 BCM2_Softtouch_betaetigt 3;
BA_ "GenSigSwitchedByIgnition" SG_ 900 BCM2_TrunkEntrapment_Anf 0;
BA_ "NWM-WakeupAllowed" SG_ 900 BCM2_TrunkEntrapment_Anf 1;
BA_ "GenSigSendType" SG_ 900 BCM2_TrunkEntrapment_Anf 0;
BA_ "GenSigSwitchedByIgnition" SG_ 900 BCM2_HsHzg_aktiv 0;
BA_ "NWM-WakeupAllowed" SG_ 900 BCM2_HsHzg_aktiv 1;
BA_ "GenSigSendType" SG_ 900 BCM2_HsHzg_aktiv 0;
BA_ "GenSigSwitchedByIgnition" SG_ 900 BCM2_St_LED_HSpoiler 0;
BA_ "NWM-WakeupAllowed" SG_ 900 BCM2_St_LED_HSpoiler 1;
BA_ "GenSigSendType" SG_ 900 BCM2_St_LED_HSpoiler 0;
BA_ "GenSigSwitchedByIgnition" SG_ 900 BCM2_DWA_aktiv 0;
BA_ "NWM-WakeupAllowed" SG_ 900 BCM2_DWA_aktiv 1;
BA_ "GenSigSendType" SG_ 900 BCM2_DWA_aktiv 0;
BA_ "GenSigSwitchedByIgnition" SG_ 900 BCM2_Alarmausgabe 0;
BA_ "NWM-WakeupAllowed" SG_ 900 BCM2_Alarmausgabe 1;
BA_ "GenSigSendType" SG_ 900 BCM2_Alarmausgabe 0;
BA_ "GenSigSwitchedByIgnition" SG_ 900 BCM2_Alarmblinken 0;
BA_ "NWM-WakeupAllowed" SG_ 900 BCM2_Alarmblinken 1;
BA_ "GenSigSendType" SG_ 900 BCM2_Alarmblinken 0;
BA_ "GenSigSwitchedByIgnition" SG_ 900 BCM2_Heckwaschen_Anf 0;
BA_ "NWM-WakeupAllowed" SG_ 900 BCM2_Heckwaschen_Anf 1;
BA_ "GenSigSendType" SG_ 900 BCM2_Heckwaschen_Anf 0;
BA_ "GenSigSwitchedByIgnition" SG_ 900 BCM2_Geschw_PSM_erkannt 0;
BA_ "NWM-WakeupAllowed" SG_ 900 BCM2_Geschw_PSM_erkannt 1;
BA_ "GenSigSendType" SG_ 900 BCM2_Geschw_PSM_erkannt 0;
BA_ "GenSigSwitchedByIgnition" SG_ 900 DK_T_Resrv 0;
BA_ "NWM-WakeupAllowed" SG_ 900 DK_T_Resrv 1;
BA_ "GenSigSendType" SG_ 900 DK_T_Resrv 3;
BA_ "GenSigMissingSourceValue" SG_ 900 DK_F_T_Resrv 1;
BA_ "GenSigSwitchedByIgnition" SG_ 900 DK_F_T_Resrv 0;
BA_ "NWM-WakeupAllowed" SG_ 900 DK_F_T_Resrv 1;
BA_ "GenSigSendType" SG_ 900 DK_F_T_Resrv 0;
BA_ "GenSigSwitchedByIgnition" SG_ 900 DK_T_PDC 0;
BA_ "NWM-WakeupAllowed" SG_ 900 DK_T_PDC 1;
BA_ "GenSigSendType" SG_ 900 DK_T_PDC 3;
BA_ "GenSigMissingSourceValue" SG_ 900 DK_F_T_PDC 1;
BA_ "GenSigSwitchedByIgnition" SG_ 900 DK_F_T_PDC 0;
BA_ "NWM-WakeupAllowed" SG_ 900 DK_F_T_PDC 1;
BA_ "GenSigSendType" SG_ 900 DK_F_T_PDC 0;
BA_ "GenSigSwitchedByIgnition" SG_ 900 BCM2_W_SpoilerInfo 0;
BA_ "GenSigSendType" SG_ 900 BCM2_W_SpoilerInfo 0;
BA_ "GenSigSwitchedByIgnition" SG_ 900 BCM2_Rollo_Bew 0;
BA_ "NWM-WakeupAllowed" SG_ 900 BCM2_Rollo_Bew 1;
BA_ "GenSigSendType" SG_ 900 BCM2_Rollo_Bew 0;
BA_ "GenSigSwitchedByIgnition" SG_ 900 BCM2_Rollo_Pos 0;
BA_ "NWM-WakeupAllowed" SG_ 900 BCM2_Rollo_Pos 1;
BA_ "GenSigSendType" SG_ 900 BCM2_Rollo_Pos 0;
BA_ "GenSigSwitchedByIgnition" SG_ 900 BCM_Handshake_STH 0;
BA_ "GenSigSendType" SG_ 900 BCM_Handshake_STH 5;
BA_ "GenSigSwitchedByIgnition" SG_ 900 BCM2_PAG_KD_Fehler 0;
BA_ "NWM-WakeupAllowed" SG_ 900 BCM2_PAG_KD_Fehler 1;
BA_ "GenSigSendType" SG_ 900 BCM2_PAG_KD_Fehler 0;
BA_ "GenSigSwitchedByIgnition" SG_ 900 BCM2_St_DCDCWandler 0;
BA_ "NWM-WakeupAllowed" SG_ 900 BCM2_St_DCDCWandler 1;
BA_ "GenSigSendType" SG_ 900 BCM2_St_DCDCWandler 0;
BA_ "GenSigSwitchedByIgnition" SG_ 900 BCM2_T_Deckel_Vorne 0;
BA_ "GenSigSendType" SG_ 900 BCM2_T_Deckel_Vorne 0;
BA_ "GenSigSwitchedByIgnition" SG_ 900 BCM1_ELV_enable_soll_2 0;
BA_ "GenSigSendType" SG_ 900 BCM1_ELV_enable_soll_2 0;
BA_ "GenSigSwitchedByIgnition" SG_ 900 BCM1_ELV_enable_Fehler_2 0;
BA_ "GenSigSendType" SG_ 900 BCM1_ELV_enable_Fehler_2 0;
BA_ "GenSigSwitchedByIgnition" SG_ 900 BCM2_IL_Dimmung 0;
BA_ "GenSigSendType" SG_ 900 BCM2_IL_Dimmung 5;
BA_ "GenSigSwitchedByIgnition" SG_ 1658 BCM2_Tankabgl_01 0;
BA_ "NWM-WakeupAllowed" SG_ 1658 BCM2_Tankabgl_01 1;
BA_ "GenSigSendType" SG_ 1658 BCM2_Tankabgl_01 0;
BA_ "GenSigSwitchedByIgnition" SG_ 1658 BCM2_Tankabgl_02 0;
BA_ "NWM-WakeupAllowed" SG_ 1658 BCM2_Tankabgl_02 1;
BA_ "GenSigSendType" SG_ 1658 BCM2_Tankabgl_02 0;
BA_ "GenSigSwitchedByIgnition" SG_ 1658 BCM2_Tankabgl_03 0;
BA_ "NWM-WakeupAllowed" SG_ 1658 BCM2_Tankabgl_03 1;
BA_ "GenSigSendType" SG_ 1658 BCM2_Tankabgl_03 0;
BA_ "GenSigSwitchedByIgnition" SG_ 1658 BCM2_Abschaltfreigabe_KL15 0;
BA_ "GenSigStartValue" SG_ 1658 BCM2_Abschaltfreigabe_KL15 1;
BA_ "GenSigSendType" SG_ 1658 BCM2_Abschaltfreigabe_KL15 0;
BA_ "GenSigSwitchedByIgnition" SG_ 1635 BEM_02_Abschaltstufen 0;
BA_ "GenSigSendType" SG_ 1635 BEM_02_Abschaltstufen 0;
BA_ "Fehlerwert" SG_ 1635 BEM_STH_Zielzeit 15;
BA_ "GenSigSwitchedByIgnition" SG_ 1635 BEM_STH_Zielzeit 0;
BA_ "GenSigStartValue" SG_ 1635 BEM_STH_Zielzeit 14;
BA_ "GenSigSendType" SG_ 1635 BEM_STH_Zielzeit 0;
BA_ "GenSigSwitchedByIgnition" SG_ 1635 BEM_MMI_Vorwarnung 0;
BA_ "GenSigSendType" SG_ 1635 BEM_MMI_Vorwarnung 0;
BA_ "GenSigSwitchedByIgnition" SG_ 1635 BEM_HL_Kontingentierung 0;
BA_ "GenSigSendType" SG_ 1635 BEM_HL_Kontingentierung 0;
BA_ "GenSigSwitchedByIgnition" SG_ 1635 NVEM_Anf_SD_schalten 0;
BA_ "GenSigSendType" SG_ 1635 NVEM_Anf_SD_schalten 0;
BA_ "GenSigSwitchedByIgnition" SG_ 1635 BEM_Generatordiagnose 0;
BA_ "GenSigSendType" SG_ 1635 BEM_Generatordiagnose 0;
BA_ "GenSigSwitchedByIgnition" SG_ 1635 BEM_Red_Innengeblaese 0;
BA_ "GenSigSendType" SG_ 1635 BEM_Red_Innengeblaese 0;
BA_ "GenSigSwitchedByIgnition" SG_ 1635 BEM_STH_Einschaltverbot 0;
BA_ "GenSigSendType" SG_ 1635 BEM_STH_Einschaltverbot 0;
BA_ "GenSigSwitchedByIgnition" SG_ 1635 BEM_HL_Regelung_Status 0;
BA_ "GenSigSendType" SG_ 1635 BEM_HL_Regelung_Status 0;
BA_ "Fehlerwert" SG_ 1635 BEM_Ladezustand 15;
BA_ "GenSigSwitchedByIgnition" SG_ 1635 BEM_Ladezustand 0;
BA_ "GenSigStartValue" SG_ 1635 BEM_Ladezustand 14;
BA_ "GenSigSendType" SG_ 1635 BEM_Ladezustand 0;
BA_ "GenSigSwitchedByIgnition" SG_ 1635 BEM_Batteriediagnose 0;
BA_ "GenSigSendType" SG_ 1635 BEM_Batteriediagnose 0;
BA_ "GenSigSwitchedByIgnition" SG_ 1635 MIB_Stromsparmodus 0;
BA_ "GenSigSendType" SG_ 1635 MIB_Stromsparmodus 0;
BA_ "GenSigSwitchedByIgnition" SG_ 1635 BEM_DFM 0;
BA_ "GenSigSendType" SG_ 1635 BEM_DFM 0;
BA_ "GenSigSwitchedByIgnition" SG_ 1635 BEM_REK_aktiv 0;
BA_ "GenSigSendType" SG_ 1635 BEM_REK_aktiv 0;
BA_ "GenSigSwitchedByIgnition" SG_ 1635 BEM_EMLIN_ungueltig 0;
BA_ "GenSigSendType" SG_ 1635 BEM_EMLIN_ungueltig 0;
BA_ "GenSigSwitchedByIgnition" SG_ 1635 BEM_Batt_Ab 0;
BA_ "GenSigSendType" SG_ 1635 BEM_Batt_Ab 0;
BA_ "Fehlerwert" SG_ 1635 BEM_UBDM 255;
BA_ "GenSigSwitchedByIgnition" SG_ 1635 BEM_UBDM 0;
BA_ "GenSigSendType" SG_ 1635 BEM_UBDM 0;
BA_ "GenSigSwitchedByIgnition" SG_ 1635 BEM_UGenSoll 0;
BA_ "GenSigSendType" SG_ 1635 BEM_UGenSoll 0;
BA_ "GenSigSwitchedByIgnition" SG_ 1635 BEM_Anf_KL15_schalten 0;
BA_ "GenSigSendType" SG_ 1635 BEM_Anf_KL15_schalten 0;
BA_ "GenSigSwitchedByIgnition" SG_ 1326 BEM_blDeaktivierungStandhzgAnz 0;
BA_ "NWM-WakeupAllowed" SG_ 1326 BEM_blDeaktivierungStandhzgAnz 1;
BA_ "GenSigSendType" SG_ 1326 BEM_blDeaktivierungStandhzgAnz 0;
BA_ "GenSigSwitchedByIgnition" SG_ 1326 BEM_blAbschaltungSteckdAnz 0;
BA_ "NWM-WakeupAllowed" SG_ 1326 BEM_blAbschaltungSteckdAnz 1;
BA_ "GenSigSendType" SG_ 1326 BEM_blAbschaltungSteckdAnz 0;
BA_ "GenSigSwitchedByIgnition" SG_ 1326 BEM_blReduzInnenGeblaeseAnz 0;
BA_ "NWM-WakeupAllowed" SG_ 1326 BEM_blReduzInnenGeblaeseAnz 1;
BA_ "GenSigSendType" SG_ 1326 BEM_blReduzInnenGeblaeseAnz 0;
BA_ "GenSigSwitchedByIgnition" SG_ 1326 BEM_blMmiVorwarnungBus 0;
BA_ "NWM-WakeupAllowed" SG_ 1326 BEM_blMmiVorwarnungBus 1;
BA_ "GenSigSendType" SG_ 1326 BEM_blMmiVorwarnungBus 0;
BA_ "GenSigSwitchedByIgnition" SG_ 1326 BEM_blKl30Transport 0;
BA_ "NWM-WakeupAllowed" SG_ 1326 BEM_blKl30Transport 1;
BA_ "GenSigSendType" SG_ 1326 BEM_blKl30Transport 0;
BA_ "GenSigSwitchedByIgnition" SG_ 1326 BEM_blKlemmeG1 0;
BA_ "NWM-WakeupAllowed" SG_ 1326 BEM_blKlemmeG1 1;
BA_ "GenSigSendType" SG_ 1326 BEM_blKlemmeG1 0;
BA_ "GenSigSwitchedByIgnition" SG_ 1326 BEM_blKlemmeG2 0;
BA_ "NWM-WakeupAllowed" SG_ 1326 BEM_blKlemmeG2 1;
BA_ "GenSigSendType" SG_ 1326 BEM_blKlemmeG2 0;
BA_ "GenSigSwitchedByIgnition" SG_ 1326 BEM_blKl30fAusAnzeige 0;
BA_ "NWM-WakeupAllowed" SG_ 1326 BEM_blKl30fAusAnzeige 1;
BA_ "GenSigSendType" SG_ 1326 BEM_blKl30fAusAnzeige 0;
BA_ "GenSigSwitchedByIgnition" SG_ 1326 BEM_valKl30fCountdown 0;
BA_ "NWM-WakeupAllowed" SG_ 1326 BEM_valKl30fCountdown 1;
BA_ "GenSigSendType" SG_ 1326 BEM_valKl30fCountdown 0;
BA_ "GenSigSwitchedByIgnition" SG_ 1326 BEM_Kl15ausAnfProduktion 0;
BA_ "NWM-WakeupAllowed" SG_ 1326 BEM_Kl15ausAnfProduktion 1;
BA_ "GenSigSendType" SG_ 1326 BEM_Kl15ausAnfProduktion 0;
BA_ "GenSigSwitchedByIgnition" SG_ 867 BM_ZV_auf 0;
BA_ "GenSigSendType" SG_ 867 BM_ZV_auf 6;
BA_ "GenSigActiveRepetitions" SG_ 867 BM_ZV_auf 5;
BA_ "GenSigSwitchedByIgnition" SG_ 867 BM_ZV_zu 0;
BA_ "GenSigSendType" SG_ 867 BM_ZV_zu 6;
BA_ "GenSigActiveRepetitions" SG_ 867 BM_ZV_zu 5;
BA_ "GenSigSwitchedByIgnition" SG_ 867 BM_DWA_ein 0;
BA_ "GenSigSendType" SG_ 867 BM_DWA_ein 6;
BA_ "GenSigActiveRepetitions" SG_ 867 BM_DWA_ein 5;
BA_ "GenSigSwitchedByIgnition" SG_ 867 BM_DWA_Alarm 0;
BA_ "GenSigSendType" SG_ 867 BM_DWA_Alarm 6;
BA_ "GenSigActiveRepetitions" SG_ 867 BM_DWA_Alarm 5;
BA_ "GenSigSwitchedByIgnition" SG_ 867 BM_Crash 0;
BA_ "GenSigSendType" SG_ 867 BM_Crash 6;
BA_ "GenSigActiveRepetitions" SG_ 867 BM_Crash 5;
BA_ "GenSigSwitchedByIgnition" SG_ 867 BM_Panik 0;
BA_ "GenSigSendType" SG_ 867 BM_Panik 6;
BA_ "GenSigActiveRepetitions" SG_ 867 BM_Panik 5;
BA_ "GenSigSwitchedByIgnition" SG_ 867 BM_Not_Bremsung 0;
BA_ "GenSigSendType" SG_ 867 BM_Not_Bremsung 6;
BA_ "GenSigActiveRepetitions" SG_ 867 BM_Not_Bremsung 5;
BA_ "GenSigSwitchedByIgnition" SG_ 867 BM_GDO 0;
BA_ "GenSigSendType" SG_ 867 BM_GDO 6;
BA_ "GenSigActiveRepetitions" SG_ 867 BM_GDO 5;
BA_ "GenSigSwitchedByIgnition" SG_ 867 BM_links 0;
BA_ "GenSigSendType" SG_ 867 BM_links 6;
BA_ "GenSigActiveRepetitions" SG_ 867 BM_links 5;
BA_ "GenSigSwitchedByIgnition" SG_ 867 BM_rechts 0;
BA_ "GenSigSendType" SG_ 867 BM_rechts 6;
BA_ "GenSigActiveRepetitions" SG_ 867 BM_rechts 5;
BA_ "GenSigSwitchedByIgnition" SG_ 867 BM_Warnblinken 0;
BA_ "GenSigSendType" SG_ 867 BM_Warnblinken 6;
BA_ "GenSigActiveRepetitions" SG_ 867 BM_Warnblinken 5;
BA_ "GenSigSwitchedByIgnition" SG_ 867 BM_Autobahn 0;
BA_ "GenSigSendType" SG_ 867 BM_Autobahn 6;
BA_ "GenSigActiveRepetitions" SG_ 867 BM_Autobahn 5;
BA_ "GenSigSwitchedByIgnition" SG_ 867 BM_Taxi_Notalarm 0;
BA_ "GenSigSendType" SG_ 867 BM_Taxi_Notalarm 6;
BA_ "GenSigActiveRepetitions" SG_ 867 BM_Taxi_Notalarm 5;
BA_ "GenSigSwitchedByIgnition" SG_ 867 BM_Telematik 0;
BA_ "GenSigSendType" SG_ 867 BM_Telematik 6;
BA_ "GenSigActiveRepetitions" SG_ 867 BM_Telematik 5;
BA_ "GenSigSwitchedByIgnition" SG_ 867 BM_HD_Oeffnung_angelernt 0;
BA_ "GenSigSendType" SG_ 867 BM_HD_Oeffnung_angelernt 6;
BA_ "GenSigActiveRepetitions" SG_ 867 BM_HD_Oeffnung_angelernt 5;
BA_ "GenSigSwitchedByIgnition" SG_ 867 BM_WBT_Beleuchtung 0;
BA_ "GenSigSendType" SG_ 867 BM_WBT_Beleuchtung 6;
BA_ "GenSigActiveRepetitions" SG_ 867 BM_WBT_Beleuchtung 5;
BA_ "GenSigSwitchedByIgnition" SG_ 867 Blinken_li_Fzg_Takt 0;
BA_ "GenSigSendType" SG_ 867 Blinken_li_Fzg_Takt 6;
BA_ "GenSigActiveRepetitions" SG_ 867 Blinken_li_Fzg_Takt 5;
BA_ "GenSigSwitchedByIgnition" SG_ 867 Blinken_re_Fzg_Takt 0;
BA_ "GenSigSendType" SG_ 867 Blinken_re_Fzg_Takt 6;
BA_ "GenSigActiveRepetitions" SG_ 867 Blinken_re_Fzg_Takt 5;
BA_ "GenSigSwitchedByIgnition" SG_ 867 Blinken_li_Kombi_Takt 0;
BA_ "GenSigSendType" SG_ 867 Blinken_li_Kombi_Takt 6;
BA_ "GenSigActiveRepetitions" SG_ 867 Blinken_li_Kombi_Takt 5;
BA_ "GenSigSwitchedByIgnition" SG_ 867 Blinken_re_Kombi_Takt 0;
BA_ "GenSigSendType" SG_ 867 Blinken_re_Kombi_Takt 6;
BA_ "GenSigActiveRepetitions" SG_ 867 Blinken_re_Kombi_Takt 5;
BA_ "GenSigSwitchedByIgnition" SG_ 867 BM_NBA_n_codiert_n_aktiv 0;
BA_ "GenSigStartValue" SG_ 867 BM_NBA_n_codiert_n_aktiv 1;
BA_ "GenSigSendType" SG_ 867 BM_NBA_n_codiert_n_aktiv 5;
BA_ "GenSigSwitchedByIgnition" SG_ 867 BM_NBA_Status 0;
BA_ "GenSigSendType" SG_ 867 BM_NBA_Status 5;
BA_ "GenSigSwitchedByIgnition" SG_ 867 Blinken_FWB_aktiv 0;
BA_ "GenSigSendType" SG_ 867 Blinken_FWB_aktiv 6;
BA_ "GenSigActiveRepetitions" SG_ 867 Blinken_FWB_aktiv 5;
BA_ "GenSigSwitchedByIgnition" SG_ 687 BMS_Rekuperation 0;
BA_ "GenSigSendType" SG_ 687 BMS_Rekuperation 0;
BA_ "GenSigSwitchedByIgnition" SG_ 687 BMS_Rekuperation_Ueberlauf 0;
BA_ "GenSigSendType" SG_ 687 BMS_Rekuperation_Ueberlauf 0;
BA_ "GenSigSwitchedByIgnition" SG_ 687 BMS_Verbrauch 0;
BA_ "GenSigSendType" SG_ 687 BMS_Verbrauch 0;
BA_ "GenSigSwitchedByIgnition" SG_ 687 BMS_Verbrauch_Ueberlauf 0;
BA_ "GenSigSendType" SG_ 687 BMS_Verbrauch_Ueberlauf 0;
BA_ "GenSigSwitchedByIgnition" SG_ 1438 BMS_Temperierung_Anf 0;
BA_ "GenSigStartValue" SG_ 1438 BMS_Temperierung_Anf 3;
BA_ "GenSigSendType" SG_ 1438 BMS_Temperierung_Anf 0;
BA_ "GenSigSwitchedByIgnition" SG_ 1438 BMS_Soll_PWM_Pumpe 0;
BA_ "GenSigStartValue" SG_ 1438 BMS_Soll_PWM_Pumpe 15;
BA_ "GenSigSendType" SG_ 1438 BMS_Soll_PWM_Pumpe 0;
BA_ "Fehlerwert" SG_ 1438 BMS_Temperatur 255;
BA_ "GenSigSwitchedByIgnition" SG_ 1438 BMS_Temperatur 0;
BA_ "GenSigStartValue" SG_ 1438 BMS_Temperatur 254;
BA_ "GenSigSendType" SG_ 1438 BMS_Temperatur 0;
BA_ "Fehlerwert" SG_ 1438 BMS_IstVorlaufTemperatur 255;
BA_ "GenSigSwitchedByIgnition" SG_ 1438 BMS_IstVorlaufTemperatur 0;
BA_ "GenSigStartValue" SG_ 1438 BMS_IstVorlaufTemperatur 254;
BA_ "GenSigSendType" SG_ 1438 BMS_IstVorlaufTemperatur 0;
BA_ "GenSigSwitchedByIgnition" SG_ 1438 BMS_SollVorlaufTemp_Epsilon 0;
BA_ "GenSigStartValue" SG_ 1438 BMS_SollVorlaufTemp_Epsilon 15;
BA_ "GenSigSendType" SG_ 1438 BMS_SollVorlaufTemp_Epsilon 0;
BA_ "Fehlerwert" SG_ 1438 BMS_SollVolumenstrom 63;
BA_ "GenSigSwitchedByIgnition" SG_ 1438 BMS_SollVolumenstrom 0;
BA_ "GenSigStartValue" SG_ 1438 BMS_SollVolumenstrom 62;
BA_ "GenSigSendType" SG_ 1438 BMS_SollVolumenstrom 0;
BA_ "Fehlerwert" SG_ 1438 BMS_SollVorlauftemperatur 255;
BA_ "GenSigSwitchedByIgnition" SG_ 1438 BMS_SollVorlauftemperatur 0;
BA_ "GenSigStartValue" SG_ 1438 BMS_SollVorlauftemperatur 254;
BA_ "GenSigSendType" SG_ 1438 BMS_SollVorlauftemperatur 0;
BA_ "Fehlerwert" SG_ 1438 BMS_IstRuecklaufTemperatur_02 255;
BA_ "GenSigSwitchedByIgnition" SG_ 1438 BMS_IstRuecklaufTemperatur_02 0;
BA_ "GenSigStartValue" SG_ 1438 BMS_IstRuecklaufTemperatur_02 254;
BA_ "GenSigSendType" SG_ 1438 BMS_IstRuecklaufTemperatur_02 0;
BA_ "GenSigSwitchedByIgnition" SG_ 1482 BMS_07_CRC 0;
BA_ "GenSigFuncType" SG_ 1482 BMS_07_CRC 2;
BA_ "GenSigSendType" SG_ 1482 BMS_07_CRC 0;
BA_ "GenSigSwitchedByIgnition" SG_ 1482 BMS_07_BZ 0;
BA_ "GenSigFuncType" SG_ 1482 BMS_07_BZ 1;
BA_ "GenSigSendType" SG_ 1482 BMS_07_BZ 0;
BA_ "Fehlerwert" SG_ 1482 BMS_Energieinhalt 2047;
BA_ "GenSigSwitchedByIgnition" SG_ 1482 BMS_Energieinhalt 0;
BA_ "GenSigStartValue" SG_ 1482 BMS_Energieinhalt 2046;
BA_ "GenSigSendType" SG_ 1482 BMS_Energieinhalt 0;
BA_ "GenSigSwitchedByIgnition" SG_ 1482 BMS_Ladevorgang_aktiv 0;
BA_ "GenSigSendType" SG_ 1482 BMS_Ladevorgang_aktiv 0;
BA_ "Fehlerwert" SG_ 1482 BMS_MaxEnergieinhalt 2047;
BA_ "GenSigSwitchedByIgnition" SG_ 1482 BMS_MaxEnergieinhalt 0;
BA_ "GenSigStartValue" SG_ 1482 BMS_MaxEnergieinhalt 2046;
BA_ "GenSigSendType" SG_ 1482 BMS_MaxEnergieinhalt 0;
BA_ "GenSigSwitchedByIgnition" SG_ 1482 BMS_Ausgleichsladung_Anf 0;
BA_ "GenSigSendType" SG_ 1482 BMS_Ausgleichsladung_Anf 0;
BA_ "GenSigSwitchedByIgnition" SG_ 1482 BMS_Gesamtst_Spgfreiheit 0;
BA_ "GenSigSendType" SG_ 1482 BMS_Gesamtst_Spgfreiheit 3;
BA_ "Fehlerwert" SG_ 1519 BMS_IstStrom 4095;
BA_ "GenSigSwitchedByIgnition" SG_ 1519 BMS_IstStrom 0;
BA_ "GenSigStartValue" SG_ 1519 BMS_IstStrom 4094;
BA_ "GenSigSendType" SG_ 1519 BMS_IstStrom 0;
BA_ "Fehlerwert" SG_ 1519 BMS_Status_Kuehlung 15;
BA_ "GenSigSwitchedByIgnition" SG_ 1519 BMS_Status_Kuehlung 0;
BA_ "GenSigStartValue" SG_ 1519 BMS_Status_Kuehlung 14;
BA_ "GenSigSendType" SG_ 1519 BMS_Status_Kuehlung 0;
BA_ "Fehlerwert" SG_ 1519 BMS_Temp_Zelle_Min 255;
BA_ "GenSigSwitchedByIgnition" SG_ 1519 BMS_Temp_Zelle_Min 0;
BA_ "GenSigStartValue" SG_ 1519 BMS_Temp_Zelle_Min 254;
BA_ "GenSigSendType" SG_ 1519 BMS_Temp_Zelle_Min 0;
BA_ "Fehlerwert" SG_ 1519 BMS_Temp_Zelle_Max 255;
BA_ "GenSigSwitchedByIgnition" SG_ 1519 BMS_Temp_Zelle_Max 0;
BA_ "GenSigStartValue" SG_ 1519 BMS_Temp_Zelle_Max 254;
BA_ "GenSigSendType" SG_ 1519 BMS_Temp_Zelle_Max 0;
BA_ "Fehlerwert" SG_ 1519 BMS_Pumpendrehzahl 255;
BA_ "GenSigSwitchedByIgnition" SG_ 1519 BMS_Pumpendrehzahl 0;
BA_ "GenSigStartValue" SG_ 1519 BMS_Pumpendrehzahl 254;
BA_ "GenSigSendType" SG_ 1519 BMS_Pumpendrehzahl 0;
BA_ "Fehlerwert" SG_ 1519 BMS_Status_3_2_Ventil1 7;
BA_ "GenSigSwitchedByIgnition" SG_ 1519 BMS_Status_3_2_Ventil1 0;
BA_ "GenSigStartValue" SG_ 1519 BMS_Status_3_2_Ventil1 6;
BA_ "GenSigSendType" SG_ 1519 BMS_Status_3_2_Ventil1 0;
BA_ "Fehlerwert" SG_ 1519 BMS_Status_3_2_Ventil2 7;
BA_ "GenSigSwitchedByIgnition" SG_ 1519 BMS_Status_3_2_Ventil2 0;
BA_ "GenSigStartValue" SG_ 1519 BMS_Status_3_2_Ventil2 6;
BA_ "GenSigSendType" SG_ 1519 BMS_Status_3_2_Ventil2 0;
BA_ "Fehlerwert" SG_ 1519 BMS_PTC_IstStrom 255;
BA_ "GenSigSwitchedByIgnition" SG_ 1519 BMS_PTC_IstStrom 0;
BA_ "GenSigStartValue" SG_ 1519 BMS_PTC_IstStrom 254;
BA_ "GenSigSendType" SG_ 1519 BMS_PTC_IstStrom 0;
BA_ "Fehlerwert" SG_ 1519 BMS_PTC_Stufe 15;
BA_ "GenSigSwitchedByIgnition" SG_ 1519 BMS_PTC_Stufe 0;
BA_ "GenSigStartValue" SG_ 1519 BMS_PTC_Stufe 14;
BA_ "GenSigSendType" SG_ 1519 BMS_PTC_Stufe 0;
BA_ "GenSigSendType" SG_ 1628 BMS_HYB_ASV_hinten_Status 0;
BA_ "GenSigSendType" SG_ 1628 BMS_HYB_ASV_vorne_Status 0;
BA_ "GenSigSwitchedByIgnition" SG_ 1628 BMS_HYB_KD_Fehler 0;
BA_ "GenSigSendType" SG_ 1628 BMS_HYB_KD_Fehler 0;
BA_ "Fehlerwert" SG_ 1628 BMS_HYB_BattFanSpd 15;
BA_ "GenSigStartValue" SG_ 1628 BMS_HYB_BattFanSpd 14;
BA_ "GenSigSendType" SG_ 1628 BMS_HYB_BattFanSpd 0;
BA_ "GenSigSendType" SG_ 1628 BMS_HYB_VentilationReq 0;
BA_ "GenSigSendType" SG_ 1628 BMS_HYB_Spuelbetrieb_Status 0;
BA_ "GenSigSendType" SG_ 1628 BMS_HYB_Kuehlung_Anf 0;
BA_ "Fehlerwert" SG_ 1628 BMS_HYB_Temp_vor_Verd 255;
BA_ "GenSigStartValue" SG_ 1628 BMS_HYB_Temp_vor_Verd 254;
BA_ "GenSigSendType" SG_ 1628 BMS_HYB_Temp_vor_Verd 0;
BA_ "Fehlerwert" SG_ 1628 BMS_HYB_Temp_nach_Verd 255;
BA_ "GenSigStartValue" SG_ 1628 BMS_HYB_Temp_nach_Verd 254;
BA_ "GenSigSendType" SG_ 1628 BMS_HYB_Temp_nach_Verd 0;
BA_ "Fehlerwert" SG_ 1628 BMS_Temperatur 255;
BA_ "GenSigSwitchedByIgnition" SG_ 1628 BMS_Temperatur 0;
BA_ "GenSigStartValue" SG_ 1628 BMS_Temperatur 254;
BA_ "GenSigSendType" SG_ 1628 BMS_Temperatur 0;
BA_ "Fehlerwert" SG_ 1628 BMS_Temperatur_Ansaugluft 255;
BA_ "GenSigSwitchedByIgnition" SG_ 1628 BMS_Temperatur_Ansaugluft 0;
BA_ "GenSigStartValue" SG_ 1628 BMS_Temperatur_Ansaugluft 254;
BA_ "GenSigSendType" SG_ 1628 BMS_Temperatur_Ansaugluft 0;
BA_ "Fehlerwert" SG_ 1628 BMS_IstSpannung_HV 255;
BA_ "GenSigSwitchedByIgnition" SG_ 1628 BMS_IstSpannung_HV 0;
BA_ "GenSigStartValue" SG_ 1628 BMS_IstSpannung_HV 254;
BA_ "GenSigSendType" SG_ 1628 BMS_IstSpannung_HV 0;
BA_ "GenSigSwitchedByIgnition" SG_ 903 Bremse_EV_02_CRC 0;
BA_ "GenSigFuncType" SG_ 903 Bremse_EV_02_CRC 2;
BA_ "GenSigSendType" SG_ 903 Bremse_EV_02_CRC 0;
BA_ "GenSigSwitchedByIgnition" SG_ 903 Bremse_EV_02_BZ 0;
BA_ "GenSigFuncType" SG_ 903 Bremse_EV_02_BZ 1;
BA_ "GenSigSendType" SG_ 903 Bremse_EV_02_BZ 0;
BA_ "GenSigSwitchedByIgnition" SG_ 903 EBKV_OBD_Status 0;
BA_ "GenSigSendType" SG_ 903 EBKV_OBD_Status 0;
BA_ "GenSigSwitchedByIgnition" SG_ 903 EBKV_Hinweise 0;
BA_ "GenSigSendType" SG_ 903 EBKV_Hinweise 0;
BA_ "GenSigSwitchedByIgnition" SG_ 903 EBKV_Warnungen 0;
BA_ "GenSigSendType" SG_ 903 EBKV_Warnungen 0;
BA_ "GenSigSwitchedByIgnition" SG_ 903 EBKV_BKL_Warnungen 0;
BA_ "GenSigSendType" SG_ 903 EBKV_BKL_Warnungen 0;
BA_ "GenSigSwitchedByIgnition" SG_ 901 CHA_01_CHK 0;
BA_ "GenSigFuncType" SG_ 901 CHA_01_CHK 3;
BA_ "GenSigSwitchedByIgnition" SG_ 901 CHA_01_BZ 0;
BA_ "GenSigSwitchedByIgnition" SG_ 901 CHA_Systemstatus 0;
BA_ "GenSigSendType" SG_ 901 CHA_Systemstatus 2;
BA_ "GenSigActiveRepetitions" SG_ 901 CHA_Systemstatus 5;
BA_ "GenSigSendType" SG_ 901 CHA_Fahrer_Umschaltung 2;
BA_ "GenSigActiveRepetitions" SG_ 901 CHA_Fahrer_Umschaltung 5;
BA_ "GenSigSwitchedByIgnition" SG_ 901 CHA_Ziel_FahrPr_MO 0;
BA_ "GenSigSendType" SG_ 901 CHA_Ziel_FahrPr_MO 2;
BA_ "GenSigActiveRepetitions" SG_ 901 CHA_Ziel_FahrPr_MO 5;
BA_ "GenSigSwitchedByIgnition" SG_ 901 CHA_Ziel_FahrPr_GE 0;
BA_ "GenSigSendType" SG_ 901 CHA_Ziel_FahrPr_GE 2;
BA_ "GenSigActiveRepetitions" SG_ 901 CHA_Ziel_FahrPr_GE 5;
BA_ "GenSigSwitchedByIgnition" SG_ 901 CHA_Ziel_FahrPr_ST 0;
BA_ "GenSigSendType" SG_ 901 CHA_Ziel_FahrPr_ST 2;
BA_ "GenSigActiveRepetitions" SG_ 901 CHA_Ziel_FahrPr_ST 5;
BA_ "GenSigSwitchedByIgnition" SG_ 901 CHA_Ziel_FahrPr_SCU 0;
BA_ "GenSigSendType" SG_ 901 CHA_Ziel_FahrPr_SCU 2;
BA_ "GenSigActiveRepetitions" SG_ 901 CHA_Ziel_FahrPr_SCU 5;
BA_ "GenSigSwitchedByIgnition" SG_ 901 CHA_Ziel_FahrPr_DR 0;
BA_ "GenSigSendType" SG_ 901 CHA_Ziel_FahrPr_DR 2;
BA_ "GenSigActiveRepetitions" SG_ 901 CHA_Ziel_FahrPr_DR 5;
BA_ "GenSigSwitchedByIgnition" SG_ 901 CHA_Ziel_FahrPr_QS 0;
BA_ "GenSigSendType" SG_ 901 CHA_Ziel_FahrPr_QS 2;
BA_ "GenSigActiveRepetitions" SG_ 901 CHA_Ziel_FahrPr_QS 5;
BA_ "GenSigSwitchedByIgnition" SG_ 901 CHA_Ziel_FahrPr_AFS 0;
BA_ "GenSigSendType" SG_ 901 CHA_Ziel_FahrPr_AFS 2;
BA_ "GenSigActiveRepetitions" SG_ 901 CHA_Ziel_FahrPr_AFS 5;
BA_ "GenSigSwitchedByIgnition" SG_ 901 CHA_Ziel_FahrPr_RGS 0;
BA_ "GenSigSendType" SG_ 901 CHA_Ziel_FahrPr_RGS 2;
BA_ "GenSigActiveRepetitions" SG_ 901 CHA_Ziel_FahrPr_RGS 5;
BA_ "GenSigSwitchedByIgnition" SG_ 901 CHA_Ziel_FahrPr_EPS 0;
BA_ "GenSigSendType" SG_ 901 CHA_Ziel_FahrPr_EPS 2;
BA_ "GenSigActiveRepetitions" SG_ 901 CHA_Ziel_FahrPr_EPS 5;
BA_ "GenSigSwitchedByIgnition" SG_ 901 CHA_Ziel_FahrPr_ACC 0;
BA_ "GenSigSendType" SG_ 901 CHA_Ziel_FahrPr_ACC 2;
BA_ "GenSigActiveRepetitions" SG_ 901 CHA_Ziel_FahrPr_ACC 5;
BA_ "GenSigSwitchedByIgnition" SG_ 901 CHA_Ziel_FahrPr_SAK 0;
BA_ "GenSigSendType" SG_ 901 CHA_Ziel_FahrPr_SAK 2;
BA_ "GenSigActiveRepetitions" SG_ 901 CHA_Ziel_FahrPr_SAK 5;
BA_ "GenSigSwitchedByIgnition" SG_ 1336 MO_Charisma_FahrPr 0;
BA_ "GenSigSendType" SG_ 1336 MO_Charisma_FahrPr 3;
BA_ "GenSigSwitchedByIgnition" SG_ 1336 MO_Charisma_Status 0;
BA_ "GenSigSendType" SG_ 1336 MO_Charisma_Status 0;
BA_ "GenSigSwitchedByIgnition" SG_ 1336 MO_Charisma_Umschaltung 0;
BA_ "GenSigSendType" SG_ 1336 MO_Charisma_Umschaltung 3;
BA_ "GenSigSwitchedByIgnition" SG_ 1336 Motor_05_alt 0;
BA_ "GenSigFuncType" SG_ 1336 Motor_05_alt 5;
BA_ "GenSigStartValue" SG_ 1336 Motor_05_alt 1;
BA_ "GenSigSendType" SG_ 1336 Motor_05_alt 0;
BA_ "GenSigSwitchedByIgnition" SG_ 1336 GE_Charisma_FahrPr 0;
BA_ "GenSigSendType" SG_ 1336 GE_Charisma_FahrPr 3;
BA_ "GenSigSwitchedByIgnition" SG_ 1336 GE_Charisma_Status 0;
BA_ "GenSigSendType" SG_ 1336 GE_Charisma_Status 0;
BA_ "GenSigSwitchedByIgnition" SG_ 1336 GE_Charisma_Umschaltung 0;
BA_ "GenSigSendType" SG_ 1336 GE_Charisma_Umschaltung 3;
BA_ "GenSigSwitchedByIgnition" SG_ 1336 Getriebe_04_alt 0;
BA_ "GenSigFuncType" SG_ 1336 Getriebe_04_alt 5;
BA_ "GenSigStartValue" SG_ 1336 Getriebe_04_alt 1;
BA_ "GenSigSendType" SG_ 1336 Getriebe_04_alt 0;
BA_ "GenSigSendType" SG_ 1336 SCU_Charisma_FahrPr 0;
BA_ "GenSigSendType" SG_ 1336 SCU_Charisma_Status 0;
BA_ "GenSigSendType" SG_ 1336 SCU_Charisma_Umschaltung 0;
BA_ "GenSigFuncType" SG_ 1336 SCU_02_alt 5;
BA_ "GenSigStartValue" SG_ 1336 SCU_02_alt 1;
BA_ "GenSigSendType" SG_ 1336 SCU_02_alt 0;
BA_ "GenSigSwitchedByIgnition" SG_ 1336 ST_Charisma_FahrPr 0;
BA_ "GenSigSendType" SG_ 1336 ST_Charisma_FahrPr 3;
BA_ "GenSigSwitchedByIgnition" SG_ 1336 ST_Charisma_Status 0;
BA_ "GenSigSendType" SG_ 1336 ST_Charisma_Status 0;
BA_ "GenSigSwitchedByIgnition" SG_ 1336 ST_Charisma_Umschaltung 0;
BA_ "GenSigSendType" SG_ 1336 ST_Charisma_Umschaltung 3;
BA_ "GenSigSwitchedByIgnition" SG_ 1336 BCM1_01_alt 0;
BA_ "GenSigFuncType" SG_ 1336 BCM1_01_alt 5;
BA_ "GenSigStartValue" SG_ 1336 BCM1_01_alt 1;
BA_ "GenSigSendType" SG_ 1336 BCM1_01_alt 0;
BA_ "GenSigSendType" SG_ 1336 DR_Charisma_FahrPr 3;
BA_ "GenSigSendType" SG_ 1336 DR_Charisma_Status 0;
BA_ "GenSigSendType" SG_ 1336 DR_Charisma_Umschaltung 3;
BA_ "GenSigSwitchedByIgnition" SG_ 1336 Daempfer_01_alt 0;
BA_ "GenSigFuncType" SG_ 1336 Daempfer_01_alt 5;
BA_ "GenSigStartValue" SG_ 1336 Daempfer_01_alt 1;
BA_ "GenSigSendType" SG_ 1336 Daempfer_01_alt 0;
BA_ "GenSigSendType" SG_ 1336 QSP_Charisma_FahrPr 0;
BA_ "GenSigSendType" SG_ 1336 QSP_Charisma_Status 0;
BA_ "GenSigSendType" SG_ 1336 QSP_Charisma_Umschaltung 0;
BA_ "GenSigFuncType" SG_ 1336 QSP_01_alt 5;
BA_ "GenSigStartValue" SG_ 1336 QSP_01_alt 1;
BA_ "GenSigSendType" SG_ 1336 QSP_01_alt 0;
BA_ "GenSigSendType" SG_ 1336 RGS_VL_Charisma_FahrPr 0;
BA_ "GenSigSendType" SG_ 1336 RGS_VL_Charisma_Status 0;
BA_ "GenSigSendType" SG_ 1336 RGS_VL_Charisma_Umschaltung 0;
BA_ "GenSigFuncType" SG_ 1336 RGS_VL_01_alt 5;
BA_ "GenSigStartValue" SG_ 1336 RGS_VL_01_alt 1;
BA_ "GenSigSendType" SG_ 1336 RGS_VL_01_alt 0;
BA_ "GenSigSendType" SG_ 1336 AFS_Charisma_FahrPr 3;
BA_ "GenSigSendType" SG_ 1336 AFS_Charisma_Status 0;
BA_ "GenSigSendType" SG_ 1336 AFS_Charisma_Umschaltung 3;
BA_ "GenSigFuncType" SG_ 1336 AFS_01_alt 5;
BA_ "GenSigStartValue" SG_ 1336 AFS_01_alt 1;
BA_ "GenSigSendType" SG_ 1336 AFS_01_alt 0;
BA_ "GenSigSwitchedByIgnition" SG_ 1338 EPS_Charisma_FahrPr 0;
BA_ "GenSigSendType" SG_ 1338 EPS_Charisma_FahrPr 3;
BA_ "GenSigSwitchedByIgnition" SG_ 1338 EPS_Charisma_Status 0;
BA_ "GenSigSendType" SG_ 1338 EPS_Charisma_Status 0;
BA_ "GenSigSwitchedByIgnition" SG_ 1338 EPS_Charisma_Umschaltung 0;
BA_ "GenSigSendType" SG_ 1338 EPS_Charisma_Umschaltung 3;
BA_ "GenSigSwitchedByIgnition" SG_ 1338 EPS_FR_alt 0;
BA_ "GenSigFuncType" SG_ 1338 EPS_FR_alt 5;
BA_ "GenSigStartValue" SG_ 1338 EPS_FR_alt 1;
BA_ "GenSigSendType" SG_ 1338 EPS_FR_alt 0;
BA_ "GenSigSendType" SG_ 1338 ACC_Charisma_FahrPr 3;
BA_ "GenSigSendType" SG_ 1338 ACC_Charisma_Status 0;
BA_ "GenSigSendType" SG_ 1338 ACC_Charisma_Umschaltung 3;
BA_ "GenSigFuncType" SG_ 1338 ACC_04_alt 5;
BA_ "GenSigStartValue" SG_ 1338 ACC_04_alt 1;
BA_ "GenSigSendType" SG_ 1338 ACC_04_alt 0;
BA_ "GenSigSendType" SG_ 1338 SAK_Charisma_FahrPr 0;
BA_ "GenSigSendType" SG_ 1338 SAK_Charisma_Status 0;
BA_ "GenSigSendType" SG_ 1338 SAK_Charisma_Umschaltung 0;
BA_ "GenSigFuncType" SG_ 1338 SAK_01_alt 5;
BA_ "GenSigStartValue" SG_ 1338 SAK_01_alt 1;
BA_ "GenSigSendType" SG_ 1338 SAK_01_alt 0;
BA_ "GenSigSendType" SG_ 1338 NR_Niveaufunktion_aktiv 0;
BA_ "GenSigFuncType" SG_ 1338 Daempfer_01_alt 5;
BA_ "GenSigStartValue" SG_ 1338 Daempfer_01_alt 1;
BA_ "GenSigSendType" SG_ 1338 Daempfer_01_alt 0;
BA_ "GenSigStartValue" SG_ 1338 CHA_04_va_57 1;
BA_ "GenSigSendType" SG_ 1338 CHA_04_va_57 0;
BA_ "GenSigStartValue" SG_ 1338 CHA_04_va_67 1;
BA_ "GenSigSendType" SG_ 1338 CHA_04_va_67 0;
BA_ "GenSigStartValue" SG_ 1338 CHA_04_va_77 1;
BA_ "GenSigSendType" SG_ 1338 CHA_04_va_77 0;
BA_ "GenSigStartValue" SG_ 1338 CHA_04_va_87 1;
BA_ "GenSigSendType" SG_ 1338 CHA_04_va_87 0;
BA_REL_ "GenSigTimeoutTime" BU_SG_REL_ Miko_PAG_X2 SG_ 192 Adr_Clima_Mono 5000;
BA_REL_ "GenSigTimeoutTime" BU_SG_REL_ Miko_PAG_X2 SG_ 192 Adr_AC_Menue_LED_an 5000;
BA_REL_ "GenSigTimeoutTime" BU_SG_REL_ Miko_PAG_X2 SG_ 192 Adr_Phone_LED_an 5000;
BA_REL_ "GenSigTimeoutTime" BU_SG_REL_ Miko_PAG_X2 SG_ 192 Adr_Media_LED_an 5000;
BA_REL_ "GenSigTimeoutTime" BU_SG_REL_ Miko_PAG_X2 SG_ 192 Adr_Tuner_LED_an 5000;
BA_REL_ "GenSigTimeoutTime" BU_SG_REL_ Miko_PAG_X2 SG_ 192 Adr_Car_LED_an 5000;
BA_REL_ "GenSigTimeoutTime" BU_SG_REL_ Miko_PAG_X2 SG_ 192 Adr_Info_LED_an 5000;
BA_REL_ "GenSigTimeoutTime" BU_SG_REL_ Miko_PAG_X2 SG_ 192 Adr_Navi_LED_an 5000;
BA_REL_ "GenSigTimeoutTime" BU_SG_REL_ Miko_PAG_X2 SG_ 192 Adr_Alive_Cnt 5000;
BA_REL_ "GenSigTimeoutTime" BU_SG_REL_ Miko_PAG_X2 SG_ 192 Adr_Pos_En 5000;
BA_REL_ "GenSigTimeoutTime" BU_SG_REL_ Miko_PAG_X2 SG_ 192 Adr_Display_Status 5000;
BA_REL_ "GenSigTimeoutTime" BU_SG_REL_ Miko_PAG_X2 SG_ 192 Adr_Active_Character_Page 5000;
BA_REL_ "GenSigTimeoutTime" BU_SG_REL_ Miko_PAG_X2 SG_ 192 Adr_Chr_Mode 5000;
BA_REL_ "GenSigTimeoutTime" BU_SG_REL_ Miko_PAG_X2 SG_ 192 Adr_Gst_Mode 5000;
BA_REL_ "GenSigTimeoutTime" BU_SG_REL_ Kombi_PAG_PF SG_ 194 Adr_Konfig_Datenfeld 1000;
BA_REL_ "GenSigTimeoutTime" BU_SG_REL_ Kombi_PAG_PF SG_ 194 Adr_KI_BC_Rolle_Konfig 1000;
BA_REL_ "GenSigTimeoutTime" BU_SG_REL_ Kombi_PAG_PF SG_ 194 Adr_KI_BC_Rolle_Datenfeld 1000;
BA_REL_ "GenSigTimeoutTime" BU_SG_REL_ Kombi_PAG_PF SG_ 194 Adr_Joker_Taste 1000;
BA_REL_ "GenSigTimeoutTime" BU_SG_REL_ Kombi_PAG_PF SG_ 194 Adr_KL58d 1000;
BA_REL_ "GenSigTimeoutTime" BU_SG_REL_ Kombi_PAG_PF SG_ 194 Adr_KI_Helligkeit 1000;
BA_REL_ "GenSigTimeoutTime" BU_SG_REL_ Miko_PAG_X2 SG_ 194 Adr_Miko_Helligkeit 1000;
BA_REL_ "GenSigTimeoutTime" BU_SG_REL_ Kombi_PAG_PF SG_ 64 AB_Lampe 500;
BA_REL_ "GenSigTimeoutTime" BU_SG_REL_ Kombi_PAG_PF SG_ 64 AB_VB_deaktiviert 500;
BA_REL_ "GenSigTimeoutTime" BU_SG_REL_ Kombi_PAG_PF SG_ 64 AB_Systemfehler 500;
BA_REL_ "GenSigTimeoutTime" BU_SG_REL_ Kombi_PAG_PF SG_ 64 AB_Gurtwarn_VF 500;
BA_REL_ "GenSigTimeoutTime" BU_SG_REL_ Kombi_PAG_PF SG_ 64 AB_Gurtwarn_VB 500;
BA_REL_ "GenSigTimeoutTime" BU_SG_REL_ Kombi_PAG_PF SG_ 64 AB_Anzeige_Fussg 500;
BA_REL_ "GenSigTimeoutTime" BU_SG_REL_ Kombi_PAG_PF SG_ 1632 AB_Gurtschloss_FA 5000;
BA_REL_ "GenSigTimeoutTime" BU_SG_REL_ Kombi_PAG_PF SG_ 1634 BCM1_Bremsfluessigkeit_Warn 5000;
BA_REL_ "GenSigTimeoutTime" BU_SG_REL_ Kombi_PAG_PF SG_ 1634 BCM1_Licht_Warn 5000;
BA_REL_ "GenSigTimeoutTime" BU_SG_REL_ Kombi_PAG_PF SG_ 1634 BCM1_Waschwasser_Warn 5000;
BA_REL_ "GenSigTimeoutTime" BU_SG_REL_ Kombi_PAG_PF SG_ 1634 LV_Aussenlicht_def 5000;
BA_REL_ "GenSigTimeoutTime" BU_SG_REL_ Kombi_PAG_PF SG_ 1634 LV_AFL_defekt 5000;
BA_REL_ "GenSigTimeoutTime" BU_SG_REL_ Kombi_PAG_PF SG_ 1634 BCM1_MH_Schalter 5000;
BA_REL_ "GenSigTimeoutTime" BU_SG_REL_ OCU_PAG_PF SG_ 1634 BCM1_MH_Schalter 5000;
BA_REL_ "GenSigTimeoutTime" BU_SG_REL_ ADR_PAG_X2 SG_ 1634 LV_Standlicht_Anzeige 5000;
BA_REL_ "GenSigTimeoutTime" BU_SG_REL_ Kombi_PAG_PF SG_ 1634 LV_Standlicht_Anzeige 5000;
BA_REL_ "GenSigTimeoutTime" BU_SG_REL_ Kombi_PAG_PF SG_ 1634 LV_Abblendlicht_Anzeige 5000;
BA_REL_ "GenSigTimeoutTime" BU_SG_REL_ Kombi_PAG_PF SG_ 1634 LV_Fernlicht_Anzeige 5000;
BA_REL_ "GenSigTimeoutTime" BU_SG_REL_ Kombi_PAG_PF SG_ 1634 LV_Nebelschlusslicht_Anzeige 5000;
BA_REL_ "GenSigTimeoutTime" BU_SG_REL_ Kombi_PAG_PF SG_ 1634 LV_Tagfahrlicht_Anzeige 5000;
BA_REL_ "GenSigTimeoutTime" BU_SG_REL_ Kombi_PAG_PF SG_ 1634 LV_Blinker_li_def 5000;
BA_REL_ "GenSigTimeoutTime" BU_SG_REL_ Kombi_PAG_PF SG_ 1634 LV_Standlicht_li_def 5000;
BA_REL_ "GenSigTimeoutTime" BU_SG_REL_ Kombi_PAG_PF SG_ 1634 LV_Abblendlicht_li_def 5000;
BA_REL_ "GenSigTimeoutTime" BU_SG_REL_ Kombi_PAG_PF SG_ 1634 LV_Fernlicht_li_def 5000;
BA_REL_ "GenSigTimeoutTime" BU_SG_REL_ Kombi_PAG_PF SG_ 1634 LV_Nebellicht_li_def 5000;
BA_REL_ "GenSigTimeoutTime" BU_SG_REL_ Kombi_PAG_PF SG_ 1634 LV_Blk_li_Seite_def 5000;
BA_REL_ "GenSigTimeoutTime" BU_SG_REL_ Kombi_PAG_PF SG_ 1634 LV_FLA_aktiv_Anzeige 5000;
BA_REL_ "GenSigTimeoutTime" BU_SG_REL_ Kombi_PAG_PF SG_ 1634 LV_FLA_defekt 5000;
BA_REL_ "GenSigTimeoutTime" BU_SG_REL_ Kombi_PAG_PF SG_ 1634 LV_FLA_Sensor_blockiert 5000;
BA_REL_ "GenSigTimeoutTime" BU_SG_REL_ Kombi_PAG_PF SG_ 1634 LV_Blinker_re_def 5000;
BA_REL_ "GenSigTimeoutTime" BU_SG_REL_ Kombi_PAG_PF SG_ 1634 LV_Standlicht_re_def 5000;
BA_REL_ "GenSigTimeoutTime" BU_SG_REL_ Kombi_PAG_PF SG_ 1634 LV_Abblendlicht_re_def 5000;
BA_REL_ "GenSigTimeoutTime" BU_SG_REL_ Kombi_PAG_PF SG_ 1634 LV_Fernlicht_re_def 5000;
BA_REL_ "GenSigTimeoutTime" BU_SG_REL_ Kombi_PAG_PF SG_ 1634 LV_Nebellicht_re_def 5000;
BA_REL_ "GenSigTimeoutTime" BU_SG_REL_ Kombi_PAG_PF SG_ 1634 LV_Blk_re_Seite_def 5000;
BA_REL_ "GenSigTimeoutTime" BU_SG_REL_ Kombi_PAG_PF SG_ 1697 BCM1_W_ELV 5000;
BA_REL_ "GenSigTimeoutTime" BU_SG_REL_ Kombi_PAG_PF SG_ 1697 BCM1_W_Blinker_HR_def 5000;
BA_REL_ "GenSigTimeoutTime" BU_SG_REL_ Kombi_PAG_PF SG_ 1697 BCM1_W_Blinker_HL_def 5000;
BA_REL_ "GenSigTimeoutTime" BU_SG_REL_ Kombi_PAG_PF SG_ 1697 BCM1_W_LWR_def 5000;
BA_REL_ "GenSigTimeoutTime" BU_SG_REL_ Kombi_PAG_PF SG_ 1697 BCM1_W_Parklicht 5000;
BA_REL_ "GenSigTimeoutTime" BU_SG_REL_ Klima_PAG_PF SG_ 1697 BCM1_St_ZV 5000;
BA_REL_ "GenSigTimeoutTime" BU_SG_REL_ OCU_PAG_PF SG_ 1697 BCM1_St_ZV 5000;
BA_REL_ "GenSigTimeoutTime" BU_SG_REL_ Klima_PAG_PF SG_ 1697 BCM1_FSH_aktiv 5000;
BA_REL_ "GenSigTimeoutTime" BU_SG_REL_ Kombi_PAG_PF SG_ 1697 BCM1_Seitenmarker_li_def 5000;
BA_REL_ "GenSigTimeoutTime" BU_SG_REL_ Kombi_PAG_PF SG_ 1697 BCM1_Seitenmarker_re_def 5000;
BA_REL_ "GenSigTimeoutTime" BU_SG_REL_ OCU_PAG_PF SG_ 1409 ZV_FT_offen 2000;
BA_REL_ "GenSigTimeoutTime" BU_SG_REL_ OCU_PAG_PF SG_ 1409 ZV_BT_offen 2000;
BA_REL_ "GenSigTimeoutTime" BU_SG_REL_ OCU_PAG_PF SG_ 1409 ZV_HL_offen 2000;
BA_REL_ "GenSigTimeoutTime" BU_SG_REL_ OCU_PAG_PF SG_ 1409 ZV_HR_offen 2000;
BA_REL_ "GenSigTimeoutTime" BU_SG_REL_ OCU_PAG_PF SG_ 1409 ZV_HD_offen 2000;
BA_REL_ "GenSigTimeoutTime" BU_SG_REL_ OCU_PAG_PF SG_ 1409 ZV_Turen_HD_zu 2000;
BA_REL_ "GenSigTimeoutTime" BU_SG_REL_ OCU_PAG_PF SG_ 1409 ZV_HS_offen 2000;
BA_REL_ "GenSigTimeoutTime" BU_SG_REL_ Kombi_PAG_PF SG_ 900 BCM2_W_TagfahrL_re_def 1000;
BA_REL_ "GenSigTimeoutTime" BU_SG_REL_ Kombi_PAG_PF SG_ 900 BCM2_W_TagfahrL_li_def 1000;
BA_REL_ "GenSigTimeoutTime" BU_SG_REL_ Kombi_PAG_PF SG_ 900 BCM2_W_Kuehlwasserstand 1000;
BA_REL_ "GenSigTimeoutTime" BU_SG_REL_ Kombi_PAG_PF SG_ 900 BCM2_W_HSpoiler_1 1000;
BA_REL_ "GenSigTimeoutTime" BU_SG_REL_ Kombi_PAG_PF SG_ 900 BCM2_W_HSpoiler_2 1000;
BA_REL_ "GenSigTimeoutTime" BU_SG_REL_ Klima_PAG_PF SG_ 900 BCM2_W_Dach_n_geschl 1000;
BA_REL_ "GenSigTimeoutTime" BU_SG_REL_ Kombi_PAG_PF SG_ 900 BCM2_W_Dach_n_geschl 1000;
BA_REL_ "GenSigTimeoutTime" BU_SG_REL_ Kombi_PAG_PF SG_ 900 BCM2_Bremsbelag_Warn 1000;
BA_REL_ "GenSigTimeoutTime" BU_SG_REL_ Klima_PAG_PF SG_ 900 BCM2_Hauptraste_HK_aktiv 1000;
BA_REL_ "GenSigTimeoutTime" BU_SG_REL_ Klima_PAG_PF SG_ 900 BCM2_HsHzg_aktiv 1000;
BA_REL_ "GenSigTimeoutTime" BU_SG_REL_ Klima_PAG_PF SG_ 900 BCM2_St_LED_HSpoiler 1000;
BA_REL_ "GenSigTimeoutTime" BU_SG_REL_ ADR_PAG_X2 SG_ 900 BCM2_DWA_aktiv 1000;
BA_REL_ "GenSigTimeoutTime" BU_SG_REL_ Kombi_PAG_PF SG_ 900 BCM2_W_SpoilerInfo 1000;
BA_REL_ "GenSigTimeoutTime" BU_SG_REL_ Klima_PAG_PF SG_ 900 BCM2_Rollo_Bew 1000;
BA_REL_ "GenSigTimeoutTime" BU_SG_REL_ Kombi_PAG_PF SG_ 1658 BCM2_Tankabgl_01 5000;
BA_REL_ "GenSigTimeoutTime" BU_SG_REL_ Kombi_PAG_PF SG_ 1658 BCM2_Tankabgl_02 5000;
BA_REL_ "GenSigTimeoutTime" BU_SG_REL_ Kombi_PAG_PF SG_ 1658 BCM2_Tankabgl_03 5000;
BA_REL_ "GenSigTimeoutTime" BU_SG_REL_ ADR_PAG_X2 SG_ 1635 BEM_02_Abschaltstufen 1000;
BA_REL_ "GenSigTimeoutTime" BU_SG_REL_ Klima_PAG_PF SG_ 1635 BEM_02_Abschaltstufen 1000;
BA_REL_ "GenSigTimeoutTime" BU_SG_REL_ Klima_PAG_PF SG_ 1635 BEM_HL_Kontingentierung 1000;
BA_REL_ "GenSigTimeoutTime" BU_SG_REL_ Klima_PAG_PF SG_ 1635 BEM_HL_Kontingentierung 1000;
BA_REL_ "GenSigTimeoutTime" BU_SG_REL_ Kombi_PAG_PF SG_ 1635 BEM_Generatordiagnose 1000;
BA_REL_ "GenSigTimeoutTime" BU_SG_REL_ Klima_PAG_PF SG_ 1635 BEM_Red_Innengeblaese 1000;
BA_REL_ "GenSigTimeoutTime" BU_SG_REL_ Klima_PAG_PF SG_ 1635 BEM_HL_Regelung_Status 1000;
BA_REL_ "GenSigTimeoutTime" BU_SG_REL_ Klima_PAG_PF SG_ 1635 BEM_HL_Regelung_Status 1000;
BA_REL_ "GenSigTimeoutTime" BU_SG_REL_ Kombi_PAG_PF SG_ 1635 BEM_Ladezustand 1000;
BA_REL_ "GenSigTimeoutTime" BU_SG_REL_ Kombi_PAG_PF SG_ 1635 BEM_Batteriediagnose 1000;
BA_REL_ "GenSigTimeoutTime" BU_SG_REL_ Kombi_PAG_PF SG_ 1635 BEM_UBDM 1000;
BA_REL_ "GenSigTimeoutTime" BU_SG_REL_ Kombi_PAG_PF SG_ 1326 BEM_blAbschaltungSteckdAnz 2500;
BA_REL_ "GenSigTimeoutTime" BU_SG_REL_ Kombi_PAG_PF SG_ 1326 BEM_blReduzInnenGeblaeseAnz 2500;
BA_REL_ "GenSigTimeoutTime" BU_SG_REL_ Kombi_PAG_PF SG_ 1326 BEM_blKl30Transport 2500;
BA_REL_ "GenSigTimeoutTime" BU_SG_REL_ Kombi_PAG_PF SG_ 1326 BEM_blKl30fAusAnzeige 2500;
BA_REL_ "GenSigTimeoutTime" BU_SG_REL_ Kombi_PAG_PF SG_ 867 Blinken_li_Kombi_Takt 500;
BA_REL_ "GenSigTimeoutTime" BU_SG_REL_ Kombi_PAG_PF SG_ 867 Blinken_re_Kombi_Takt 500;
BA_REL_ "GenSigTimeoutTime" BU_SG_REL_ Kombi_PAG_PF SG_ 687 BMS_Rekuperation 500;
BA_REL_ "GenSigTimeoutTime" BU_SG_REL_ Kombi_PAG_PF SG_ 687 BMS_Rekuperation_Ueberlauf 500;
BA_REL_ "GenSigTimeoutTime" BU_SG_REL_ Kombi_PAG_PF SG_ 687 BMS_Verbrauch 500;
BA_REL_ "GenSigTimeoutTime" BU_SG_REL_ Kombi_PAG_PF SG_ 687 BMS_Verbrauch_Ueberlauf 500;
BA_REL_ "GenSigTimeoutTime" BU_SG_REL_ Klima_PAG_PF SG_ 1438 BMS_IstVorlaufTemperatur 5000;
BA_REL_ "GenSigTimeoutTime" BU_SG_REL_ Klima_PAG_PF SG_ 1438 BMS_SollVorlauftemperatur 5000;
BA_REL_ "GenSigTimeoutTime" BU_SG_REL_ Klima_PAG_PF SG_ 1438 BMS_IstRuecklaufTemperatur_02 5000;
BA_REL_ "GenSigTimeoutTime" BU_SG_REL_ Kombi_PAG_PF SG_ 1482 BMS_07_CRC 5000;
BA_REL_ "GenSigTimeoutTime" BU_SG_REL_ Kombi_PAG_PF SG_ 1482 BMS_07_BZ 5000;
BA_REL_ "GenSigTimeoutTime" BU_SG_REL_ Kombi_PAG_PF SG_ 1482 BMS_Gesamtst_Spgfreiheit 5000;
BA_REL_ "GenSigTimeoutTime" BU_SG_REL_ Klima_PAG_PF SG_ 1519 BMS_Status_Kuehlung 5000;
BA_REL_ "GenSigTimeoutTime" BU_SG_REL_ OCU_PAG_PF SG_ 1519 BMS_Status_Kuehlung 5000;
BA_REL_ "GenSigTimeoutTime" BU_SG_REL_ Klima_PAG_PF SG_ 1519 BMS_Temp_Zelle_Min 5000;
BA_REL_ "GenSigTimeoutTime" BU_SG_REL_ Klima_PAG_PF SG_ 1519 BMS_Temp_Zelle_Max 5000;
BA_REL_ "GenSigTimeoutTime" BU_SG_REL_ Kombi_PAG_PF SG_ 1519 BMS_Temp_Zelle_Max 5000;
BA_REL_ "GenSigTimeoutTime" BU_SG_REL_ Klima_PAG_PF SG_ 1519 BMS_Pumpendrehzahl 5000;
BA_REL_ "GenSigTimeoutTime" BU_SG_REL_ Klima_PAG_PF SG_ 1519 BMS_Status_3_2_Ventil1 5000;
BA_REL_ "GenSigTimeoutTime" BU_SG_REL_ Klima_PAG_PF SG_ 1519 BMS_Status_3_2_Ventil2 5000;
BA_REL_ "GenSigTimeoutTime" BU_SG_REL_ Klima_PAG_PF SG_ 1628 BMS_HYB_Kuehlung_Anf 5000;
BA_REL_ "GenSigTimeoutTime" BU_SG_REL_ Kombi_PAG_PF SG_ 903 EBKV_Hinweise 1000;
BA_REL_ "GenSigTimeoutTime" BU_SG_REL_ Kombi_PAG_PF SG_ 903 EBKV_Warnungen 1000;
BA_REL_ "GenSigTimeoutTime" BU_SG_REL_ Kombi_PAG_PF SG_ 903 EBKV_BKL_Warnungen 1000;
BA_REL_ "GenSigTimeoutTime" BU_SG_REL_ Klima_PAG_PF SG_ 1336 MO_Charisma_FahrPr 2000;
BA_REL_ "GenSigTimeoutTime" BU_SG_REL_ Klima_PAG_PF SG_ 1336 MO_Charisma_Status 2000;
BA_REL_ "GenSigTimeoutTime" BU_SG_REL_ Klima_PAG_PF SG_ 1336 MO_Charisma_Umschaltung 2000;
BA_REL_ "GenSigTimeoutTime" BU_SG_REL_ Klima_PAG_PF SG_ 1336 Motor_05_alt 2000;
BA_REL_ "GenSigTimeoutTime" BU_SG_REL_ Klima_PAG_PF SG_ 1336 GE_Charisma_FahrPr 2000;
BA_REL_ "GenSigTimeoutTime" BU_SG_REL_ Klima_PAG_PF SG_ 1336 GE_Charisma_Status 2000;
BA_REL_ "GenSigTimeoutTime" BU_SG_REL_ Klima_PAG_PF SG_ 1336 GE_Charisma_Umschaltung 2000;
BA_REL_ "GenSigTimeoutTime" BU_SG_REL_ Klima_PAG_PF SG_ 1336 Getriebe_04_alt 2000;
BA_REL_ "GenSigTimeoutTime" BU_SG_REL_ Klima_PAG_PF SG_ 1336 DR_Charisma_FahrPr 2000;
BA_REL_ "GenSigTimeoutTime" BU_SG_REL_ Klima_PAG_PF SG_ 1336 DR_Charisma_Status 2000;
BA_REL_ "GenSigTimeoutTime" BU_SG_REL_ Klima_PAG_PF SG_ 1336 DR_Charisma_Umschaltung 2000;
BA_REL_ "GenSigTimeoutTime" BU_SG_REL_ Klima_PAG_PF SG_ 1336 Daempfer_01_alt 2000;
BA_REL_ "GenSigTimeoutTime" BU_SG_REL_ Klima_PAG_PF SG_ 1338 EPS_Charisma_FahrPr 2000;
BA_REL_ "GenSigTimeoutTime" BU_SG_REL_ Klima_PAG_PF SG_ 1338 EPS_Charisma_Status 2000;
BA_REL_ "GenSigTimeoutTime" BU_SG_REL_ Klima_PAG_PF SG_ 1338 EPS_Charisma_Umschaltung 2000;
BA_REL_ "GenSigTimeoutTime" BU_SG_REL_ Klima_PAG_PF SG_ 1338 EPS_FR_alt 2000;
VAL_ 192 Adr_Clima_Mono 0 "Mono_inaktiv" 1 "Mono_aktiv" ;
VAL_ 192 Adr_T_LVT_O 0 "Taster nicht betaetigt" 1 "Taster betaetigt" ;
VAL_ 192 Adr_T_LVT_M 0 "Taster nicht betaetigt" 1 "Taster betaetigt" ;
VAL_ 192 Adr_T_LVT_U 0 "Taster nicht betaetigt" 1 "Taster betaetigt" ;
VAL_ 192 Adr_AC_Menue_LED_an 0 "AC-Menue nicht angewaehlt" 1 "AC-Menue angewaehlt" ;
VAL_ 192 Adr_Phone_LED_an 0 "Phone-Menue nicht angewaehlt" 1 "Phone-Menue angewaehlt" ;
VAL_ 192 Adr_Media_LED_an 0 "Media-Menue nicht angewaehlt" 1 "Media-Menue angewaehlt" ;
VAL_ 192 Adr_Tuner_LED_an 0 "Tuner-Menue nicht angewaehlt" 1 "Tuner-Menue angewaehlt" ;
VAL_ 192 Adr_Car_LED_an 0 "Car-Menue nicht angewaehlt" 1 "Car-Menue angewaehlt" ;
VAL_ 192 Adr_Info_LED_an 0 "Info-Menue nicht angewaehlt" 1 "Info-Menue angewaehlt" ;
VAL_ 192 Adr_Navi_LED_an 0 "Navi-Menue nicht angewaehlt" 1 "Navi-Menue angewaehlt" ;
VAL_ 192 Adr_Pos_En 0 "deaktiviert" 1 "aktiviert" ;
VAL_ 192 Adr_Display_Status 0 "Display_aus" 1 "Display_an" ;
VAL_ 192 Adr_Active_Character_Page 0 "Nicht_Definiert" 1 "Basic_Latin" 2 "Latin1_Supplement" 3 "Cyrillic" 4 "Arabic" ;
VAL_ 194 Adr_Konfig_Datenfeld 0 "Keine_Konfiguration" 1 "Konfiguration_Datenfeld_1" 2 "Konfiguration_Datenfeld_2" 3 "Konfiguration_Datenfeld_3" 4 "Konfiguration_Datenfeld_4" ;
VAL_ 194 Adr_KI_BC_Rolle_Datenfeld 0 "Keine_Anzeige" 1 "Bordspannung" 2 "Oeldruck" 3 "Oeltemperatur" 4 "Kuehlwassertemperatur" 5 "Restreichweite" 6 "Kompass" 7 "Hoehe" 8 "Datum" 9 "Uhrzeit" 10 "Aussentemperatur" 11 "Querbeschleunigung" 12 "Beschleuningung" 13 "Verzoegerung" 14 "Reichweite" 15 "elektr_Restreichweite" 16 "Restladezeit" 17 "Ladezustand" ;
VAL_ 194 Adr_Joker_Taste 0 "BC_Seite_Fahrzeug" 1 "Trip" 2 "GForce" 3 "Schaltanzeige" 4 "E_Power_Assist" 5 "RDK" 6 "Chrono_Lite" ;
VAL_ 194 Adr_KL58d 126 "Init" 127 "Fehler" ;
VAL_ 194 Adr_KI_Helligkeit 126 "Init" 127 "Fehler" ;
VAL_ 194 Adr_Miko_Helligkeit 126 "Init" 127 "Fehler" ;
VAL_ 64 AB_RGS_Anst 4 "aktiv_Niveau_1" 5 "aktiv_Niveau_2" 6 "aktiv_Niveau_3" 7 "aktiv_Niveau_4" 8 "deaktiviert" ;
VAL_ 64 AB_Front_Crash 0 "kein_Front_Crash" 1 "Front_Crash" ;
VAL_ 64 AB_Heck_Crash 0 "kein_Heck_Crash" 1 "Heck_Crash" ;
VAL_ 64 AB_SF_Crash 0 "kein_Seiten_Crash_Fahrer" 1 "Seiten_Crash_Fahrer" ;
VAL_ 64 AB_SB_Crash 0 "kein_Seiten_Crash_Beifahrer" 1 "Seiten_Crash_Beifahrer" ;
VAL_ 64 AB_Rollover_Crash 0 "kein_Rollover" 1 "Rollover" ;
VAL_ 64 AB_Crash_Int 0 "kein_Crash" 1 "Crash_Intensitaet_1" 2 "Crash_Intensitaet_2_(nur_Stellgliedtest_MLB_B8)" 3 "Crash_Intensitaet_2_(nur_D4_C7_Colorado_NF_PAG__Crash_im_MLB_B8)" 4 "Crash_Intensitaet_3_(alt_VW/AUDI__Stellgliedtest_MLB_B8)" 5 "Crash_Intensitaet_3_(alt_PAG)" 7 "Crash_Intensitaet_3" ;
VAL_ 64 AB_Lampe 0 "Aus" 1 "Ein" ;
VAL_ 64 AB_Deaktiviert 0 "aktiv" 1 "deaktiviert" ;
VAL_ 64 AB_VB_deaktiviert 0 "Beifahrerairbag_aktiv" 1 "Beifahrerairbag_deaktiviert" ;
VAL_ 64 AB_Systemfehler 0 "kein_Fehler" 1 "Airbag_Systemfehler" ;
VAL_ 64 AB_Diagnose 0 "nicht_in_Diagnose" 1 "in_Diagnose" ;
VAL_ 64 AB_Stellgliedtest 0 "nicht_im_Stellgliedtest" 1 "Airbag_im_Stellgliedtest" ;
VAL_ 64 AB_Erh_Auf_VB 0 "keine_Anzeige" 1 "Beifahrerairbag_deaktiviert" 2 "Beifahrerairbag_aktiviert" 3 "nicht_definiert" ;
VAL_ 64 AB_Gurtwarn_VF 0 "keine_Warnung" 1 "Gurtwarnung_ausloesen" ;
VAL_ 64 AB_Gurtwarn_VB 0 "keine_Warnung" 1 "Gurtwarnung_ausloesen" ;
VAL_ 64 AB_Anzeige_Fussg 0 "keine_FSG_Aktion_ausgeloest" 1 "Motorhaube_offen" 2 "Systemfehler" ;
VAL_ 64 AB_Texte_AKS 0 "keine_AKS_Ausloesung" 1 "AKS_ausgeloest" 2 "AKS_Systemfehler" ;
VAL_ 64 AB_PAO_Leuchte_Anf 0 "Leuchte_ausschalten" 1 "Leuchte_einschalten" ;
VAL_ 64 AB_MKB_gueltig 0 "Multikollisionsbremsung_nicht_freigeschaltet" 1 "Multikollisionsbremsung_freigeschaltet" ;
VAL_ 64 AB_Versorgungsspannung 0 "plausibel" 1 "unplausibel" ;
VAL_ 64 AB_Deaktivierung_HV 0 "keine_Deaktivierung" 1 "Deaktivierung_1" 2 "Deaktivierung_2" 3 "Deaktivierung_3" 4 "Deaktivierung_4" 5 "Deaktivierung_5" 6 "Deaktivierung_6" 7 "Deaktivierung_7" ;
VAL_ 64 AB_EDR_Trigger 0 "No_Event" 1 "Start_Event" 2 "NonDeployment_Event" 3 "Deployment_Event" ;
VAL_ 64 AB_KD_Fehler 0 "kein_KD_Fehler" 1 "KD_Fehler" ;
VAL_ 1632 AB_Belegung_VB 0 "nicht_verfuegbar" 1 "Fehler" 2 "nicht_belegt" 3 "belegt" ;
VAL_ 1632 AB_Gurtschloss_FA 0 "nicht_verbaut" 1 "nicht_verfügbar (Fehler oder Init)" 2 "nicht_gesteckt" 3 "gesteckt" ;
VAL_ 1632 AB_Gurtschloss_BF 0 "nicht_verbaut" 1 "nicht_verfügbar (Fehler oder Init)" 2 "nicht_gesteckt" 3 "gesteckt" ;
VAL_ 1632 AB_Gurtschloss_Reihe2_FA 0 "nicht_verbaut" 1 "nicht_verfügbar (Fehler oder Init)" 2 "nicht_gesteckt" 3 "gesteckt" ;
VAL_ 1632 AB_Gurtschloss_Reihe2_MI 0 "nicht_verbaut" 1 "nicht_verfügbar (Fehler oder Init)" 2 "nicht_gesteckt" 3 "gesteckt" ;
VAL_ 1632 AB_Gurtschloss_Reihe2_BF 0 "nicht_verbaut" 1 "nicht_verfügbar (Fehler oder Init)" 2 "nicht_gesteckt" 3 "gesteckt" ;
VAL_ 1632 AB_Gurtschloss_Reihe3_FA 0 "nicht_verbaut" 1 "nicht_verfügbar (Fehler oder Init)" 2 "nicht_gesteckt" 3 "gesteckt" ;
VAL_ 1632 AB_Gurtschloss_Reihe3_MI 0 "nicht_verbaut" 1 "nicht_verfügbar (Fehler oder Init)" 2 "nicht_gesteckt" 3 "gesteckt" ;
VAL_ 1632 AB_Gurtschloss_Reihe3_BF 0 "nicht_verbaut" 1 "nicht_verfügbar (Fehler oder Init)" 2 "nicht_gesteckt" 3 "gesteckt" ;
VAL_ 1632 AB_Sitzpos_Sens_FA 0 "nicht verfügbar" 1 "Fehler" 2 "Sitz nicht vorne" 3 "Sitz vorne" ;
VAL_ 1632 AB_Sitzpos_Sens_BF 0 "nicht verfügbar" 1 "Fehler" 2 "Sitz nicht vorne" 3 "Sitz vorne" ;
VAL_ 1634 BCM1_Bremsbelag_Warn 0 "OK" 1 "Bremsbelag unter min" ;
VAL_ 1634 BCM1_Bremsfluessigkeit_Warn 0 "OK" 1 "Bremsfluessigkeit unter min" ;
VAL_ 1634 BCM1_Licht_Warn 0 "OK" 1 "Lichtwarnung_aktiv" ;
VAL_ 1634 BCM1_Waschwasser_Warn 0 "OK" 1 "Waschwasser unter min" ;
VAL_ 1634 BCM1_Kuehlmittel_Warn 0 "OK" 1 "Kuehlmittel unter min" ;
VAL_ 1634 BCM1_Gleitende_Leuchtw_Anf 0 "Aus" 1 "Ein" ;
VAL_ 1634 LV_Aussenlicht_def 0 "OK" 1 "defekt" ;
VAL_ 1634 LV_AFL_defekt 0 "OK" 1 "defekt" ;
VAL_ 1634 BCM1_Handbremse_Schalter 0 "nicht betaetigt" 1 "betaetigt" ;
VAL_ 1634 BCM1_MH_Schalter 0 "MH_geschlossen" 1 "MH_offen" ;
VAL_ 1634 BCM1_MH_WIV_Schalter 0 "MH_geschlossen" 1 "MH_offen" ;
VAL_ 1634 BCM1_Oeldruck_Schalter 0 "offen" 1 "geschlossen (p > p soll)" ;
VAL_ 1634 BCM1_Kl_15_HW_erkannt 1 "Klemme 15 erkannt" ;
VAL_ 1634 BCM1_Lenksaeule_aktiv 0 "Lenksaeulenverstellung nicht aktiv" 1 "Lenksaeulenverstellung aktiv" ;
VAL_ 1634 BCM1_Oeldruck_Schalter_2 0 "offen" 1 "geschlossen" ;
VAL_ 1634 BCM1_SRA_aktiv 0 "nicht aktiv" 1 "aktiv" ;
VAL_ 1634 LV_Standlicht_Anzeige 0 "nicht aktiv" 1 "aktiv" ;
VAL_ 1634 LV_Abblendlicht_Anzeige 0 "nicht aktiv" 1 "aktiv" ;
VAL_ 1634 LV_Fernlicht_Anzeige 0 "nicht aktiv" 1 "aktiv" ;
VAL_ 1634 LV_Nebellicht_Anzeige 0 "nicht aktiv" 1 "aktiv" ;
VAL_ 1634 LV_Nebelschlusslicht_Anzeige 0 "nicht aktiv" 1 "aktiv" ;
VAL_ 1634 LV_Tagfahrlicht_Anzeige 0 "nicht aktiv" 1 "aktiv" ;
VAL_ 1634 LV_AFL_aktiv_Anzeige 0 "nicht aktiv" 1 "aktiv" ;
VAL_ 1634 BCM1_Licht_Dunkelheit_aktiv 1 "Licht wegen Dunkelheit aktiv, nicht bei Autobahnlicht, Tagfahrlicht oder Regenlicht" ;
VAL_ 1634 LV_Blinker_li_def 0 "OK" 1 "defekt" ;
VAL_ 1634 LV_Standlicht_li_def 0 "OK" 1 "defekt" ;
VAL_ 1634 LV_Abblendlicht_li_def 0 "OK" 1 "defekt" ;
VAL_ 1634 LV_Fernlicht_li_def 0 "OK" 1 "defekt" ;
VAL_ 1634 LV_Nebellicht_li_def 0 "OK" 1 "defekt" ;
VAL_ 1634 LV_Blk_li_Seite_def 0 "OK" 1 "defekt" ;
VAL_ 1634 LV_Tagfahrlicht_li_def 0 "OK" 1 "defekt" ;
VAL_ 1634 BCM1_GLW_Fernlicht_Anf 0 "Aus" 1 "Ein" ;
VAL_ 1634 LV_Abblendlicht_TFL_li_def 0 "OK" 1 "defekt" ;
VAL_ 1634 LV_Nebellicht_TFL_li_def 0 "OK" 1 "defekt" ;
VAL_ 1634 LV_Standlicht_TFL_li_def 0 "OK" 1 "defekt" ;
VAL_ 1634 LV_Abblend_Fernlicht_li_def 0 "OK" 1 "defekt" ;
VAL_ 1634 LV_FLA_aktiv_Anzeige 0 "aus" 1 "ein" ;
VAL_ 1634 LV_FLA_defekt 0 "i.O." 1 "FLA defekt" ;
VAL_ 1634 LV_FLA_Sensor_blockiert 0 "i.O." 1 "FLA-Sensor blockiert" ;
VAL_ 1634 BCM1_EasyEntry_Status 0 "Aus" 1 "Ein" ;
VAL_ 1634 LV_Blinker_re_def 0 "OK" 1 "defekt" ;
VAL_ 1634 LV_Standlicht_re_def 0 "OK" 1 "defekt" ;
VAL_ 1634 LV_Abblendlicht_re_def 0 "OK" 1 "defekt" ;
VAL_ 1634 LV_Fernlicht_re_def 0 "OK" 1 "defekt" ;
VAL_ 1634 LV_Nebellicht_re_def 0 "OK" 1 "defekt" ;
VAL_ 1634 LV_Blk_re_Seite_def 0 "OK" 1 "defekt" ;
VAL_ 1634 LV_Tagfahrlicht_re_def 0 "OK" 1 "defekt" ;
VAL_ 1634 BCM1_Adaptive_Lichtvert_Anf 0 "Aus" 1 "Ein" ;
VAL_ 1634 LV_Abblendlicht_TFL_re_def 0 "OK" 1 "defekt" ;
VAL_ 1634 LV_Nebellicht_TFL_re_def 0 "OK" 1 "defekt" ;
VAL_ 1634 LV_Standlicht_TFL_re_def 0 "OK" 1 "defekt" ;
VAL_ 1634 LV_Abblend_Fernlicht_re_def 0 "OK" 1 "defekt" ;
VAL_ 1634 BCM1_EasyEntry_texte 0 "keine_Anzeige" 1 "EasyEntry_aus" 2 "EasyEntry_ein" 3 "reserviert" ;
VAL_ 1634 HYB_Anf_E_Mode 0 "Taster_nicht_betaetigt" 1 "Taster_betaetigt" ;
VAL_ 1634 UGDO_Function 0 "LED Function" 1 "Transceiver locked " 2 "HW Error" 3 "Country code acknowledge" 4 "Successful learned" 5 "error value" 6 "Timeout learning" 7 "Fehler" ;
VAL_ 1634 UGDO_LED_Code 0 "LED off" 1 "LED on" 2 "slow Blinkrate 1 Hz" 3 "slow Blinkrate 0.5 Hz" 4 "fast Blinkrate 5.6 Hz" 5 "fast Blinkrate 10 Hz" 6 "Keelog Chamberlain 2s a 9,8Hz 3s on" 7 "error value 1" 8 "Rolling Blinkrate 8.8Hz" 9 "Rolling Blinkrate tbd Hz 1" 10 "Rolling Blinkrate tbd Hz 2 " 11 "Rolling Blinkrate tbd Hz 3" 12 "Rolling Blinkrate tbd Hz 4" 13 "Rolling Blinkrate tbd Hz 5" 14 "Rolling Blinkrate tbd Hz 6" 15 "error value 2" 16 "LED Flashing off" 17 "LED Flashing 1 x 1Hz" 18 "LED Flashing 2 x 1Hz" 19 "LED Flashing 3 x 1Hz" 20 "LED Flashing 4 x 1Hz" 21 "LED Flashing 5 x 1Hz" 22 "LED Flashing 6 x 1Hz" 23 "LED Flashing 7 x 1Hz" 24 "LED Flashing 8 x 1Hz" 25 "LED Flashing 9 x 1Hz" 26 "LED Flashing 10 x 1Hz" 27 "LED Flashing 11 x 1Hz" 28 "LED Flashing 12 x 1Hz" 29 "LED Flashing 13 x 1Hz" 30 "LED Flashing 14 x 1Hz" 31 "error value 3" ;
VAL_ 1697 BCM1_St_ZV 0 "Signal_nicht_gueltig" 1 "entriegelt" 2 "intern_verriegelt" 3 "extern_verriegelt" 4 "safe" 6 " Verriegelt_nach_Wiederverriegelung" ;
VAL_ 1697 BCM1_FSH_aktiv 0 "FSH_inaktiv" 1 "FSH_aktiv" ;
VAL_ 1697 BCM1_DWA_Anf 0 "nicht verwendet" 1 "vollschaerfen" 2 "teilschaerfen" 3 "entschaerfen" ;
VAL_ 1697 LDS_TF_Licht 0 "aus" 1 "ein" ;
VAL_ 1697 LDS_AF_Licht 0 "aus" 1 "ein" ;
VAL_ 1697 LDS_STA_Licht 0 "aus" 1 "ein" ;
VAL_ 1697 LDS_Fahr_Licht 0 "aus" 1 "ein" ;
VAL_ 1697 LDS_Error 0 "kein Fehler" 1 "Fehler" ;
VAL_ 1697 LDS_N_Licht 0 "aus" 1 "an" ;
VAL_ 1697 LDS_NS_Licht 0 "aus" 1 "an" ;
VAL_ 1697 LDS_Nightvision 0 "nicht_betaetigt" 1 "betaetigt" ;
VAL_ 1697 BCM1_Geschw_PSM_erkannt 0 "keine Geschwindigkeit erkannt" 1 "Geschwindigkeit erkannt" ;
VAL_ 1697 BCM1_CH_aktiv 0 "Inaktiv" 1 "Aktiv" ;
VAL_ 1697 BCM1_LH_aktiv 0 "Inaktiv" 1 "Aktiv" ;
VAL_ 1697 BCM1_St_Handschuhfach 0 "Geschlossen" 1 "Geoeffnet" ;
VAL_ 1697 BCM1_Seitenmarker_li_def 0 "i.O." 1 "Defekt" ;
VAL_ 1697 BCM1_Seitenmarker_re_def 0 "i.O." 1 "Defekt" ;
VAL_ 1697 LS_Licht_ein 0 "Aus" 1 "Ein" ;
VAL_ 1697 LS_Licht_ein_invers 0 "Aus" 1 "Ein" ;
VAL_ 1697 LS_Dunkel 0 "Hell" 1 "Dunkel" ;
VAL_ 1697 BCM1_T_Verrieg_TAG 0 "keine_Betaetigung" 1 "kurze_Betaetigung" 2 "Dauerbetaetigung" 3 "Komfortbetaetigung" 4 "Doppelte_Betaetigung" 5 "Reserve" 6 "Reserve" 7 "Reserve" ;
VAL_ 1697 LS_Error 0 "normal" 1 "Fehler" ;
VAL_ 1697 LS_Autobahnfahrlicht 0 "aus" 1 "an" ;
VAL_ 1697 RS_Error 0 "normal" 1 "Fehler" ;
VAL_ 1697 RS_Regenfahrlicht 0 "aus" 1 "an" ;
VAL_ 1697 BCM1_Tankklappe_entriegeln 0 "keine_Aktion__default" 1 "Tankklappe_entriegeln" 2 "Tankklappe_verriegeln" 3 "nicht_verwendet" ;
VAL_ 1697 BCM1_Anf_AbschaltfreigabeKL15 0 "Anforderung nicht aktiv" 1 "Anforderung aktiv" ;
VAL_ 1697 BCM1_St_Timer_KL15_Abschalt 0 "Timer nicht aktiv" 1 "Timer aktiv" ;
VAL_ 1409 BCM_FH_Freigabe 1 "Funktionsfreigabe Fensterheber" ;
VAL_ 1409 BCM_Komfortfkt_Freigabe 0 "Komfortfunktion gesperrt" 1 "globale Freigabe der Komfortfunktion erteilt" ;
VAL_ 1409 BCM_HSK_Freigabe 0 "erlauben" 1 "sperren" ;
VAL_ 1409 BCM_Verdeck_Freigabe 0 "Verdeckbetrieb nicht erlaubt" 1 "Verdeckbetrieb erlaubt" ;
VAL_ 1409 BCM2_Status_Timer_KL15_Abschalt 0 "Anforderung_nicht_aktiv" 1 "Anforderung_aktiv" ;
VAL_ 1409 BCM2_Anford_AbschaltfreigabeKL15 0 "Anforderung_nicht_aktiv" 1 "Anforderung_aktiv" ;
VAL_ 1409 BCM2_Unterdr_Zuendungsmeldung 0 "keine_Unterdr_der_Zuendungsmeldung" 1 "Unterdr_der_Zuendungsmeldung_aktiv" ;
VAL_ 1409 BCM2_KL15_Absch_FT 0 "Zuendung_wurde_bei_Verl_nicht_deaktiviert" 1 "Zuendung_wurde_bei_Verl_deaktiviert" ;
VAL_ 1409 ZV_ist_Zustand_verfuegbar 0 "nicht_verfuegbar" 1 "verfuegbar_alle_TSGs_am_Bus" ;
VAL_ 1409 BCM2_P_verriegelt 0 "WH nicht in Stellung P" 1 "WH in Stellung P" ;
VAL_ 1409 ZV_verriegelt_intern_ist 1 "Fahrzeug innen verriegelt; Istzustand" ;
VAL_ 1409 ZV_verriegelt_extern_ist 1 "Fahrzeug_aussen_verriegelt_Istzustand" ;
VAL_ 1409 ZV_verriegelt_intern_soll 1 "Fahrzeug verriegelt intern; Sollzusstand" ;
VAL_ 1409 ZV_verriegelt_extern_soll 1 "Fahrzeug verriegelt extern; Sollzusstand" ;
VAL_ 1409 ZV_gesafet_extern_ist 1 "Fahrzeug aussen gesafet; Istzustand" ;
VAL_ 1409 ZV_gesafet_extern_soll 1 "Fahrzeug_aussen_gesafet_Sollzustand" ;
VAL_ 1409 ZV_FT_offen 1 "FT_geoeffnet" ;
VAL_ 1409 ZV_BT_offen 1 "BT_geoeffnet" ;
VAL_ 1409 ZV_HL_offen 1 "Tuer_HL_geoeffnet" ;
VAL_ 1409 ZV_HR_offen 1 "Tuer_HR_geoeffnet" ;
VAL_ 1409 ZV_HD_offen 1 "Heckdeckel_auf" ;
VAL_ 1409 ZV_Turen_HD_zu 1 "Türen und HD geschlossen" ;
VAL_ 1409 ZV_Einzeltuerentriegelung 1 "Fahrzeug an Einzeltuer entriegelt" ;
VAL_ 1409 ZV_Heckeinzelentriegelung 1 "Heckdeckeleinzelentriegelung" ;
VAL_ 1409 BCM_ValetTaster_Fkts_LED 0 "LED aus" 1 "LED ein" ;
VAL_ 1409 BCM_HHS_aktiv 1 "Heizbare Heckscheibe aktiv" ;
VAL_ 1409 BCM_Spg_Hzg_Ein 0 "Spiegelheizung nicht einschalten" 1 "Spiegelheizung einschalten (wenn Heckscheiben Heizung eingeschaltet wurde)" ;
VAL_ 1409 ZV_HS_offen 0 "Heckscheibe_geschlossen" 1 "Heckscheibe auf" ;
VAL_ 1409 ZZH_Endlage_oben 0 "ZZH_nicht_in_oberer_Endlage" 1 "ZZH in Endlage oben" ;
VAL_ 1409 ZZH_Endlage_unten 0 "ZZH_nicht_in_unterer_Endlage" 1 "ZZH in Endlage unten" ;
VAL_ 1409 ZZH_Endlage_unplausibel 0 "Endlage_ZZH_plausibel" 1 "unplausible Endlage der ZZH erkannt" ;
VAL_ 1409 BCM2_KD_Fehler 0 "kein_KD_Fehler" 1 "KD_Fehler" ;
VAL_ 1409 NGS_aktiv 0 "Neigungssensor unscharf" 1 "Neigungssensor scharf" ;
VAL_ 1409 IRUE_aktiv 0 "unscharf" 1 "scharf" ;
VAL_ 1409 DWA_aktiv 0 "unscharf" 1 "scharf" ;
VAL_ 1409 Komp_Schutz_aktiv 0 "Komponentenschutz nicht aktiv" 1 "Komponentenschutz aktiv" ;
VAL_ 1409 NGS_Taster_Fkts_LED 0 "LED aus" 1 "LED ein" ;
VAL_ 1409 IRUE_Taster_Fkts_LED 0 "LED aus" 1 "LED ein" ;
VAL_ 1409 HD_Drehfalle_S1 0 "Drehfalle geschlossen" 1 "Drehfalle offen" ;
VAL_ 1409 HD_Sperrklinke_S2 0 "Sperrklinke geschlossen" 1 "Sperrklinke offen" ;
VAL_ 1409 BCM_Verbau_Heckrollo 0 "Heckrollo nicht verbaut" 1 "Heckrollo verbaut" ;
VAL_ 1409 BCM2_EZS_gedrueckt 1 "EZS gedrueckt" ;
VAL_ 1409 BCM2_SST_gedrueckt 1 "SST gedrueckt" ;
VAL_ 1409 LIM_alt 0 "aktuell" 1 "veraltet" ;
VAL_ 1409 LIM_Innenbeleuchtung_V_aktiv 0 "vordere Innenlichter und vordere Leselichter sind alle aus" 1 "min. ein vorderes Innenlicht oder ein vorderes Leselicht ist an" ;
VAL_ 1409 LIM_Innenbeleuchtung_aktiv 0 "saemtliche Innenlichter, Leselichter, Rollolichter und Ambientelichter sind aus" 1 "min. ein Innenlicht, Leselicht oder Ambientelicht ist an" ;
VAL_ 1409 LIM_Taster_Rollolicht_hl 0 "nicht_betaetigt" 1 "betaetigt" ;
VAL_ 1409 LIM_Taster_Rollolicht_hr 0 "nicht_betaetigt" 1 "betaetigt" ;
VAL_ 1409 BCM_Sperrklinke_FT 0 "Schalter_geschlossen_Tuer_offen" 1 "Schalter_offen_Tuer_geschlossen" ;
VAL_ 1409 LIM_Taster_Rollolicht_V 0 "nicht_betaetigt" 1 "betaetigt" ;
VAL_ 1409 BCM_Tankwunsch 0 "Fehler_keine_Drucktankfunktionalitaet" 1 "keine_Betankung_erwuenscht" 2 "Betankung_erwuenscht" ;
VAL_ 1409 ZV_Tankklappe_offen 0 "Tankklappe_geschlossen" 1 "Tankklappe_offen" ;
VAL_ 1409 KST_Warn_P1_ZST_def 0 "nicht_defekt" 1 "defekt" ;
VAL_ 1409 KST_Warn_P2_ZST_def 0 "nicht_defekt" 1 "defekt" ;
VAL_ 900 BCM2_S_RF_Licht 0 "Schalter nicht betätigt" 1 "Schalter betätigt" ;
VAL_ 900 BCM2_ZZH_Endlage_oben 0 "ZZH_nicht_in_oberer_Endlage" 1 "ZZH in Endlage oben" ;
VAL_ 900 BCM2_ZZH_Endlage_unten 0 "ZZH_nicht_in_unterer_Endlage" 1 "ZZH in Endlage unten" ;
VAL_ 900 BCM2_W_VTS_Meldung 0 "Warnung inaktiv" 1 "Warnung aktiv" ;
VAL_ 900 BCM2_W_TagfahrL_re_def 0 "Warnung inaktiv" 1 "Warnung aktiv" ;
VAL_ 900 BCM2_W_TagfahrL_li_def 0 "Warnung inaktiv" 1 "Warnung aktiv" ;
VAL_ 900 BCM2_W_KurvL_re_def 0 "Warnung inaktiv" 1 "Warnung aktiv" ;
VAL_ 900 BCM2_W_KurvL_li_def 0 "Warnung inaktiv" 1 "Warnung aktiv" ;
VAL_ 900 BCM2_W_Kuehlwasserstand 0 "Warnung inaktiv" 1 "Warnung aktiv" ;
VAL_ 900 BCM2_W_HSpoiler_3 0 "Meldung aus" 1 "Meldung an" ;
VAL_ 900 BCM2_W_HSpoiler_4 0 "Meldung aus" 1 "Meldung an" ;
VAL_ 900 BCM2_EBD_Warnblinken_Anf 0 "keine Anforderung" 1 "Anforderung aktiv" ;
VAL_ 900 BCM2_PassiveArming_aktiv 0 "Inaktiv" 1 "Aktiv" ;
VAL_ 900 DK_St_PAO_Leuchte 0 "aus" 1 "ein" 2 "defekt" 3 "ungueltig" ;
VAL_ 900 BCM2_Softtouch_betaetigt 0 "Taster_nicht_betaetigt" 1 "Taster_betaetigt" ;
VAL_ 900 BCM2_St_LED_HSpoiler 0 "inaktiv" 1 "aktiv" 2 "blinken" 3 "blinken_langsam" ;
VAL_ 900 BCM2_Alarmausgabe 0 "inaktiv" 1 "aktiv" ;
VAL_ 900 BCM2_Heckwaschen_Anf 0 "keine_Anforderung" 1 "Anforderung_aktiv" ;
VAL_ 900 BCM2_Geschw_PSM_erkannt 0 " keine Geschwindigkeit erkannt" 1 "Geschwindigkeit erkannt" ;
VAL_ 900 DK_T_Resrv 0 "nicht_betaetigt" 1 "betaetigt" ;
VAL_ 900 DK_F_T_Resrv 0 "normal" 1 "Fehler" ;
VAL_ 900 DK_T_PDC 0 "nicht_betaetigt" 1 "betaetigt" ;
VAL_ 900 DK_F_T_PDC 0 "normal" 1 "Fehler" ;
VAL_ 900 BCM2_W_SpoilerInfo 0 "keine_Meldung" 1 "Spoiler_fahren_aus" 2 "Spoiler_fahren_ein" 3 "Spoiler_sind_ausgefahren" 4 "Spoiler_sind_eingefahren" 5 "Spoiler_ausfahren_nicht_moeglich" 6 "Spoiler_einfahren_nicht_moeglich" 7 "reserviert" ;
VAL_ 900 BCM2_Rollo_Pos 0 "nicht definiert" 1 "Rollo unten" 2 "Rollo oben" 3 "Fehler" ;
VAL_ 900 BCM_Handshake_STH 0 "keine EKP-Ansteuerung durch STH-Anforderung" 1 "EKP-Ansteuerung durch STH-Anforderung" ;
VAL_ 900 BCM2_PAG_KD_Fehler 0 "kein_KD_Fehler" 1 "KD_Fehler" ;
VAL_ 900 BCM2_St_DCDCWandler 0 "i.O." 1 "DCDC1_Uebertemperatur" 2 "DCDC1_defekt" 4 "DCDC2_Uebertemperatur" 8 "DCDC2_defekt" ;
VAL_ 900 BCM2_T_Deckel_Vorne 0 "Taster_nicht_betaetigt" 1 "Taster_betaetigt" ;
VAL_ 900 BCM1_ELV_enable_soll_2 0 "keine Freigabe" 1 "Freigabe" ;
VAL_ 900 BCM1_ELV_enable_Fehler_2 0 "kein Fehler" 1 "Fehler" ;
VAL_ 1658 BCM2_Abschaltfreigabe_KL15 0 "ungueltig" 1 "keine Freigabe zur Abschaltung Klemme 15" 2 "Freigabe zur Abschaltung Klemme 15" 3 "ungueltig" ;
VAL_ 1635 BEM_02_Abschaltstufen 0 "Stufe 0 (keine Einschraenkungen)" 1 "Stufe 1" 2 "Stufe 2" 3 "Stufe 3" 4 "Transportmodus" 7 "Ruhestrommessmodus" ;
VAL_ 1635 BEM_STH_Zielzeit 15 "Fehler" ;
VAL_ 1635 BEM_MMI_Vorwarnung 0 "keine Anzeige" 1 "Anzeige MMI-Vorwarnung" ;
VAL_ 1635 NVEM_Anf_SD_schalten 0 "Anf_SD_Nachlauf_nicht_aktiv" 1 "Anf_SD_Nachlauf_aktiv" ;
VAL_ 1635 BEM_Generatordiagnose 0 "keine Anzeige" 1 "Ladekontrollanzeige ein (Vorhalt)" 2 "rotes Batteriesymbol und Text (Generator defekt)" 3 "Hybrid_DCDC_Wandler_defekt" ;
VAL_ 1635 BEM_Red_Innengeblaese 0 "keine Reduzierung" 1 "Reduzierung Stufe 1" 2 "Reduzierung Stufe 2" 3 "Reduzierung Stufe 2 und Abschaltung Kompressor" ;
VAL_ 1635 BEM_STH_Einschaltverbot 0 "volle Verfuegbarkeit Standheizung/-lueftung" 1 "Standheizung/-lueftung nicht aktivierbar" ;
VAL_ 1635 BEM_HL_Regelung_Status 0 "HL_Regelung_inaktiv_(vor_und_waehrend_Motorstart)" 1 "HL_Regelung_Stufe_1" 2 "HL_Regelung_Stufe_2" 3 "HL_Regelung_Stufe_3" 4 "Verbrauchernotabschaltung_(VNA)" 5 "HL_Regelung_Stufe_5" 7 "Default" ;
VAL_ 1635 BEM_Ladezustand 14 "Init" 15 "Fehler" ;
VAL_ 1635 BEM_Batteriediagnose 0 "keine_Anzeige" 1 "nicht_belegt" 2 "Anzeige_aberkannte_Batterie_(Vorhalt)" 3 "Batteriesymbol_ggf_gelb_und_Text_schwache_Batterie" 4 "Batteriesymbol_ggf_grün_und_Text_Batterie_OK(nur im Transport)" 5 "Batteriesymbol_ggf_gelb_und_Text_Batterie_Laden (nur im Transport)" 6 "Batteriesymbol_ggf_rot_und_Text_Batterie_Prüfen (nur im Transport)" 7 "nicht_belegt" ;
VAL_ 1635 MIB_Stromsparmodus 0 "inaktiv" 1 "aktiv" ;
VAL_ 1635 BEM_REK_aktiv 0 "keine_Rekuperationsfreigabe" 1 "Rekuperationsfreigabe" ;
VAL_ 1635 BEM_EMLIN_ungueltig 0 "Signale_gueltig" 1 "Signale_ungueltig" ;
VAL_ 1635 BEM_Batt_Ab 0 "verbunden" 1 "nicht_verbunden" ;
VAL_ 1635 BEM_UBDM 255 "Fehler" ;
VAL_ 1635 BEM_Anf_KL15_schalten 0 "Keine_Einschraenkung_Kl15" 1 "Empfehlung_auto_Abschaltung_Kl15" 2 "Veto_auto_Abschaltung_Kl15" ;
VAL_ 1326 BEM_blDeaktivierungStandhzgAnz 0 "keine Anzeige" 1 "Anzeige" ;
VAL_ 1326 BEM_blKlemmeG1 0 "Aus" 1 "Ein" ;
VAL_ 1326 BEM_blKl30fAusAnzeige 0 "keine Anzeige" 1 "Klemme 30f wurde eingeschaltet" ;
VAL_ 1326 BEM_Kl15ausAnfProduktion 0 "keine Anforderung die KL15 auszuschalten" 1 "Anforderung KL15 auszuschalten" ;
VAL_ 867 BM_ZV_auf 0 "Blinken bei ZV auf nicht aktiv " 1 "Blinken bei ZV auf aktiv " ;
VAL_ 867 BM_ZV_zu 0 "Blinken bei ZV zu nicht aktiv " 1 "Blinken bei ZV zu aktiv " ;
VAL_ 867 BM_DWA_ein 0 "Quittierungsblinken DWA nicht aktiv " 1 "Quittierungsblinken DWA aktiv " ;
VAL_ 867 BM_DWA_Alarm 0 "DWA-Alarmblinken nicht aktiv " 1 "DWA-Alarmblinken aktiv " ;
VAL_ 867 BM_Crash 0 "Crashblinken nicht aktiv " 1 "Crashblinken aktiv " ;
VAL_ 867 BM_Panik 0 "Panikblinken nicht aktiv " 1 "Panikblinken aktiv " ;
VAL_ 867 BM_Not_Bremsung 0 "Notbremsblinken nicht aktiv " 1 "Notbremsblinken aktiv " ;
VAL_ 867 BM_GDO 0 "Blinken bei UGDO anlernen nicht aktiv " 1 "Blinken bei UGDO anlernen aktiv " ;
VAL_ 867 BM_links 0 "Richtungsblinken links nicht aktiv " 1 "Richtungsblinken links aktiv " ;
VAL_ 867 BM_rechts 0 "Richtungsblinken rechts nicht aktiv " 1 "Richtungsblinken rechts aktiv " ;
VAL_ 867 BM_Warnblinken 0 "Warnblinken nicht aktiv " 1 "Warnblinken aktiv " ;
VAL_ 867 BM_Autobahn 0 "Autobahnblinken_nicht_aktiv" 1 "Autobahnblinken_aktiv " ;
VAL_ 867 BM_Taxi_Notalarm 0 "Blinken bei Taxi-Not-Alarm nicht aktiv " 1 "Blinken bei Taxi-Not-Alarm aktiv " ;
VAL_ 867 BM_Telematik 0 "Telematikblinken nicht aktiv " 1 "Telematikblinken aktiv " ;
VAL_ 867 BM_HD_Oeffnung_angelernt 0 "keine Quittierung" 1 "Quittierung" ;
VAL_ 867 BM_WBT_Beleuchtung 1 "Warnblinktasterfunktionsbeleuchtung soll aktiviert werden (statisch auf 1)" ;
VAL_ 867 Blinken_li_Fzg_Takt 0 "Blinker links ausgeschaltet" 1 "Blinker links eingeschaltet" ;
VAL_ 867 Blinken_re_Fzg_Takt 0 "Blinker rechts ausgeschaltet" 1 "Blinker rechts eingeschaltet" ;
VAL_ 867 Blinken_li_Kombi_Takt 0 "Blinkerkontrolllampe links ausgeschaltet" 1 "Blinkerkontrolllampe links eingeschaltet" ;
VAL_ 867 Blinken_re_Kombi_Takt 0 "Blinkerkontrolllampe rechts ausgeschaltet" 1 "Blinkerkontrolllampe rechts eingeschaltet" ;
VAL_ 867 BM_NBA_n_codiert_n_aktiv 0 "codiert_AND_kein_Fehler" 1 "nicht_codiert_OR_Fehler_erkannt" ;
VAL_ 867 BM_NBA_Status 0 "NBA_nicht_aktiv" 1 "BRL_Dunkelphase" 3 "BRL_Hellphase" ;
VAL_ 867 Blinken_FWB_aktiv 0 "freilaufendes Warnblinken nicht aktiv" 1 "freilaufendes Warnblinken aktiv" ;
VAL_ 687 BMS_Rekuperation_Ueberlauf 0 "kein_Ueberlauf" 1 "Ueberlauf" ;
VAL_ 687 BMS_Verbrauch_Ueberlauf 0 "kein_Ueberlauf" 1 "Ueberlauf" ;
VAL_ 1438 BMS_Temperierung_Anf 0 "hoher_Kuehlbedarf" 1 "mittlerer_Kuehlbedarf" 2 "niedriger_Kuehlbedarf" 3 "kein_Temperierungsbedarf_Init" 4 "niedriger_Heizbedarf" 5 "mittlerer_Heizbedarf" 6 "hoher_Heizbedarf" 7 "Umwaelzungsbedarf" ;
VAL_ 1438 BMS_Soll_PWM_Pumpe 15 "Init" ;
VAL_ 1438 BMS_Temperatur 254 "Init" 255 "Fehler" ;
VAL_ 1438 BMS_IstVorlaufTemperatur 254 "Init" 255 "Fehler" ;
VAL_ 1438 BMS_SollVolumenstrom 62 "Init" 63 "Fehler" ;
VAL_ 1438 BMS_SollVorlauftemperatur 254 "Init" 255 "Fehler" ;
VAL_ 1438 BMS_IstRuecklaufTemperatur_02 254 "Init" 255 "Fehler" ;
VAL_ 1482 BMS_Energieinhalt 2046 "Init" 2047 "Fehler" ;
VAL_ 1482 BMS_Ladevorgang_aktiv 0 "inaktiv" 1 "aktiv" ;
VAL_ 1482 BMS_MaxEnergieinhalt 2046 "Init" 2047 "Fehler" ;
VAL_ 1482 BMS_Ausgleichsladung_Anf 1 "Balancing_Request" ;
VAL_ 1482 BMS_Gesamtst_Spgfreiheit 0 "Funktion_nicht_aktiviert" 1 "HV_System_spannungsfrei" 2 "HV_System_nicht_spannungsfrei" 3 "Fehler_nicht_spannungsfrei" ;
VAL_ 1519 BMS_IstStrom 4094 "Init" 4095 "Fehler" ;
VAL_ 1519 BMS_Status_Kuehlung 0 "Off" 1 "Umwaelzen zum Heizen" 2 "Umwaelzen zum Kuehlen" 3 "passive Kuehlung (NT-Kuehler und Chiller)" 4 "passive Kuehlung" 5 "passive Kuehlung mit Luefter" 6 "aktive Kuehlung (NT-Kuehlerund Chiller)" 7 "aktive Kuehlung (nur Chiller, Voll-Last)" 14 "Init" 15 "Fehler" ;
VAL_ 1519 BMS_Temp_Zelle_Min 254 "Init" 255 "Fehler" ;
VAL_ 1519 BMS_Temp_Zelle_Max 254 "Init" 255 "Fehler" ;
VAL_ 1519 BMS_Pumpendrehzahl 254 "Init" 255 "Fehler" ;
VAL_ 1519 BMS_Status_3_2_Ventil1 0 "Leitung NT-Kuehler und Chiller offen" 1 "Leitung NT-Kuehler offen, Chiller geschlossen" 2 "Leitung NT-Kuehler geschlossen, Chiller offen" 6 "Init" 7 "Fehler" ;
VAL_ 1519 BMS_Status_3_2_Ventil2 0 "Leitung NT-Kuehler und Chiller offen" 1 "Leitung NT-Kuehler offen, Chiller geschlossen" 2 "Leitung NT-Kuehler geschlossen, Chiller offen" 6 "Init" 7 "Fehler" ;
VAL_ 1519 BMS_PTC_IstStrom 254 "Init" 255 "Fehler" ;
VAL_ 1519 BMS_PTC_Stufe 14 "Init" 15 "Fehler" ;
VAL_ 1628 BMS_HYB_ASV_hinten_Status 0 "Ventil_offen" 1 "Ventil_geschlossen" ;
VAL_ 1628 BMS_HYB_ASV_vorne_Status 0 "Ventil_offen" 1 "Ventil_geschlossen" ;
VAL_ 1628 BMS_HYB_KD_Fehler 0 "kein_KD_Fehler" 1 "KD_Fehler" ;
VAL_ 1628 BMS_HYB_BattFanSpd 14 "Init" 15 "Fehler" ;
VAL_ 1628 BMS_HYB_VentilationReq 1 "Ventilation_Request" ;
VAL_ 1628 BMS_HYB_Spuelbetrieb_Status 0 "Umluftbetrieb" 1 "Spuelbetrieb" ;
VAL_ 1628 BMS_HYB_Kuehlung_Anf 0 "keine_Kuehlanforderung" 1 "aktive_Kuehlung_Stufe_1" 2 "aktive_Kuehlung_Stufe_2" 3 "Kuehlung_max" ;
VAL_ 1628 BMS_HYB_Temp_vor_Verd 254 "Init" 255 "Fehler" ;
VAL_ 1628 BMS_HYB_Temp_nach_Verd 254 "Init" 255 "Fehler" ;
VAL_ 1628 BMS_Temperatur 254 "Init" 255 "Fehler" ;
VAL_ 1628 BMS_Temperatur_Ansaugluft 254 "Init" 255 "Fehler" ;
VAL_ 1628 BMS_IstSpannung_HV 254 "Init" 255 "Fehler" ;
VAL_ 903 EBKV_OBD_Status 0 "MIL_aus" 1 "MIL_ein" ;
VAL_ 903 EBKV_Hinweise 0 "i_O_System" 1 "Werkstattdiagnose" 2 "Rollenmodes" 3 "Uebernahme_Feststellbremse" ;
VAL_ 903 EBKV_Warnungen 0 "i_O_System" 1 "Ausfall_2nd_Aktuator" 2 "Reduktion_Bremsverstaerkung" 3 "Ausfall_eBKV_ohne_HBV" 4 "Ausfall_Stillstandsmanagement" ;
VAL_ 903 EBKV_BKL_Warnungen 0 "i_O_System" 1 "Lampen_Pruefung" 2 "Ausfall_eBKV_und_HBV" ;
VAL_ 901 CHA_Systemstatus 0 "Status in Ordnung" 1 "reserviert" 2 "reserviert" 3 "reserviert" ;
VAL_ 901 CHA_Fahrer_Umschaltung 0 "keine_oder_automatische_Umschaltung" 1 "manuelle_Umschaltung" ;
VAL_ 901 CHA_Ziel_FahrPr_MO 0 "nicht_belegt" 1 "Programm_1" 2 "Programm_2" 3 "Programm_3" 4 "Programm_4" 5 "Programm_5" 6 "Programm_6" 7 "Programm_7" ;
VAL_ 901 CHA_Ziel_FahrPr_GE 0 "nicht_belegt" 1 "Programm_1" 2 "Programm_2" 3 "Programm_3" 4 "Programm_4" 5 "Programm_5" 6 "Programm_6" 7 "Programm_7" ;
VAL_ 901 CHA_Ziel_FahrPr_ST 0 "nicht_belegt" 1 "Programm_1" 2 "Programm_2" 3 "Programm_3" 4 "Programm_4" 5 "Programm_5" 6 "Programm_6" 7 "Programm_7" ;
VAL_ 901 CHA_Ziel_FahrPr_SCU 0 "nicht_belegt" 1 "Programm_1" 2 "Programm_2" 3 "Programm_3" 4 "Programm_4" 5 "Programm_5" 6 "Programm_6" 7 "Programm_7" ;
VAL_ 901 CHA_Ziel_FahrPr_DR 0 "nicht_belegt" 1 "Programm_1" 2 "Programm_2" 3 "Programm_3" 4 "Programm_4" 5 "Programm_5" 6 "Programm_6" 7 "Programm_7" ;
VAL_ 901 CHA_Ziel_FahrPr_QS 0 "nicht_belegt" 1 "Programm_1" 2 "Programm_2" 3 "Programm_3" 4 "Programm_4" 5 "Programm_5" 6 "Programm_6" 7 "Programm_7" ;
VAL_ 901 CHA_Ziel_FahrPr_AFS 0 "nicht_belegt" 1 "Programm_1" 2 "Programm_2" 3 "Programm_3" 4 "Programm_4" 5 "Programm_5" 6 "Programm_6" 7 "Programm_7" ;
VAL_ 901 CHA_Ziel_FahrPr_RGS 0 "nicht_belegt" 1 "Programm_1" 2 "Programm_2" 3 "Programm_3" 4 "Programm_4" 5 "Programm_5" 6 "Programm_6" 7 "Programm_7" ;
VAL_ 901 CHA_Ziel_FahrPr_EPS 0 "nicht_belegt" 1 "Programm_1" 2 "Programm_2" 3 "Programm_3" 4 "Programm_4" 5 "Programm_5" 6 "Programm_6" 7 "Programm_7" ;
VAL_ 901 CHA_Ziel_FahrPr_ACC 0 "nicht_belegt" 1 "Programm_1" 2 "Programm_2" 3 "Programm_3" 4 "Programm_4" 5 "Programm_5" 6 "Programm_6" 7 "Programm_7" ;
VAL_ 901 CHA_Ziel_FahrPr_SAK 0 "nicht_belegt" 1 "Programm_1" 2 "Programm_2" 3 "Programm_3" 4 "Programm_4" 5 "Programm_5" 6 "Programm_6" 7 "Programm_7" ;
VAL_ 1336 MO_Charisma_FahrPr 0 "nicht_belegt" 1 "Programm_1" 2 "Programm_2" 3 "Programm_3" 4 "Programm_4" 5 "Programm_5" 6 "Programm_6" 7 "Programm_7" ;
VAL_ 1336 MO_Charisma_Status 0 "Init" 1 "verfuegbar" 2 "nicht_verfuegbar" 3 "asynchron_durch_Fahrerwunsch" ;
VAL_ 1336 MO_Charisma_Umschaltung 0 "Idle" 1 "Erkennung_Umschaltaufforderung" 2 "Steuerbotschaft_nicht_definiert" 3 "Umschaltung_verzoegert" ;
VAL_ 1336 Motor_05_alt 0 "aktuell" 1 "veraltet" ;
VAL_ 1336 GE_Charisma_FahrPr 0 "nicht_belegt" 1 "Programm_1" 2 "Programm_2" 3 "Programm_3" 4 "Programm_4" 5 "Programm_5" 6 "Programm_6" 7 "Programm_7" ;
VAL_ 1336 GE_Charisma_Status 0 "Init" 1 "verfuegbar" 2 "nicht_verfuegbar" 3 "asynchron_durch_Fahrerwunsch" ;
VAL_ 1336 GE_Charisma_Umschaltung 0 "Idle" 1 "Erkennung_Umschaltaufforderung" 2 "Steuerbotschaft_nicht_definiert" 3 "Umschaltung_verzoegert" ;
VAL_ 1336 Getriebe_04_alt 0 "aktuell" 1 "veraltet" ;
VAL_ 1336 SCU_Charisma_FahrPr 0 "nicht_belegt" 1 "Programm_1" 2 "Programm_2" 3 "Programm_3" 4 "Programm_4" 5 "Programm_5" 6 "Programm_6" 7 "Programm_7" ;
VAL_ 1336 SCU_Charisma_Status 0 "Init" 1 "verfuegbar" 2 "nicht_verfuegbar" 3 "asynchron_durch_Fahrerwunsch" ;
VAL_ 1336 SCU_Charisma_Umschaltung 0 "Idle" 1 "Erkennung_Umschaltaufforderung" 2 "Steuerbotschaft_nicht_definiert" 3 "Umschaltung_verzoegert" ;
VAL_ 1336 SCU_02_alt 0 "aktuell" 1 "veraltet" ;
VAL_ 1336 ST_Charisma_FahrPr 0 "nicht_belegt" 1 "Programm_1" 2 "Programm_2" 3 "Programm_3" 4 "Programm_4" 5 "Programm_5" 6 "Programm_6" 7 "Programm_7" ;
VAL_ 1336 ST_Charisma_Status 0 "Init" 1 "verfuegbar" 2 "nicht_verfuegbar" 3 "asynchron_durch_Fahrerwunsch" ;
VAL_ 1336 ST_Charisma_Umschaltung 0 "Idle" 1 "Erkennung_Umschaltaufforderung" 2 "Steuerbotschaft_nicht_definiert" 3 "Umschaltung_verzoegert" ;
VAL_ 1336 BCM1_01_alt 0 "aktuell" 1 "veraltet" ;
VAL_ 1336 DR_Charisma_FahrPr 0 "nicht_belegt" 1 "Programm_1" 2 "Programm_2" 3 "Programm_3" 4 "Programm_4" 5 "Programm_5" 6 "Programm_6" 7 "Programm_7" ;
VAL_ 1336 DR_Charisma_Status 0 "Init" 1 "verfuegbar" 2 "nicht_verfuegbar" 3 "asynchron_durch_Fahrerwunsch" ;
VAL_ 1336 DR_Charisma_Umschaltung 0 "Idle" 1 "Erkennung_Umschaltaufforderung" 2 "Steuerbotschaft_nicht_definiert" 3 "Umschaltung_verzoegert" ;
VAL_ 1336 Daempfer_01_alt 0 "aktuell" 1 "veraltet" ;
VAL_ 1336 QSP_Charisma_FahrPr 0 "nicht_belegt" 1 "Programm_1" 2 "Programm_2" 3 "Programm_3" 4 "Programm_4" 5 "Programm_5" 6 "Programm_6" 7 "Programm_7" ;
VAL_ 1336 QSP_Charisma_Status 0 "Init" 1 "verfuegbar" 2 "nicht_verfuegbar" 3 "asynchron_durch_Fahrerwunsch" ;
VAL_ 1336 QSP_Charisma_Umschaltung 0 "Idle" 1 "Erkennung_Umschaltaufforderung" 2 "Steuerbotschaft_nicht_definiert" 3 "Umschaltung_verzoegert" ;
VAL_ 1336 QSP_01_alt 0 "aktuell" 1 "veraltet" ;
VAL_ 1336 RGS_VL_Charisma_FahrPr 0 "nicht_belegt" 1 "Programm_1" 2 "Programm_2" 3 "Programm_3" 4 "Programm_4" 5 "Programm_5" 6 "Programm_6" 7 "Programm_7" ;
VAL_ 1336 RGS_VL_Charisma_Status 0 "Init" 1 "verfuegbar" 2 "nicht_verfuegbar" 3 "asynchron_durch_Fahrerwunsch" ;
VAL_ 1336 RGS_VL_Charisma_Umschaltung 0 "Idle" 1 "Erkennung_Umschaltaufforderung" 2 "Steuerbotschaft_nicht_definiert" 3 "Umschaltung_verzoegert" ;
VAL_ 1336 RGS_VL_01_alt 0 "aktuell" 1 "veraltet" ;
VAL_ 1336 AFS_Charisma_FahrPr 0 "nicht_belegt" 1 "Programm_1" 2 "Programm_2" 3 "Programm_3" 4 "Programm_4" 5 "Programm_5" 6 "Programm_6" 7 "Programm_7" ;
VAL_ 1336 AFS_Charisma_Status 0 "Init" 1 "verfuegbar" 2 "nicht_verfuegbar" 3 "asynchron_durch_Fahrerwunsch" ;
VAL_ 1336 AFS_Charisma_Umschaltung 0 "Idle" 1 "Erkennung_Umschaltaufforderung" 2 "Steuerbotschaft_nicht_definiert" 3 "Umschaltung_verzoegert" ;
VAL_ 1336 AFS_01_alt 0 "aktuell" 1 "veraltet" ;
VAL_ 1338 EPS_Charisma_FahrPr 0 "nicht_belegt" 1 "Programm_1" 2 "Programm_2" 3 "Programm_3" 4 "Programm_4" 5 "Programm_5" 6 "Programm_6" 7 "Programm_7" ;
VAL_ 1338 EPS_Charisma_Status 0 "Init" 1 "verfuegbar" 2 "nicht_verfuegbar" 3 "asynchron_durch_Fahrerwunsch" ;
VAL_ 1338 EPS_Charisma_Umschaltung 0 "Idle" 1 "Erkennung_Umschaltaufforderung" 2 "Steuerbotschaft_nicht_definiert" 3 "Umschaltung_verzoegert" ;
VAL_ 1338 EPS_FR_alt 0 "aktuell" 1 "veraltet" ;
VAL_ 1338 ACC_Charisma_FahrPr 0 "nicht_belegt" 1 "Programm_1" 2 "Programm_2" 3 "Programm_3" 4 "Programm_4" 5 "Programm_5" 6 "Programm_6" 7 "Programm_7" ;
VAL_ 1338 ACC_Charisma_Status 0 "Init" 1 "verfuegbar" 2 "nicht_verfuegbar" 3 "asynchron_durch_Fahrerwunsch" ;
VAL_ 1338 ACC_Charisma_Umschaltung 0 "Idle" 1 "Erkennung_Umschaltaufforderung" 2 "Steuerbotschaft_nicht_definiert" 3 "Umschaltung_verzoegert" ;
VAL_ 1338 ACC_04_alt 0 "aktuell" 1 "veraltet" ;
VAL_ 1338 SAK_Charisma_FahrPr 0 "nicht_belegt" 1 "Programm_1" 2 "Programm_2" 3 "Programm_3" 4 "Programm_4" 5 "Programm_5" 6 "Programm_6" 7 "Programm_7" ;
VAL_ 1338 SAK_Charisma_Status 0 "Init" 1 "verfuegbar" 2 "nicht_verfuegbar" 3 "asynchron_durch_Fahrerwunsch" ;
VAL_ 1338 SAK_Charisma_Umschaltung 0 "Idle" 1 "Erkennung_Umschaltaufforderung" 2 "Steuerbotschaft_nicht_definiert" 3 "Umschaltung_verzoegert" ;
VAL_ 1338 SAK_01_alt 0 "aktuell" 1 "veraltet" ;
VAL_ 1338 NR_Niveaufunktion_aktiv 0 "keine_Umschaltung_erfolgt" 3 "lift_aktiv" ;
VAL_ 1338 Daempfer_01_alt 0 "aktuell" 1 "veraltet" ;
